VERSION ""

NS_ :

BS_:

BU_: WPC2 PSB SHVU_RR vHS_B2 FCS EMCU SLB GW_APSU GW_DLBCU RCM ARS CGW_CCU vDummy_HS_B GW_RLPSU ATS RLHV SGU PFSU GW_RRPSU ALBCU DSAU SWRC SHVU_FR RCS GW_DPSU BLTN_CAM SCM OHCL RWPC RRHV WPC HOD ASAU

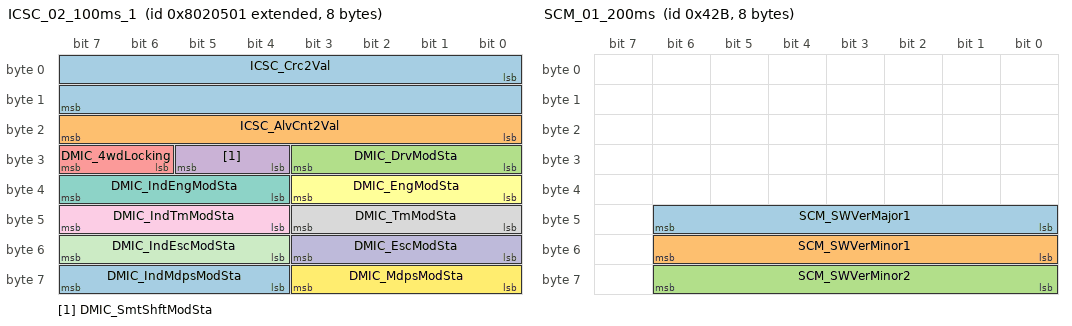
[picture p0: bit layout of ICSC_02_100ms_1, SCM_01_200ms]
BO_ 2281833729 ICSC_02_100ms_1: 8 CGW_CCU
 SG_ ICSC_Crc2Val : 0|16@1+ (1,0) [0|0] ""  Vector__XXX
 SG_ ICSC_AlvCnt2Val : 16|8@1+ (1,0) [0|0] ""  Vector__XXX
 SG_ DMIC_DrvModSta : 24|4@1+ (1,0) [0|0] ""  ALBCU,ASAU,DSAU,GW_APSU,GW_DLBCU
 SG_ DMIC_SmtShftModSta : 28|2@1+ (1,0) [0|0] ""  Vector__XXX
 SG_ DMIC_4wdLocking : 30|2@1+ (1,0) [0|0] ""  Vector__XXX
 SG_ DMIC_EngModSta : 32|4@1+ (1,0) [0|0] ""  Vector__XXX
 SG_ DMIC_IndEngModSta : 36|4@1+ (1,0) [0|0] ""  Vector__XXX
 SG_ DMIC_TmModSta : 40|4@1+ (1,0) [0|0] ""  Vector__XXX
 SG_ DMIC_IndTmModSta : 44|4@1+ (1,0) [0|0] ""  Vector__XXX
 SG_ DMIC_EscModSta : 48|4@1+ (1,0) [0|0] ""  Vector__XXX
 SG_ DMIC_IndEscModSta : 52|4@1+ (1,0) [0|0] ""  Vector__XXX
 SG_ DMIC_MdpsModSta : 56|4@1+ (1,0) [0|0] ""  Vector__XXX
 SG_ DMIC_IndMdpsModSta : 60|4@1+ (1,0) [0|0] ""  Vector__XXX

BO_ 1067 SCM_01_200ms: 8 SCM
 SG_ SCM_SWVerMajor1 : 40|7@1+ (1,0) [0|0] ""  CGW_CCU
 SG_ SCM_SWVerMinor1 : 48|7@1+ (1,0) [0|0] ""  CGW_CCU
 SG_ SCM_SWVerMinor2 : 56|7@1+ (1,0) [0|0] ""  CGW_CCU

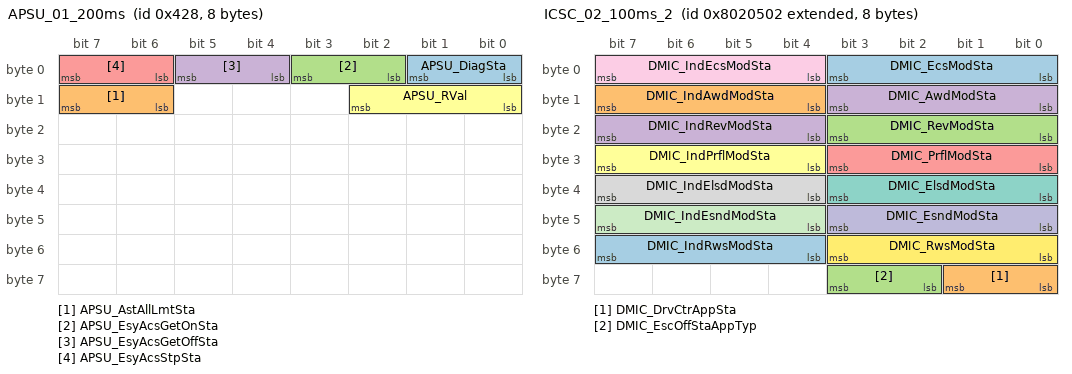
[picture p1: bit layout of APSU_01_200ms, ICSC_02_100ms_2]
BO_ 1064 APSU_01_200ms: 8 GW_APSU
 SG_ APSU_DiagSta : 0|2@1+ (1,0) [0|0] ""  Vector__XXX
 SG_ APSU_AstAllLmtSta : 14|2@1+ (1,0) [0|0] ""  Vector__XXX
 SG_ APSU_EsyAcsGetOnSta : 2|2@1+ (1,0) [0|0] ""  ALBCU,GW_RLPSU,GW_RRPSU
 SG_ APSU_EsyAcsGetOffSta : 4|2@1+ (1,0) [0|0] ""  ALBCU,GW_RLPSU,GW_RRPSU
 SG_ APSU_EsyAcsStpSta : 6|2@1+ (1,0) [0|0] ""  ALBCU,GW_RLPSU,GW_RRPSU
 SG_ APSU_RVal : 8|3@1+ (1,0) [0|0] ""  Vector__XXX

BO_ 2281833731 ICSC_02_100ms_3: 8 CGW_CCU
 SG_ DMIC_VcuModSta : 0|4@1+ (1,0) [0|0] ""  Vector__XXX
 SG_ DMIC_DrvModTyp : 12|4@1+ (1,0) [0|0] ""  Vector__XXX
 SG_ DMIC_EngFltSta : 16|2@1+ (1,0) [0|0] ""  Vector__XXX
 SG_ DMIC_TmFltSta : 18|2@1+ (1,0) [0|0] ""  Vector__XXX
 SG_ DMIC_EscFltSta : 20|2@1+ (1,0) [0|0] ""  Vector__XXX
 SG_ DMIC_MdpsFltSta : 22|2@1+ (1,0) [0|0] ""  Vector__XXX
 SG_ DMIC_EcsFltSta : 24|2@1+ (1,0) [0|0] ""  Vector__XXX
 SG_ DMIC_AwdFltSta : 26|2@1+ (1,0) [0|0] ""  Vector__XXX
 SG_ DMIC_RevFltSta : 28|2@1+ (1,0) [0|0] ""  Vector__XXX
 SG_ DMIC_PrflFltSta : 30|2@1+ (1,0) [0|0] ""  Vector__XXX
 SG_ DMIC_ElsdFltSta : 32|2@1+ (1,0) [0|0] ""  Vector__XXX
 SG_ DMIC_EsndFltSta : 34|2@1+ (1,0) [0|0] ""  Vector__XXX
 SG_ DMIC_RwsFltSta : 36|2@1+ (1,0) [0|0] ""  Vector__XXX
 SG_ DMIC_IndWhlDrvSta : 38|2@1+ (1,0) [0|0] ""  Vector__XXX
 SG_ DMIC_IndVcuModSta : 4|4@1+ (1,0) [0|0] ""  Vector__XXX
 SG_ DMIC_VcuFltSta : 40|2@1+ (1,0) [0|0] ""  Vector__XXX
 SG_ DMIC_IndMtrPwrSta : 42|3@1+ (1,0) [0|0] ""  Vector__XXX
 SG_ DMIC_IndAccSenSta : 45|3@1+ (1,0) [0|0] ""  Vector__XXX
 SG_ DMIC_TerrainModSwSta : 48|3@1+ (1,0) [0|0] ""  Vector__XXX
 SG_ DMIC_TerrainMainSwSta : 52|2@1+ (1,0) [0|0] ""  Vector__XXX
 SG_ DMIC_DrvModTypSta : 54|2@1+ (1,0) [0|0] ""  Vector__XXX
 SG_ DMIC_DrvngModSwSta : 56|4@1+ (1,0) [0|0] ""  Vector__XXX
 SG_ DMIC_DrvMod2Typ : 60|4@1+ (1,0) [0|0] ""  Vector__XXX
 SG_ DMIC_DrvModFltSta : 8|4@1+ (1,0) [0|0] ""  Vector__XXX

BO_ 2281833730 ICSC_02_100ms_2: 8 CGW_CCU
 SG_ DMIC_EcsModSta : 0|4@1+ (1,0) [0|0] ""  Vector__XXX
 SG_ DMIC_IndAwdModSta : 12|4@1+ (1,0) [0|0] ""  Vector__XXX
 SG_ DMIC_RevModSta : 16|4@1+ (1,0) [0|0] ""  Vector__XXX
 SG_ DMIC_IndRevModSta : 20|4@1+ (1,0) [0|0] ""  Vector__XXX
 SG_ DMIC_PrflModSta : 24|4@1+ (1,0) [0|0] ""  Vector__XXX
 SG_ DMIC_IndPrflModSta : 28|4@1+ (1,0) [0|0] ""  Vector__XXX
 SG_ DMIC_ElsdModSta : 32|4@1+ (1,0) [0|0] ""  Vector__XXX
 SG_ DMIC_IndElsdModSta : 36|4@1+ (1,0) [0|0] ""  Vector__XXX
 SG_ DMIC_IndEcsModSta : 4|4@1+ (1,0) [0|0] ""  Vector__XXX
 SG_ DMIC_EsndModSta : 40|4@1+ (1,0) [0|0] ""  Vector__XXX
 SG_ DMIC_IndEsndModSta : 44|4@1+ (1,0) [0|0] ""  Vector__XXX
 SG_ DMIC_RwsModSta : 48|4@1+ (1,0) [0|0] ""  Vector__XXX
 SG_ DMIC_IndRwsModSta : 52|4@1+ (1,0) [0|0] ""  Vector__XXX
 SG_ DMIC_DrvCtrAppSta : 56|2@1+ (1,0) [0|0] ""  Vector__XXX
 SG_ DMIC_EscOffStaAppTyp : 58|2@1+ (1,0) [0|0] ""  Vector__XXX
 SG_ DMIC_AwdModSta : 8|4@1+ (1,0) [0|0] ""  Vector__XXX

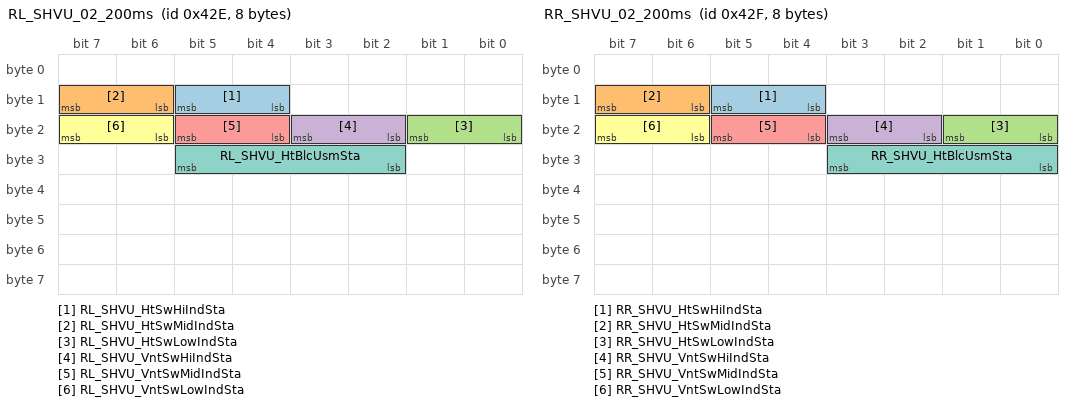
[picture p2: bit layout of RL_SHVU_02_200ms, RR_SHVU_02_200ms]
BO_ 1070 RL_SHVU_02_200ms: 8 GW_RLPSU
 SG_ RL_SHVU_HtSwHiIndSta : 12|2@1+ (1,0) [0|0] ""  ARS,ATS,CGW_CCU
 SG_ RL_SHVU_HtSwMidIndSta : 14|2@1+ (1,0) [0|0] ""  ARS,ATS,CGW_CCU
 SG_ RL_SHVU_HtSwLowIndSta : 16|2@1+ (1,0) [0|0] ""  ARS,ATS,CGW_CCU
 SG_ RL_SHVU_VntSwHiIndSta : 18|2@1+ (1,0) [0|0] ""  ARS,ATS,CGW_CCU
 SG_ RL_SHVU_VntSwMidIndSta : 20|2@1+ (1,0) [0|0] ""  ARS,ATS,CGW_CCU
 SG_ RL_SHVU_VntSwLowIndSta : 22|2@1+ (1,0) [0|0] ""  ARS,ATS,CGW_CCU
 SG_ RL_SHVU_HtBlcUsmSta : 26|4@1+ (1,0) [0|0] ""  ATS,CGW_CCU

BO_ 1071 RR_SHVU_02_200ms: 8 GW_RRPSU
 SG_ RR_SHVU_HtSwHiIndSta : 12|2@1+ (1,0) [0|0] ""  ARS,ATS,CGW_CCU
 SG_ RR_SHVU_HtSwMidIndSta : 14|2@1+ (1,0) [0|0] ""  ARS,ATS,CGW_CCU
 SG_ RR_SHVU_HtSwLowIndSta : 16|2@1+ (1,0) [0|0] ""  ARS,ATS,CGW_CCU
 SG_ RR_SHVU_VntSwHiIndSta : 18|2@1+ (1,0) [0|0] ""  ARS,ATS,CGW_CCU
 SG_ RR_SHVU_VntSwMidIndSta : 20|2@1+ (1,0) [0|0] ""  ARS,ATS,CGW_CCU
 SG_ RR_SHVU_VntSwLowIndSta : 22|2@1+ (1,0) [0|0] ""  ARS,ATS,CGW_CCU
 SG_ RR_SHVU_HtBlcUsmSta : 24|4@1+ (1,0) [0|0] ""  ATS,CGW_CCU

BO_ 1068 RLPSU_04_200ms: 8 RLHV
 SG_ RLPSU_ReclMtrPos : 0|3@1+ (1,0) [0|0] ""  PFSU
 SG_ RLPSU_RLSlidPos : 11|3@1+ (1,0) [0|0] ""  CGW_CCU
 SG_ RLPSU_RLRclPos : 14|3@1+ (1,0) [0|0] ""  CGW_CCU
 SG_ RLPSU_RLTiltPos : 17|3@1+ (1,0) [0|0] ""  CGW_CCU
 SG_ RLPSU_RLLegExtPos : 20|3@1+ (1,0) [0|0] ""  CGW_CCU
 SG_ RLPSU_RLLegSupPos : 23|3@1+ (1,0) [0|0] ""  CGW_CCU
 SG_ RLPSU_RLHrestSlidPos : 26|3@1+ (1,0) [0|0] ""  CGW_CCU
 SG_ RLPSU_RLHrestHeightPos : 29|3@1+ (1,0) [0|0] ""  CGW_CCU
 SG_ RLPSU_Opt : 3|2@1+ (1,0) [0|0] ""  CGW_CCU
 SG_ RLPSU_Opt_Captain : 32|2@1+ (1,0) [0|0] ""  CGW_CCU
 SG_ RL_AutoRlxSta : 34|2@1+ (1,0) [0|0] ""  GW_APSU,GW_DPSU,PFSU
 SG_ RL_FLStAutoRlxEnable : 36|2@1+ (1,0) [0|0] ""  GW_APSU,GW_DPSU
 SG_ RLHVU_Opt_Captain : 38|3@1+ (1,0) [0|0] ""  CGW_CCU
 SG_ RL_TLAutoFldEnable : 45|2@1+ (1,0) [0|0] ""  PFSU
 SG_ RL_AutoFoldSta : 47|2@1+ (1,0) [0|0] ""  GW_APSU,GW_DPSU
 SG_ RL_AutoWalkInSta : 49|2@1+ (1,0) [0|0] ""  GW_APSU,GW_DPSU
 SG_ RLPSU_PwrSeatOpt : 5|3@1+ (1,0) [0|0] ""  CGW_CCU
 SG_ RLPSU_PwrSeatPos : 8|3@1+ (1,0) [0|0] ""  CGW_CCU

BO_ 1069 RRPSU_04_200ms: 8 GW_RRPSU
 SG_ RRPSU_ReclMtrPos : 0|3@1+ (1,0) [0|0] ""  PFSU
 SG_ RRPSU_PwrSeatOpt : 11|3@1+ (1,0) [0|0] ""  CGW_CCU
 SG_ RRPSU_PwrSeatPos : 14|3@1+ (1,0) [0|0] ""  CGW_CCU
 SG_ RRPSU_RRSlidPos : 17|3@1+ (1,0) [0|0] ""  CGW_CCU
 SG_ RRPSU_RRRclPos : 20|3@1+ (1,0) [0|0] ""  CGW_CCU
 SG_ RRPSU_RRTiltPos : 23|3@1+ (1,0) [0|0] ""  CGW_CCU
 SG_ RRPSU_RRLegExtPos : 26|3@1+ (1,0) [0|0] ""  CGW_CCU
 SG_ RRPSU_RRLegSupPos : 29|3@1+ (1,0) [0|0] ""  CGW_CCU
 SG_ RRPSU_RRStEsyAcsUSMSta : 3|3@1+ (1,0) [0|0] ""  CGW_CCU
 SG_ RRPSU_RRHrestSlidPos : 32|3@1+ (1,0) [0|0] ""  CGW_CCU
 SG_ RRPSU_RRHrestHeightPos : 35|3@1+ (1,0) [0|0] ""  CGW_CCU
 SG_ RRPSU_Opt_Captain : 38|2@1+ (1,0) [0|0] ""  CGW_CCU
 SG_ RR_AutoRlxSta : 40|2@1+ (1,0) [0|0] ""  GW_APSU,GW_DPSU,PFSU
 SG_ RR_FRStAutoRlxEnable : 42|2@1+ (1,0) [0|0] ""  GW_APSU,GW_DPSU
 SG_ RRHVU_Opt_Captain : 44|3@1+ (1,0) [0|0] ""  CGW_CCU
 SG_ RR_AutoFoldSta : 51|2@1+ (1,0) [0|0] ""  GW_APSU,GW_DPSU
 SG_ RR_AutoWalkInSta : 53|2@1+ (1,0) [0|0] ""  GW_APSU,GW_DPSU
 SG_ RR_TRAutoFldEnable : 55|2@1+ (1,0) [0|0] ""  PFSU
 SG_ RRPSU_RLStEsyAcsUSMSta : 6|3@1+ (1,0) [0|0] ""  CGW_CCU
 SG_ RRPSU_Opt : 9|2@1+ (1,0) [0|0] ""  CGW_CCU

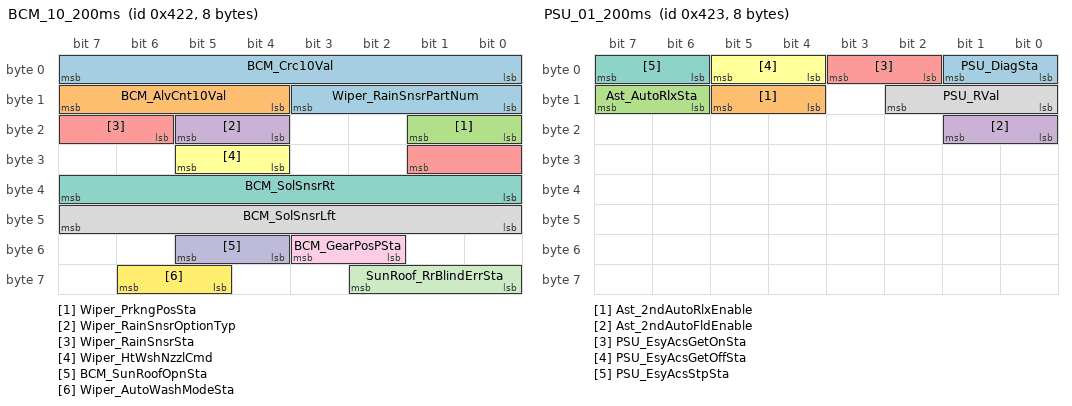
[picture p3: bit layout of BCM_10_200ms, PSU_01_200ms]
BO_ 1058 BCM_10_200ms: 8 CGW_CCU
 SG_ BCM_Crc10Val : 0|8@1+ (1,0) [0|0] ""  Vector__XXX
 SG_ BCM_AlvCnt10Val : 12|4@1+ (1,0) [0|0] ""  Vector__XXX
 SG_ Wiper_PrkngPosSta : 16|2@1+ (1,0) [0|0] ""  BLTN_CAM
 SG_ Wiper_RainSnsrOptionTyp : 20|2@1+ (1,0) [0|0] ""  Vector__XXX
 SG_ Wiper_RainSnsrSta : 22|4@1+ (1,0) [0|0] ""  BLTN_CAM
 SG_ Wiper_HtWshNzzlCmd : 28|2@1+ (1,0) [0|0] ""  Vector__XXX
 SG_ BCM_SolSnsrRt : 32|8@1+ (4.72441,0) [0|0] "W/m2"  Vector__XXX
 SG_ BCM_SolSnsrLft : 40|8@1+ (4.72441,0) [0|0] "W/m2"  Vector__XXX
 SG_ BCM_GearPosPSta : 50|2@1+ (1,0) [0|0] ""  ATS,GW_APSU,GW_DPSU,GW_RLPSU,GW_RRPSU,PFSU,RLHV,RRHV,SCM
 SG_ BCM_SunRoofOpnSta : 52|2@1+ (1,0) [0|0] ""  Vector__XXX
 SG_ SunRoof_RrBlindErrSta : 56|3@1+ (1,0) [0|0] ""  Vector__XXX
 SG_ Wiper_AutoWashModeSta : 61|2@1+ (1,0) [0|0] ""  Vector__XXX
 SG_ Wiper_RainSnsrPartNum : 8|4@1+ (1,0) [0|0] ""  Vector__XXX

BO_ 1059 PSU_01_200ms: 8 GW_APSU
 SG_ PSU_DiagSta : 0|2@1+ (1,0) [0|0] ""  Vector__XXX
 SG_ Ast_2ndAutoRlxEnable : 12|2@1+ (1,0) [0|0] ""  GW_RLPSU,GW_RRPSU
 SG_ Ast_AutoRlxSta : 14|2@1+ (1,0) [0|0] ""  GW_RLPSU,GW_RRPSU
 SG_ Ast_2ndAutoFldEnable : 16|2@1+ (1,0) [0|0] ""  GW_RLPSU,GW_RRPSU
 SG_ PSU_EsyAcsGetOnSta : 2|2@1+ (1,0) [0|0] ""  SLB
 SG_ PSU_EsyAcsGetOffSta : 4|2@1+ (1,0) [0|0] ""  SLB
 SG_ PSU_EsyAcsStpSta : 6|2@1+ (1,0) [0|0] ""  SLB
 SG_ PSU_RVal : 8|3@1+ (1,0) [0|0] ""  Vector__XXX

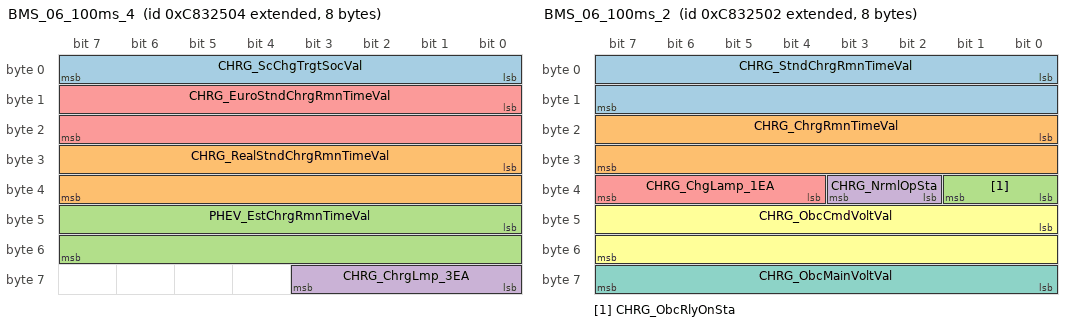
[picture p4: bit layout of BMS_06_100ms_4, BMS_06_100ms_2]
BO_ 2357404932 BMS_06_100ms_4: 8 CGW_CCU
 SG_ CHRG_ScChgTrgtSocVal : 0|8@1+ (0.5,0) [0|0] "%"  Vector__XXX
 SG_ CHRG_RealStndChrgRmnTimeVal : 24|16@1+ (1,0) [0|0] "minute"  Vector__XXX
 SG_ PHEV_EstChrgRmnTimeVal : 40|16@1+ (1,0) [0|0] "min"  Vector__XXX
 SG_ CHRG_ChrgLmp_3EA : 56|4@1+ (1,0) [0|0] "minute"  Vector__XXX
 SG_ CHRG_EuroStndChrgRmnTimeVal : 8|16@1+ (1,0) [0|0] "minute"  Vector__XXX

BO_ 2357404930 BMS_06_100ms_2: 8 CGW_CCU
 SG_ CHRG_StndChrgRmnTimeVal : 0|16@1+ (1,0) [0|0] "minute"  Vector__XXX
 SG_ CHRG_ChrgRmnTimeVal : 16|16@1+ (1,0) [0|0] "min"  Vector__XXX
 SG_ CHRG_ObcRlyOnSta : 32|2@1+ (1,0) [0|0] ""  Vector__XXX
 SG_ CHRG_NrmlOpSta : 34|2@1+ (1,0) [0|0] ""  Vector__XXX
 SG_ CHRG_ChgLamp_1EA : 36|4@1+ (1,0) [0|0] ""  Vector__XXX
 SG_ CHRG_ObcCmdVoltVal : 40|16@1+ (0.1,0) [0|0] "V"  Vector__XXX
 SG_ CHRG_ObcMainVoltVal : 56|8@1+ (2,0) [0|0] "V"  Vector__XXX

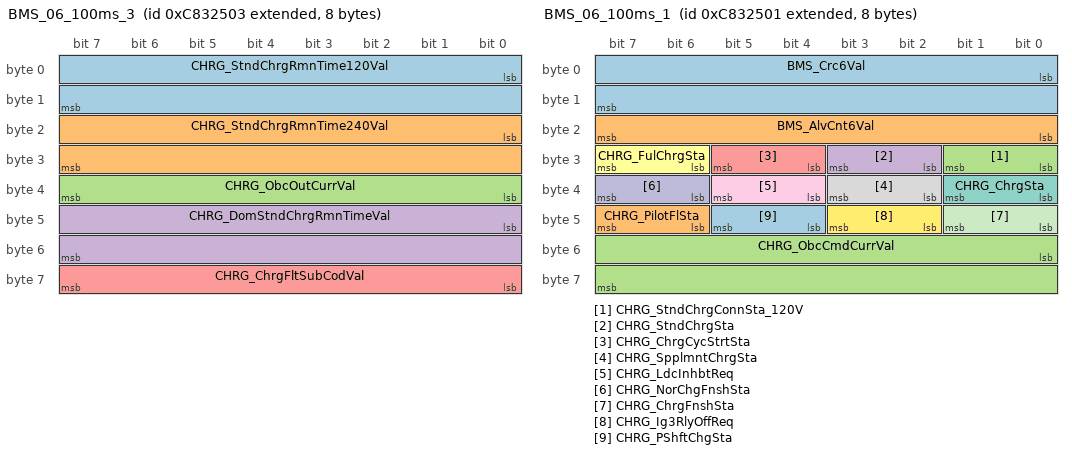
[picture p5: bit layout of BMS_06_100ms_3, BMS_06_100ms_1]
BO_ 2357404931 BMS_06_100ms_3: 8 CGW_CCU
 SG_ CHRG_StndChrgRmnTime120Val : 0|16@1+ (1,0) [0|0] "minute"  Vector__XXX
 SG_ CHRG_StndChrgRmnTime240Val : 16|16@1+ (1,0) [0|0] "minute"  Vector__XXX
 SG_ CHRG_ObcOutCurrVal : 32|8@1+ (0.1,0) [0|0] "A"  Vector__XXX
 SG_ CHRG_DomStndChrgRmnTimeVal : 40|16@1+ (1,0) [0|0] "minute"  Vector__XXX
 SG_ CHRG_ChrgFltSubCodVal : 56|8@1+ (1,0) [0|0] ""  Vector__XXX

BO_ 2357404929 BMS_06_100ms_1: 8 CGW_CCU
 SG_ BMS_Crc6Val : 0|16@1+ (1,0) [0|0] ""  Vector__XXX
 SG_ BMS_AlvCnt6Val : 16|8@1+ (1,0) [0|0] ""  Vector__XXX
 SG_ CHRG_StndChrgConnSta_120V : 24|2@1+ (1,0) [0|0] "flag"  Vector__XXX
 SG_ CHRG_StndChrgSta : 26|2@1+ (1,0) [0|0] ""  Vector__XXX
 SG_ CHRG_ChrgCycStrtSta : 28|2@1+ (1,0) [0|0] ""  Vector__XXX
 SG_ CHRG_FulChrgSta : 30|2@1+ (1,0) [0|0] ""  Vector__XXX
 SG_ CHRG_ChrgSta : 32|2@1+ (1,0) [0|0] ""  SWRC
 SG_ CHRG_SpplmntChrgSta : 34|2@1+ (1,0) [0|0] ""  Vector__XXX
 SG_ CHRG_LdcInhbtReq : 36|2@1+ (1,0) [0|0] ""  Vector__XXX
 SG_ CHRG_NorChgFnshSta : 38|2@1+ (1,0) [0|0] ""  Vector__XXX
 SG_ CHRG_ChrgFnshSta : 40|2@1+ (1,0) [0|0] ""  Vector__XXX
 SG_ CHRG_Ig3RlyOffReq : 42|2@1+ (1,0) [0|0] ""  Vector__XXX
 SG_ CHRG_PShftChgSta : 44|2@1+ (1,0) [0|0] "flag"  Vector__XXX
 SG_ CHRG_PilotFlSta : 46|2@1+ (1,0) [0|0] "flag"  Vector__XXX
 SG_ CHRG_ObcCmdCurrVal : 48|16@1+ (0.1,0) [0|0] "A"  Vector__XXX

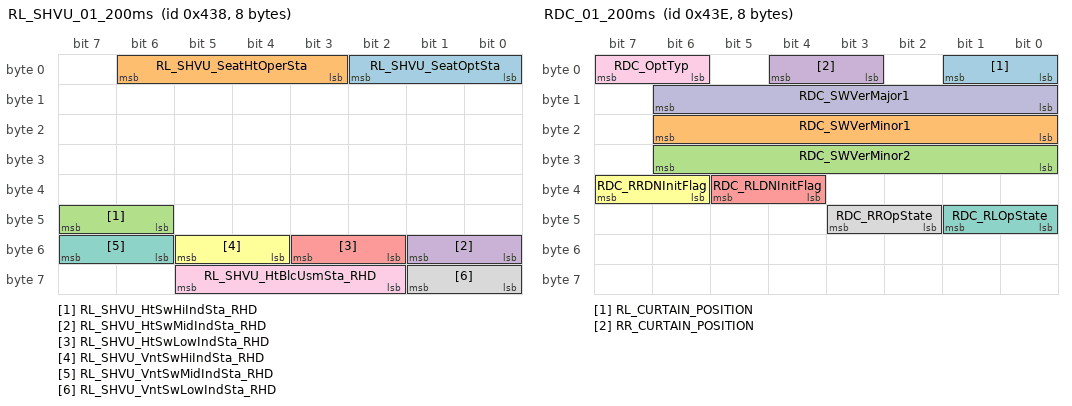
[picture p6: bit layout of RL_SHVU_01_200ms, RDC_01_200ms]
BO_ 1080 RL_SHVU_01_200ms: 8 SHVU_RR
 SG_ RL_SHVU_SeatOptSta : 0|3@1+ (1,0) [0|0] ""  ATS,CGW_CCU
 SG_ RL_SHVU_SeatHtOperSta : 3|4@1+ (1,0) [0|0] ""  ATS,CGW_CCU,FCS
 SG_ RL_SHVU_HtSwHiIndSta_RHD : 46|2@1+ (1,0) [0|0] ""  ATS,CGW_CCU
 SG_ RL_SHVU_HtSwMidIndSta_RHD : 48|2@1+ (1,0) [0|0] ""  ATS,CGW_CCU
 SG_ RL_SHVU_HtSwLowIndSta_RHD : 50|2@1+ (1,0) [0|0] ""  ATS,CGW_CCU
 SG_ RL_SHVU_VntSwHiIndSta_RHD : 52|2@1+ (1,0) [0|0] ""  ATS,CGW_CCU
 SG_ RL_SHVU_VntSwMidIndSta_RHD : 54|2@1+ (1,0) [0|0] ""  ATS,CGW_CCU
 SG_ RL_SHVU_VntSwLowIndSta_RHD : 56|2@1+ (1,0) [0|0] ""  ATS,CGW_CCU
 SG_ RL_SHVU_HtBlcUsmSta_RHD : 58|4@1+ (1,0) [0|0] ""  ATS,CGW_CCU

BO_ 1086 RDC_01_200ms: 8 CGW_CCU
 SG_ RL_CURTAIN_POSITION : 0|2@1+ (1,0) [0|0] ""  ATS
 SG_ RDC_SWVerMinor1 : 16|7@1+ (1,0) [0|0] ""  Vector__XXX
 SG_ RDC_SWVerMinor2 : 24|7@1+ (1,0) [0|0] ""  Vector__XXX
 SG_ RR_CURTAIN_POSITION : 3|2@1+ (1,0) [0|0] ""  ATS
 SG_ RDC_RLDNInitFlag : 36|2@1+ (1,0) [0|0] ""  Vector__XXX
 SG_ RDC_RRDNInitFlag : 38|2@1+ (1,0) [0|0] ""  Vector__XXX
 SG_ RDC_RLOpState : 40|2@1+ (1,0) [0|0] ""  Vector__XXX
 SG_ RDC_RROpState : 42|2@1+ (1,0) [0|0] ""  Vector__XXX
 SG_ RDC_OptTyp : 6|2@1+ (1,0) [0|0] ""  ATS
 SG_ RDC_SWVerMajor1 : 8|7@1+ (1,0) [0|0] ""  Vector__XXX

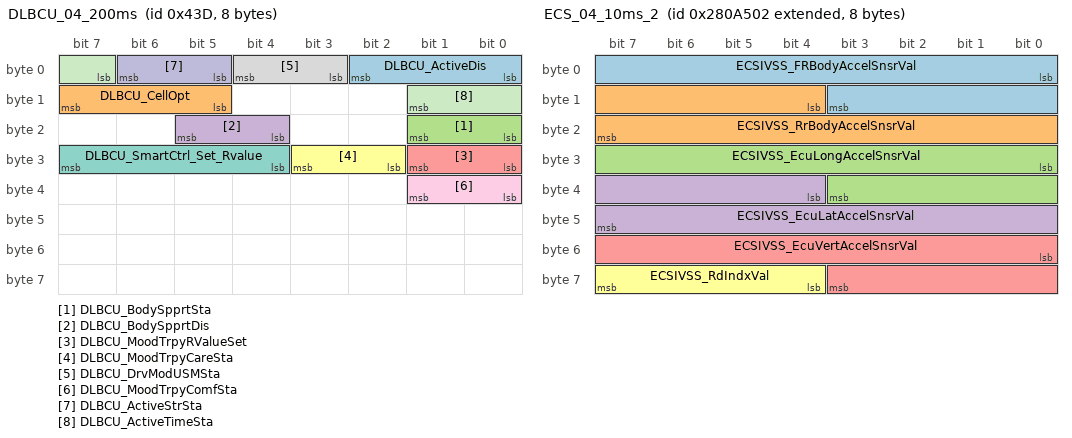
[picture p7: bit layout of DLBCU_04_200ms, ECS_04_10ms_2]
BO_ 1085 DLBCU_04_200ms: 8 GW_DLBCU
 SG_ DLBCU_ActiveDis : 0|3@1+ (1,0) [0|0] ""  CGW_CCU,GW_DPSU
 SG_ DLBCU_CellOpt : 13|3@1+ (1,0) [0|0] ""  Vector__XXX
 SG_ DLBCU_BodySpprtSta : 16|2@1+ (1,0) [0|0] ""  CGW_CCU
 SG_ DLBCU_BodySpprtDis : 20|2@1+ (1,0) [0|0] ""  CGW_CCU
 SG_ DLBCU_MoodTrpyRValueSet : 24|2@1+ (1,0) [0|0] ""  CGW_CCU
 SG_ DLBCU_MoodTrpyCareSta : 26|2@1+ (1,0) [0|0] ""  CGW_CCU
 SG_ DLBCU_SmartCtrl_Set_Rvalue : 28|4@1+ (1,0) [0|0] ""  CGW_CCU
 SG_ DLBCU_DrvModUSMSta : 3|2@1+ (1,0) [0|0] ""  CGW_CCU
 SG_ DLBCU_MoodTrpyComfSta : 32|2@1+ (1,0) [0|0] ""  CGW_CCU
 SG_ DLBCU_ActiveStrSta : 5|2@1+ (1,0) [0|0] ""  CGW_CCU
 SG_ DLBCU_ActiveTimeSta : 7|3@1+ (1,0) [0|0] ""  CGW_CCU

BO_ 2189468930 ECS_04_10ms_2: 8 CGW_CCU
 SG_ ECSIVSS_FRBodyAccelSnsrVal : 0|12@1+ (0.002442,-1.250304) [0|0] "g"  Vector__XXX
 SG_ ECSIVSS_RrBodyAccelSnsrVal : 12|12@1+ (0.002442,-1.250304) [0|0] "g"  Vector__XXX
 SG_ ECSIVSS_EcuLongAccelSnsrVal : 24|12@1+ (0.01,-20.48) [0|0] "m/s^2"  Vector__XXX
 SG_ ECSIVSS_EcuLatAccelSnsrVal : 36|12@1+ (0.01,-20.48) [0|0] "m/s^2"  Vector__XXX
 SG_ ECSIVSS_EcuVertAccelSnsrVal : 48|12@1+ (0.01,-20.48) [0|0] "m/s^2"  Vector__XXX
 SG_ ECSIVSS_RdIndxVal : 60|4@1+ (1,0) [0|0] ""  Vector__XXX

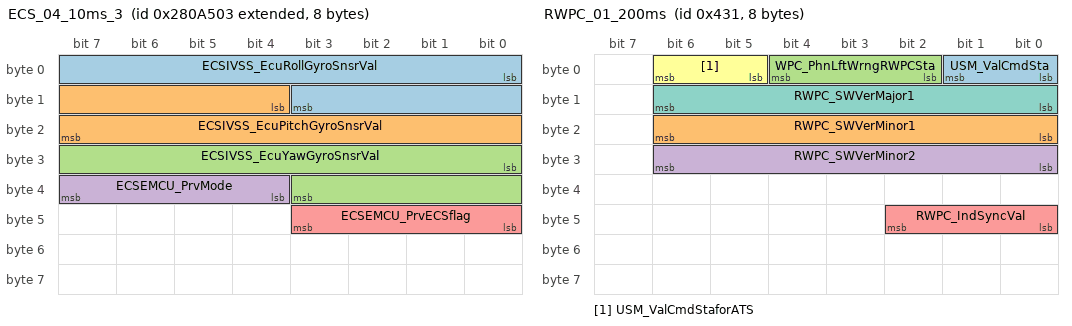
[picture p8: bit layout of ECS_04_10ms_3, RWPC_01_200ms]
BO_ 2189468931 ECS_04_10ms_3: 8 CGW_CCU
 SG_ ECSIVSS_EcuRollGyroSnsrVal : 0|12@1+ (0.1,-204.8) [0|0] "deg/s"  Vector__XXX
 SG_ ECSIVSS_EcuPitchGyroSnsrVal : 12|12@1+ (0.1,-204.8) [0|0] "deg/s"  Vector__XXX
 SG_ ECSIVSS_EcuYawGyroSnsrVal : 24|12@1+ (0.1,-204.8) [0|0] "deg/s"  Vector__XXX
 SG_ ECSEMCU_PrvMode : 36|4@1+ (1,0) [0|0] ""  EMCU
 SG_ ECSEMCU_PrvECSflag : 40|4@1+ (1,0) [0|0] ""  EMCU

BO_ 1073 RWPC_01_200ms: 8 RWPC
 SG_ USM_ValCmdSta : 0|2@1+ (1,0) [0|0] ""  ATS,CGW_CCU
 SG_ RWPC_SWVerMinor1 : 16|7@1+ (1,0) [0|0] ""  CGW_CCU
 SG_ WPC_PhnLftWrngRWPCSta : 2|3@1+ (1,0) [0|0] ""  ATS,CGW_CCU
 SG_ RWPC_SWVerMinor2 : 24|7@1+ (1,0) [0|0] ""  CGW_CCU
 SG_ RWPC_IndSyncVal : 40|3@1+ (1,0) [0|0] ""  WPC,WPC2
 SG_ USM_ValCmdStaforATS : 5|2@1+ (1,0) [0|0] ""  ATS
 SG_ RWPC_SWVerMajor1 : 8|7@1+ (1,0) [0|0] ""  CGW_CCU

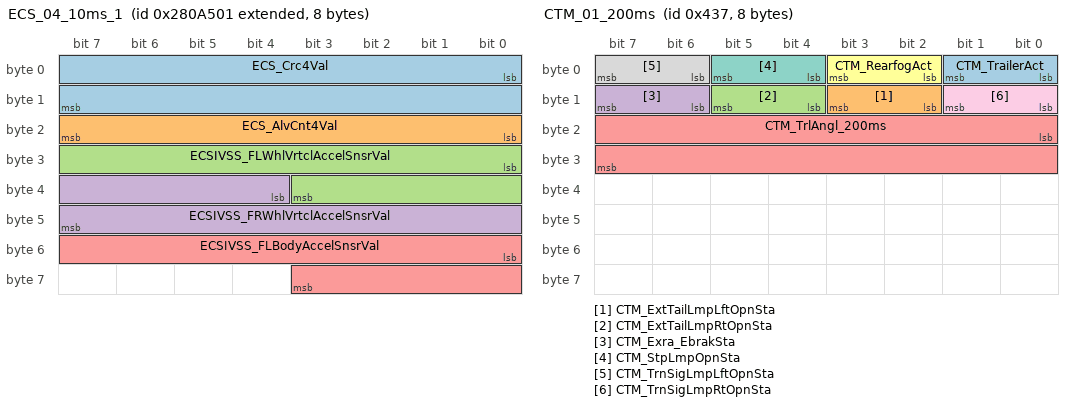
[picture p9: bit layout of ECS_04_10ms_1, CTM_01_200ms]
BO_ 2189468929 ECS_04_10ms_1: 8 CGW_CCU
 SG_ ECS_Crc4Val : 0|16@1+ (1,0) [0|0] ""  Vector__XXX
 SG_ ECS_AlvCnt4Val : 16|8@1+ (1,0) [0|0] ""  Vector__XXX
 SG_ ECSIVSS_FLWhlVrtclAccelSnsrVal : 24|12@1+ (0.03247863,-16.62905856) [0|0] "g"  EMCU
 SG_ ECSIVSS_FRWhlVrtclAccelSnsrVal : 36|12@1+ (0.03247863,-16.62905856) [0|0] "g"  EMCU
 SG_ ECSIVSS_FLBodyAccelSnsrVal : 48|12@1+ (0.002442,-1.250304) [0|0] "g"  Vector__XXX

BO_ 1079 CTM_01_200ms: 8 CGW_CCU
 SG_ CTM_TrailerAct : 0|2@1+ (1,0) [0|0] ""  BLTN_CAM
 SG_ CTM_ExtTailLmpLftOpnSta : 10|2@1+ (1,0) [0|0] ""  Vector__XXX
 SG_ CTM_ExtTailLmpRtOpnSta : 12|2@1+ (1,0) [0|0] ""  Vector__XXX
 SG_ CTM_Exra_EbrakSta : 14|2@1+ (1,0) [0|0] ""  Vector__XXX
 SG_ CTM_TrlAngl_200ms : 16|16@1+ (0.0055,-180) [0|0] ""  Vector__XXX
 SG_ CTM_RearfogAct : 2|2@1+ (1,0) [0|0] ""  Vector__XXX
 SG_ CTM_StpLmpOpnSta : 4|2@1+ (1,0) [0|0] ""  Vector__XXX
 SG_ CTM_TrnSigLmpLftOpnSta : 6|2@1+ (1,0) [0|0] ""  Vector__XXX
 SG_ CTM_TrnSigLmpRtOpnSta : 8|2@1+ (1,0) [0|0] ""  Vector__XXX

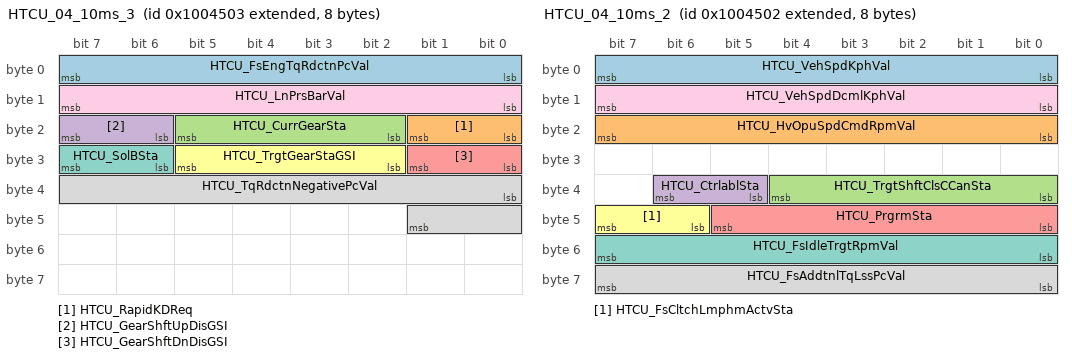
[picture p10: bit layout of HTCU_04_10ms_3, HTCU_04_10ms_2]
BO_ 2164278531 HTCU_04_10ms_3: 8 CGW_CCU
 SG_ HTCU_FsEngTqRdctnPcVal : 0|8@1+ (0.390625,0) [0|0] "%"  Vector__XXX
 SG_ HTCU_RapidKDReq : 16|2@1+ (1,0) [0|0] ""  Vector__XXX
 SG_ HTCU_CurrGearSta : 18|4@1+ (1,0) [0|0] ""  Vector__XXX
 SG_ HTCU_GearShftUpDisGSI : 22|2@1+ (1,0) [0|0] ""  Vector__XXX
 SG_ HTCU_GearShftDnDisGSI : 24|2@1+ (1,0) [0|0] ""  Vector__XXX
 SG_ HTCU_TrgtGearStaGSI : 26|4@1+ (1,0) [0|0] ""  Vector__XXX
 SG_ HTCU_SolBSta : 30|2@1+ (1,0) [0|0] ""  Vector__XXX
 SG_ HTCU_TqRdctnNegativePcVal : 32|10@1- (0.390625,0) [0|0] "rpm"  Vector__XXX
 SG_ HTCU_LnPrsBarVal : 8|8@1+ (0.1,0) [0|0] "Bar"  Vector__XXX

BO_ 2164278530 HTCU_04_10ms_2: 8 CGW_CCU
 SG_ HTCU_VehSpdKphVal : 0|8@1+ (1,0) [0|0] "kph"  Vector__XXX
 SG_ HTCU_HvOpuSpdCmdRpmVal : 16|8@1+ (20,0) [0|0] "rpm"  Vector__XXX
 SG_ HTCU_TrgtShftClsCCanSta : 32|5@1+ (1,0) [0|0] ""  Vector__XXX
 SG_ HTCU_CtrlablSta : 37|2@1+ (1,0) [0|0] ""  Vector__XXX
 SG_ HTCU_PrgrmSta : 40|6@1+ (1,0) [0|0] ""  Vector__XXX
 SG_ HTCU_FsCltchLmphmActvSta : 46|2@1+ (1,0) [0|0] ""  Vector__XXX
 SG_ HTCU_FsIdleTrgtRpmVal : 48|8@1+ (10,0) [0|0] "rpm"  Vector__XXX
 SG_ HTCU_FsAddtnlTqLssPcVal : 56|8@1+ (0.390625,0) [0|0] "%"  Vector__XXX
 SG_ HTCU_VehSpdDcmlKphVal : 8|8@1+ (0.0078125,0) [0|0] "kph"  Vector__XXX

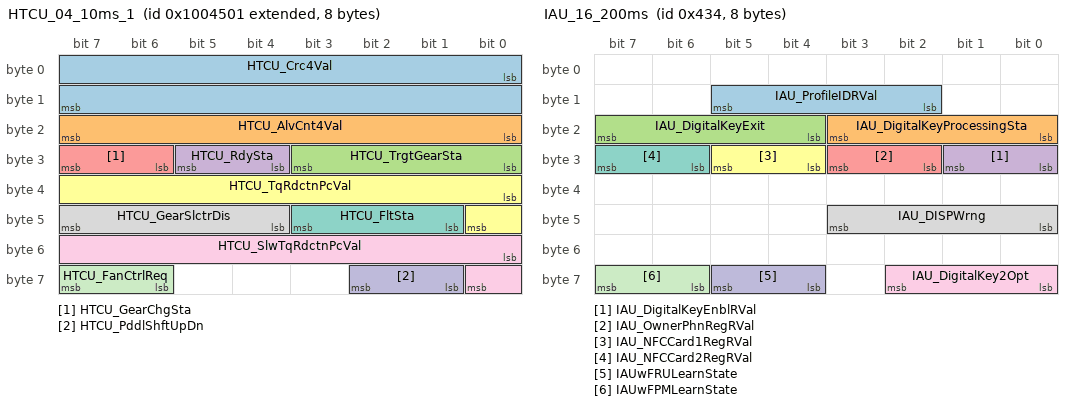
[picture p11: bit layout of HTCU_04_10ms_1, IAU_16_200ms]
BO_ 2164278529 HTCU_04_10ms_1: 8 CGW_CCU
 SG_ HTCU_Crc4Val : 0|16@1+ (1,0) [0|0] ""  Vector__XXX
 SG_ HTCU_AlvCnt4Val : 16|8@1+ (1,0) [0|0] ""  Vector__XXX
 SG_ HTCU_TrgtGearSta : 24|4@1+ (1,0) [0|0] ""  Vector__XXX
 SG_ HTCU_RdySta : 28|2@1+ (1,0) [0|0] ""  Vector__XXX
 SG_ HTCU_GearChgSta : 30|2@1+ (1,0) [0|0] ""  Vector__XXX
 SG_ HTCU_TqRdctnPcVal : 32|9@1+ (0.390625,0) [0|0] "%"  Vector__XXX
 SG_ HTCU_FltSta : 41|3@1+ (1,0) [0|0] ""  Vector__XXX
 SG_ HTCU_GearSlctrDis : 44|4@1+ (1,0) [0|0] ""  BLTN_CAM,GW_APSU,GW_DPSU,GW_RLPSU,GW_RRPSU,PFSU,SWRC
 SG_ HTCU_SlwTqRdctnPcVal : 48|9@1+ (0.390625,0) [0|0] "%"  Vector__XXX
 SG_ HTCU_PddlShftUpDn : 57|2@1+ (1,0) [0|0] ""  Vector__XXX
 SG_ HTCU_FanCtrlReq : 62|2@1+ (1,0) [0|0] ""  Vector__XXX

BO_ 1076 IAU_16_200ms: 8 CGW_CCU
 SG_ IAU_ProfileIDRVal : 10|4@1+ (1,0) [0|0] ""  BLTN_CAM,GW_DLBCU,GW_DPSU,RCM,RWPC,SGU,WPC,WPC2
 SG_ IAU_DigitalKeyProcessingSta : 16|4@1+ (1,0) [0|0] ""  Vector__XXX
 SG_ IAU_DigitalKeyExit : 20|4@1+ (1,0) [0|0] ""  Vector__XXX
 SG_ IAU_DigitalKeyEnblRVal : 24|2@1+ (1,0) [0|0] ""  Vector__XXX
 SG_ IAU_OwnerPhnRegRVal : 26|2@1+ (1,0) [0|0] ""  Vector__XXX
 SG_ IAU_NFCCard1RegRVal : 28|2@1+ (1,0) [0|0] ""  Vector__XXX
 SG_ IAU_NFCCard2RegRVal : 30|2@1+ (1,0) [0|0] ""  Vector__XXX
 SG_ IAU_DISPWrng : 40|4@1+ (1,0) [0|0] ""  Vector__XXX
 SG_ IAU_DigitalKey2Opt : 56|3@1+ (1,0) [0|0] ""  WPC,WPC2
 SG_ IAUwFRULearnState : 60|2@1+ (1,0) [0|0] ""  Vector__XXX
 SG_ IAUwFPMLearnState : 62|2@1+ (1,0) [0|0] ""  Vector__XXX

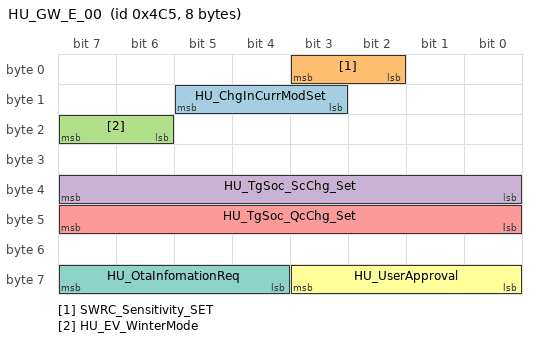
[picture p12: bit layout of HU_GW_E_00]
BO_ 1221 HU_GW_E_00: 8 CGW_CCU
 SG_ HU_ChgInCurrModSet : 11|3@1+ (1,0) [0|0] ""  Vector__XXX
 SG_ SWRC_Sensitivity_SET : 2|2@1+ (1,0) [0|0] ""  SWRC
 SG_ HU_EV_WinterMode : 22|2@1+ (1,0) [0|0] ""  Vector__XXX
 SG_ HU_TgSoc_ScChg_Set : 32|8@1+ (0.5,0) [0|100] "%"  Vector__XXX
 SG_ HU_TgSoc_QcChg_Set : 40|8@1+ (0.5,0) [0|100] "%"  Vector__XXX
 SG_ HU_UserApproval : 56|4@1+ (1,0) [0|0] ""  Vector__XXX
 SG_ HU_OtaInfomationReq : 60|4@1+ (1,0) [0|0] ""  Vector__XXX

BO_TX_BU_ 1070 : GW_RLPSU,SHVU_RR,RLHV,SHVU_FR;
BO_TX_BU_ 1071 : GW_RRPSU,RRHV,SHVU_FR,SHVU_RR;
BO_TX_BU_ 1068 : RLHV,GW_RLPSU,GW_RRPSU;
BO_TX_BU_ 1069 : GW_RRPSU,RRHV;
BO_TX_BU_ 1080 : SHVU_RR,SHVU_FR,GW_RLPSU,RLHV;
CM_ BO_ 1064 "[PE] Periodic and On Event";
CM_ SG_ 1064 APSU_DiagSta "APSU_DiagnosticStatus";
CM_ SG_ 1064 APSU_EsyAcsGetOnSta "APSU_EasyAccessGetOnStatus";
CM_ SG_ 1064 APSU_EsyAcsGetOffSta "APSU_EasyAccessGetOffStatus";
CM_ SG_ 1064 APSU_EsyAcsStpSta "APSU_EasyAccessStopStatus";
CM_ SG_ 1064 APSU_RVal "APSU_RValue";
CM_ BO_ 1058 "[PE] Periodic and On Event";
CM_ SG_ 1058 BCM_Crc10Val "BCM_CyclicRedundancyCheck10Value";
CM_ SG_ 1058 BCM_AlvCnt10Val "BCM_AliveCounter10Value";
CM_ SG_ 1058 Wiper_PrkngPosSta "Wiper_ParkingPositionStatus ##2G##BCM - BCMmsg22 - C_WiperParkPosition";
CM_ SG_ 1058 Wiper_RainSnsrOptionTyp "Wiper_RainSensorOptionType ##2G##BCM - BCMmsg24 - C_RainSnsOption";
CM_ SG_ 1058 Wiper_RainSnsrSta "Wiper_RainSensorStatus ##2G##BCM - BCMmsg24 - C_RainSnsState";
CM_ SG_ 1058 BCM_SolSnsrRt "BCM_SolarSensorRightOutputVoltageValue ##2G##BCM - BCMmsg24 - C_PhotosensorRH";
CM_ SG_ 1058 BCM_SolSnsrLft "BCM_SolarSensorLeftOutputVoltageValue ##2G##BCM - BCMmsg24 - C_PhotosensorLH";
CM_ SG_ 1058 BCM_GearPosPSta "BCM_GearPositionPStatus ##2G##BCM - BCMmsg17 - C_PpositiOn";
CM_ SG_ 1058 BCM_SunRoofOpnSta "BCM_SunRoofOpenStatus ##2G##BCM - BCMmsg20 - C_SunRoofOpenState";
CM_ SG_ 1058 Wiper_AutoWashModeSta "Auto Wash Mode Wiper State";
CM_ BO_ 2357404929 "[P] Periodic";
CM_ SG_ 2357404929 BMS_Crc6Val "BMS_CyclicRedundancyCheck6Value";
CM_ SG_ 2357404929 BMS_AlvCnt6Val "BMS_AliveCounter6Value";
CM_ SG_ 2357404929 CHRG_StndChrgConnSta_120V "CHRG_StandardChargeConnectStatus";
CM_ SG_ 2357404929 CHRG_StndChrgSta "CHRG_StandardChargeStatus";
CM_ SG_ 2357404929 CHRG_ChrgCycStrtSta "CHRG_ChargingCycleStartStatus";
CM_ SG_ 2357404929 CHRG_FulChrgSta "CHRG_FullyChargeStatus";
CM_ SG_ 2357404929 CHRG_ChrgSta "CHRG_ChargeStatus";
CM_ SG_ 2357404929 CHRG_SpplmntChrgSta "CHRG_SupplementaryChargeStatus";
CM_ SG_ 2357404929 CHRG_LdcInhbtReq "CHRG_LdcInhibitRequest";
CM_ SG_ 2357404929 CHRG_NorChgFnshSta "CHRG_ChargeNormalFinishConditionStatus";
CM_ SG_ 2357404929 CHRG_ChrgFnshSta "CHRG_ChargeFinishStatus";
CM_ SG_ 2357404929 CHRG_Ig3RlyOffReq "CHRG_Ig3RelayOffRequest";
CM_ SG_ 2357404929 CHRG_PShftChgSta "CHRG_PShiftChangeStatus";
CM_ SG_ 2357404929 CHRG_PilotFlSta "CHRG_PilotlineFailStatus";
CM_ SG_ 2357404929 CHRG_ObcCmdCurrVal "CHRG_ObcCommandCurrentValue";
CM_ BO_ 2357404930 "[P] Periodic";
CM_ SG_ 2357404930 CHRG_StndChrgRmnTimeVal "CHRG_StandardChargeRemainedTimeValue";
CM_ SG_ 2357404930 CHRG_ChrgRmnTimeVal "CHRG_ChargeRemainedTimeValue";
CM_ SG_ 2357404930 CHRG_ObcRlyOnSta "CHRG_ObcRelayOnStatus";
CM_ SG_ 2357404930 CHRG_NrmlOpSta "CHRG_NormalOperationStatus";
CM_ SG_ 2357404930 CHRG_ChgLamp_1EA "CHRG_ChargeLampRequest (1EA Lamp)";
CM_ SG_ 2357404930 CHRG_ObcCmdVoltVal "CHRG_ObcCommandVoltageValue";
CM_ SG_ 2357404930 CHRG_ObcMainVoltVal "CHRG_ObcMainVoltageValue";
CM_ BO_ 2357404931 "[P] Periodic";
CM_ SG_ 2357404931 CHRG_StndChrgRmnTime120Val "CHRG_StandardChargeRemainedTime120Value";
CM_ SG_ 2357404931 CHRG_StndChrgRmnTime240Val "CHRG_StandardChargeRemainedTime240Value";
CM_ SG_ 2357404931 CHRG_ObcOutCurrVal "CHRG_ObcOutputCurrentValue";
CM_ SG_ 2357404931 CHRG_DomStndChrgRmnTimeVal "CHRG_DomesticStandardChargeRemainedTime";
CM_ SG_ 2357404931 CHRG_ChrgFltSubCodVal "CHRG_ChargeFaultSubCodeValue";
CM_ BO_ 2357404932 "[P] Periodic";
CM_ SG_ 2357404932 CHRG_ScChgTrgtSocVal "CHRG_TargetStateOfScChargeValue";
CM_ SG_ 2357404932 CHRG_RealStndChrgRmnTimeVal "CHRG_RealStandardChargeRemainedTime";
CM_ SG_ 2357404932 PHEV_EstChrgRmnTimeVal "PHEV_EstimatedChargeRemainedTimeValue";
CM_ SG_ 2357404932 CHRG_ChrgLmp_3EA "CHRG_Charge Lamp(3EA Lamp)";
CM_ SG_ 2357404932 CHRG_EuroStndChrgRmnTimeVal "CHRG_EuroStandardChargeRemainedTime";
CM_ BO_ 1079 "[PE] Periodic and On Event";
CM_ SG_ 1079 CTM_TrailerAct "This signal is used for control the Trailer Act function.";
CM_ SG_ 1079 CTM_ExtTailLmpLftOpnSta "Trailer Exterior Tail Lamp Left OpenStatus";
CM_ SG_ 1079 CTM_ExtTailLmpRtOpnSta "Trailer Exterior Tail Lamp Right OpenStatus";
CM_ SG_ 1079 CTM_Exra_EbrakSta "Trailer Exterior Ebrake Out OnOffStatus";
CM_ SG_ 1079 CTM_TrlAngl_200ms "CTM_TrailerAngle_200ms";
CM_ SG_ 1079 CTM_RearfogAct "This signal is used for display the rear fog lamp mounted on the trailer.";
CM_ SG_ 1079 CTM_StpLmpOpnSta "Trailer Stop Lamp OpenStatus";
CM_ SG_ 1079 CTM_TrnSigLmpLftOpnSta "Trailer T/SIG Lamp Left OpenStatus";
CM_ SG_ 1079 CTM_TrnSigLmpRtOpnSta "Trailer T/SIG Lamp Right OpenStatus";
CM_ BO_ 1085 "[PE] Periodic and On Event";
CM_ SG_ 1085 DLBCU_ActiveDis "DLBCU_ActiveModeDisplay";
CM_ SG_ 1085 DLBCU_CellOpt "DLBCU_CellOption Status";
CM_ SG_ 1085 DLBCU_BodySpprtSta "Seat Body Support Function USM R Value";
CM_ SG_ 1085 DLBCU_BodySpprtDis "Seat body Support Function Display Request";
CM_ SG_ 1085 DLBCU_MoodTrpyRValueSet "Drive Seat Mood Therapy R Value";
CM_ SG_ 1085 DLBCU_MoodTrpyCareSta "Drive Seat Mood Therapy Care Mode R Value";
CM_ SG_ 1085 DLBCU_SmartCtrl_Set_Rvalue "ÁÖÇà Áß Çã¸® º¸È£ ±â´É USM µ¿ÀÛ ¼³Á¤ °ª (R Value)";
CM_ SG_ 1085 DLBCU_DrvModUSMSta "DLBCU_DriveModeStatus";
CM_ SG_ 1085 DLBCU_MoodTrpyComfSta "Drive Seat Mood Therapy Comfort Mode R Value";
CM_ SG_ 1085 DLBCU_ActiveStrSta "DLBCU_ActiveStrengthStatus";
CM_ SG_ 1085 DLBCU_ActiveTimeSta "DLBCU_ActiveTimeStatus";
CM_ BO_ 2189468929 "[P] Periodic";
CM_ SG_ 2189468929 ECS_Crc4Val "ECS_CyclicRedundancyCheck4Value";
CM_ SG_ 2189468929 ECS_AlvCnt4Val "ECS_AliveCounter4Value";
CM_ SG_ 2189468929 ECSIVSS_FLWhlVrtclAccelSnsrVal "ECSIVSS_FrontLeftWheelVerticalAccelerationSensorValue";
CM_ SG_ 2189468929 ECSIVSS_FRWhlVrtclAccelSnsrVal "ECSIVSS_FrontRightWheelVerticalAccelerationSensorValue";
CM_ SG_ 2189468929 ECSIVSS_FLBodyAccelSnsrVal "ECSIVSS_FrontLeftBodyAccelerationSensorValue";
CM_ BO_ 2189468930 "[P] Periodic";
CM_ SG_ 2189468930 ECSIVSS_FRBodyAccelSnsrVal "ECSIVSS_FrontRightBodyAccelerationSensorValue";
CM_ SG_ 2189468930 ECSIVSS_RrBodyAccelSnsrVal "ECSIVSS_RearBodyAccelerationSensorValue";
CM_ SG_ 2189468930 ECSIVSS_EcuLongAccelSnsrVal "ECSIVSS_ECULongitudinalAccelerationSensorValue";
CM_ SG_ 2189468930 ECSIVSS_EcuLatAccelSnsrVal "ECSIVSS_ECULateralAccelerationSensorValue";
CM_ SG_ 2189468930 ECSIVSS_EcuVertAccelSnsrVal "ECSIVSS_ECUVerticalAccelerationSensorValue";
CM_ SG_ 2189468930 ECSIVSS_RdIndxVal "ECSIVSS_RoadIndexValue";
CM_ BO_ 2189468931 "[P] Periodic";
CM_ SG_ 2189468931 ECSIVSS_EcuRollGyroSnsrVal "ECSIVSS_EcuRollGyroSensorValue";
CM_ SG_ 2189468931 ECSIVSS_EcuPitchGyroSnsrVal "ECSIVSS_EcuPitchGyroSensorValue";
CM_ SG_ 2189468931 ECSIVSS_EcuYawGyroSnsrVal "ECSIVSS_EcuYawGyroSensorValue";
CM_ SG_ 2189468931 ECSEMCU_PrvMode "Mode of Preview ECS";
CM_ SG_ 2189468931 ECSEMCU_PrvECSflag "Flag of Preview ECS to control EMCU";
CM_ BO_ 2164278529 "[P] Periodic";
CM_ SG_ 2164278529 HTCU_Crc4Val "HTCU_CyclicRedundancyCheck4Value";
CM_ SG_ 2164278529 HTCU_AlvCnt4Val "HTCU_AliveCounter4Value";
CM_ SG_ 2164278529 HTCU_TrgtGearSta "HTCU_TargetGearStatus";
CM_ SG_ 2164278529 HTCU_RdySta "HTCU_ReadyStatus";
CM_ SG_ 2164278529 HTCU_GearChgSta "HTCU_GearChangeStatus";
CM_ SG_ 2164278529 HTCU_TqRdctnPcVal "HTCU_TorqueReductionPcValue";
CM_ SG_ 2164278529 HTCU_FltSta "HTCU_FaultStatus";
CM_ SG_ 2164278529 HTCU_GearSlctrDis "HTCU_GearSelectDisplay";
CM_ SG_ 2164278529 HTCU_SlwTqRdctnPcVal "HTCU_SlowTorqueReductionPcValue";
CM_ SG_ 2164278529 HTCU_PddlShftUpDn "Paddle Shift Up(Plus)/Dn(Minus)";
CM_ SG_ 2164278529 HTCU_FanCtrlReq "Fan control request by OPU";
CM_ BO_ 2164278530 "[P] Periodic";
CM_ SG_ 2164278530 HTCU_VehSpdKphVal "HTCU_VehicleSpeedKphValue";
CM_ SG_ 2164278530 HTCU_HvOpuSpdCmdRpmVal "HTCU_HvOpuSpeedCommandRpmValue";
CM_ SG_ 2164278530 HTCU_TrgtShftClsCCanSta "HTCU_TargetShiftClassCCanStatus";
CM_ SG_ 2164278530 HTCU_PrgrmSta "HTCU_ProgramStatus";
CM_ SG_ 2164278530 HTCU_FsCltchLmphmActvSta "HTCU_FsClutchLimphomeActivationStatus";
CM_ SG_ 2164278530 HTCU_FsIdleTrgtRpmVal "HTCU_FsIdleTargetRpmValue";
CM_ SG_ 2164278530 HTCU_FsAddtnlTqLssPcVal "HTCU_FsAdditionalTorqueLossPcValue";
CM_ SG_ 2164278530 HTCU_VehSpdDcmlKphVal "HTCU_VehicleSpeedDecimalKphValue";
CM_ BO_ 2164278531 "[P] Periodic";
CM_ SG_ 2164278531 HTCU_FsEngTqRdctnPcVal "HTCU_FsEngineTorqueReductionPcValue";
CM_ SG_ 2164278531 HTCU_RapidKDReq "HTCU_RapidKDRequest";
CM_ SG_ 2164278531 HTCU_CurrGearSta "HTCU_CurrentGearStatus";
CM_ SG_ 2164278531 HTCU_GearShftUpDisGSI "HTCU_GearShiftUpDisplayGSI";
CM_ SG_ 2164278531 HTCU_GearShftDnDisGSI "HTCU_GearShiftDownDisplayGSI";
CM_ SG_ 2164278531 HTCU_TrgtGearStaGSI "HTCU_TargetGearStatusGSI";
CM_ SG_ 2164278531 HTCU_SolBSta "HTCU_SolenoidBStatus";
CM_ SG_ 2164278531 HTCU_TqRdctnNegativePcVal "HTCU_TorqueReductionNegativePcValue";
CM_ SG_ 2164278531 HTCU_LnPrsBarVal "HTCU_LinePressureBarValue";
CM_ BO_ 1221 "[EC] On Event and On Change";
CM_ SG_ 1221 HU_ChgInCurrModSet "Charge current set signal";
CM_ SG_ 1221 SWRC_Sensitivity_SET "SWRC_OpticalSwtich_Sensitivity_Setting";
CM_ SG_ 1221 HU_EV_WinterMode "<For after OS/DE/SK3 EV/AE PE EV>

EV Battery temp. up setting on/off 
- setting signal : CR_Bms_WinterMode";
CM_ SG_ 1221 HU_TgSoc_ScChg_Set "<For after OS/DE/SK3 EV>
Target SOC user setting value for slow charger(SC/AC).
- For EV only";
CM_ SG_ 1221 HU_TgSoc_QcChg_Set "<For after OS/DE/SK3 EV>
Target SOC user setting value for fast charger(QC/DC).
- For EV only";
CM_ BO_ 1076 "[PE] Periodic and On Event";
CM_ SG_ 1076 IAU_ProfileIDRVal "This signal Indicate the Current detected Profile ID by IAU.";
CM_ SG_ 1076 IAU_DigitalKeyProcessingSta "Digital Key USM settitng Process State";
CM_ SG_ 1076 IAU_DigitalKeyExit "Digital Key USM setting Exit Condition";
CM_ SG_ 1076 IAU_DigitalKeyEnblRVal "Digital Key Function Enable / Disable flag (Fob is required for changing flag)";
CM_ SG_ 1076 IAU_OwnerPhnRegRVal "Vehicle Owner's Phone is Registered for Digital Key function";
CM_ SG_ 1076 IAU_NFCCard1RegRVal "NFC Card 1 is Registered for Digital Key function";
CM_ SG_ 1076 IAU_NFCCard2RegRVal "NFC Card 2 is Registered for Digital Key function";
CM_ SG_ 1076 IAU_DigitalKey2Opt "Digital Key2 Option Signal";
CM_ BO_ 2281833729 "[P] Periodic";
CM_ SG_ 2281833729 ICSC_Crc2Val "ICSC_CyclicRedundancyCheck2Value";
CM_ SG_ 2281833729 ICSC_AlvCnt2Val "ICSC_AliveCounter2Value";
CM_ SG_ 2281833729 DMIC_DrvModSta "DMIC_DriveModeStatus ##2G##ICSC - IVSS11 - DrivingModeState";
CM_ SG_ 2281833729 DMIC_SmtShftModSta "DMIC_SmartShiftModeStatus ##2G##ICSC - IVSS11 - SMART_SHIFT_MODE";
CM_ SG_ 2281833729 DMIC_4wdLocking "4wd Locking on/off signal. Bypass SWRC to VCU.";
CM_ SG_ 2281833729 DMIC_EngModSta "DMIC_EngineModeStatus ##2G##ICSC - IVSS11 - MODE_ENG";
CM_ SG_ 2281833729 DMIC_IndEngModSta "DMIC_IndividualEngineModeStatus ##2G##ICSC - IVSS11 - MODE_PT_IND";
CM_ SG_ 2281833729 DMIC_TmModSta "DMIC_TmModeStatus ##2G##ICSC - IVSS11 - MODE_TM";
CM_ SG_ 2281833729 DMIC_IndTmModSta "DMIC_IndividualTmModeStatus";
CM_ SG_ 2281833729 DMIC_EscModSta "DMIC_EscModeStatus ##2G##ICSC - IVSS11 - MODE_ESC";
CM_ SG_ 2281833729 DMIC_IndEscModSta "DMIC_IndividualEscModeStatus ##2G##ICSC - IVSS11 - MODE_ESC_IND";
CM_ SG_ 2281833729 DMIC_MdpsModSta "DMIC_MdpsModeStatus ##2G##ICSC - IVSS11 - MODE_MDPS";
CM_ SG_ 2281833729 DMIC_IndMdpsModSta "DMIC_IndividualMdpsModeStatus ##2G##ICSC - IVSS11 - MODE_MDPS_IND";
CM_ BO_ 2281833730 "[P] Periodic";
CM_ SG_ 2281833730 DMIC_EcsModSta "DMIC_EcsModeStatus ##2G##ICSC - IVSS11 - MODE_ECS";
CM_ SG_ 2281833730 DMIC_IndAwdModSta "DMIC_IndividualAwdModeStatus ##2G##ICSC - IVSS11 - MODE_4WD_IND";
CM_ SG_ 2281833730 DMIC_RevModSta "DMIC_RevModeStatus ##2G##ICSC - IVSS11 - MODE_REV";
CM_ SG_ 2281833730 DMIC_IndRevModSta "DMIC_IndividualRevModeStatus ##2G##ICSC - IVSS11 - MODE_REV_IND";
CM_ SG_ 2281833730 DMIC_PrflModSta "DMIC_PrflModeStatus ##2G##ICSC - IVSS11 - MODE_PRFL";
CM_ SG_ 2281833730 DMIC_IndPrflModSta "DMIC_IndividualPrflModeStatus ##2G##ICSC - IVSS11 - MODE_PRFL_IND";
CM_ SG_ 2281833730 DMIC_ElsdModSta "DMIC_ElsdModeStatus ##2G##ICSC - IVSS11 - MODE_ELSD";
CM_ SG_ 2281833730 DMIC_IndElsdModSta "DMIC_IndividualElsdModeStatus ##2G##ICSC - IVSS11 - MODE_ELSD_IND";
CM_ SG_ 2281833730 DMIC_IndEcsModSta "DMIC_IndividualEcsModeStatus ##2G##ICSC - IVSS11 - MODE_ECS_IND";
CM_ SG_ 2281833730 DMIC_EsndModSta "DMIC_EsndModeStatus ##2G##ICSC - IVSS11 - MODE_ESND";
CM_ SG_ 2281833730 DMIC_IndEsndModSta "DMIC_IndividualEsndModeStatus ##2G##ICSC - IVSS11 - MODE_ESND_IND";
CM_ SG_ 2281833730 DMIC_RwsModSta "DMIC_RwsModeStatus";
CM_ SG_ 2281833730 DMIC_IndRwsModSta "DMIC_IndividualRwsModeStatus";
CM_ SG_ 2281833730 DMIC_DrvCtrAppSta "VPC control status of Drive/terrain mode";
CM_ SG_ 2281833730 DMIC_EscOffStaAppTyp "DMIC_EscOffStatusAppliedType";
CM_ SG_ 2281833730 DMIC_AwdModSta "DMIC_AwdModeStatus ##2G##ICSC - IVSS11 - MODE_4WD";
CM_ BO_ 2281833731 "[P] Periodic";
CM_ SG_ 2281833731 DMIC_VcuModSta "VCU: DMIC_VcuModeStatus like a #2G# IVSS11-MODE_ENG";
CM_ SG_ 2281833731 DMIC_DrvModTyp "DMIC_DriveModeType ##2G##ICSC - IVSS11 - DRIVE_MODE_TYPE";
CM_ SG_ 2281833731 DMIC_EngFltSta "DMIC_EngineFaultStatus ##2G##ICSC - IVSS11 - MODE_ENG_FltStat";
CM_ SG_ 2281833731 DMIC_TmFltSta "DMIC_TransmissionFaultStatus ##2G##ICSC - IVSS11 - MODE_TM_FltStat";
CM_ SG_ 2281833731 DMIC_EscFltSta "DMIC_EscFaultStatus ##2G##ICSC - IVSS11 - MODE_ESC_FltStat";
CM_ SG_ 2281833731 DMIC_MdpsFltSta "DMIC_MdpsFaultStatus ##2G##ICSC - IVSS11 - MODE_MDPS_FltStat";
CM_ SG_ 2281833731 DMIC_EcsFltSta "DMIC_EcsFltSta ##2G##ICSC - IVSS11 - MODE_ECS_FltStat";
CM_ SG_ 2281833731 DMIC_AwdFltSta "DMIC_AwdFaultStatus ##2G##ICSC - IVSS11 - MODE_4WD_FltStat";
CM_ SG_ 2281833731 DMIC_RevFltSta "DMIC_RevFaultStatus ##2G##ICSC - IVSS11 - MODE_REV_FltStat";
CM_ SG_ 2281833731 DMIC_PrflFltSta "DMIC_PrefillFaultStatus ##2G##ICSC - IVSS11 - MODE_PRFL_FltStat";
CM_ SG_ 2281833731 DMIC_ElsdFltSta "DMIC_ElsdFaultStatus ##2G##ICSC - IVSS11 - MODE_ELSD_FltStat";
CM_ SG_ 2281833731 DMIC_EsndFltSta "DMIC_EsndFaultStatus ##2G##ICSC - IVSS11 - MODE_ENSD_FltStat";
CM_ SG_ 2281833731 DMIC_RwsFltSta "DMIC_RwsFaultStatus";
CM_ SG_ 2281833731 DMIC_IndVcuModSta "VCU: DMIC_IndividualVcuModeStatus like a #2G# IVSS11-MODE_ENG_IND";
CM_ SG_ 2281833731 DMIC_VcuFltSta "VCU: DMIC_VcuFaultStatus like a ##2G##ICSC - IVSS11 - MODE_ENG_FltStat";
CM_ SG_ 2281833731 DMIC_TerrainModSwSta "DMIC_TerrainModeSwitchStatus";
CM_ SG_ 2281833731 DMIC_TerrainMainSwSta "DMIC_TerrainMainSwitchStatus";
CM_ SG_ 2281833731 DMIC_DrvngModSwSta "DMIC_DrivingModeSwitchStatus";
CM_ SG_ 2281833731 DMIC_DrvMod2Typ "DMIC_DriveModeType2 ##2G##ICSC - IVSS11 - DRIVE_MODE_TYPE";
CM_ SG_ 2281833731 DMIC_DrvModFltSta "DMIC_DriveModeFaultStatus ##2G##ICSC - IVSS11 - MODE_DRIVING_FltStat";
CM_ BO_ 1059 "[PE] Periodic and On Event";
CM_ SG_ 1059 PSU_DiagSta "PSU_DiagnosticStatus";
CM_ SG_ 1059 PSU_EsyAcsGetOnSta "PSU_EasyAccessGetOnStatus";
CM_ SG_ 1059 PSU_EsyAcsGetOffSta "PSU_EasyAccessGetOffStatus";
CM_ SG_ 1059 PSU_EsyAcsStpSta "PSU_EasyAccessStopStatus";
CM_ SG_ 1059 PSU_RVal "PSU_RValue";
CM_ BO_ 1086 "[PE] Periodic and On Event";
CM_ SG_ 1086 RL_CURTAIN_POSITION "Rear Left Curtain Status Position Output";
CM_ SG_ 1086 RDC_SWVerMinor1 "Second Word(ASCII) in RDC S/W Ver";
CM_ SG_ 1086 RDC_SWVerMinor2 "Third Word(ASCII) in RDC S/W Ver";
CM_ SG_ 1086 RR_CURTAIN_POSITION "Rear Right Curtain Status Position Output";
CM_ SG_ 1086 RDC_RLDNInitFlag "Rear Left Door Curtain Down Initialized Finish Flag";
CM_ SG_ 1086 RDC_RRDNInitFlag "Rear Right Door Curtain Down Initialized Finish Flag";
CM_ SG_ 1086 RDC_RLOpState "Rear Left Door Curtain Operating State Feedback";
CM_ SG_ 1086 RDC_RROpState "Rear Right Door Curtain Operating State Feedback";
CM_ SG_ 1086 RDC_OptTyp "OPTION FLAG for RDC";
CM_ SG_ 1086 RDC_SWVerMajor1 "First Word(ASCII) in RDC S/W Ver";
CM_ BO_ 1068 "[PE] Periodic and On Event";
CM_ SG_ 1068 RLPSU_ReclMtrPos "RLPSU Recline Motor Position";
CM_ SG_ 1068 RLPSU_RLSlidPos "2nd Left Seat Slide Position Information for button activatation / unactivation";
CM_ SG_ 1068 RLPSU_RLRclPos "2nd Left Seat Back Reclining Position Information for button activatation / unactivation";
CM_ SG_ 1068 RLPSU_RLTiltPos "2nd Left Seat Cushion Tilt Position Information for button activatation / unactivation";
CM_ SG_ 1068 RLPSU_RLLegExtPos "2nd Left Seat Legsupport Extension Position Information for button activatation / unactivation";
CM_ SG_ 1068 RLPSU_RLLegSupPos "2nd Left Seat Legrest Support Position Information for button activatation / unactivation";
CM_ SG_ 1068 RLPSU_RLHrestSlidPos "2nd Left Seat Head Rest Slide Position Information for button activatation / unactivation";
CM_ SG_ 1068 RLPSU_RLHrestHeightPos "2nd Left Seat HeadRest Height Position Information for button activatation / unactivation";
CM_ SG_ 1068 RLPSU_Opt "PWR_HVU Option";
CM_ SG_ 1068 RLPSU_Opt_Captain "PWR_HVU Option_Captain";
CM_ SG_ 1068 RLHVU_Opt_Captain "MNL_HVU Option_Captain";
CM_ SG_ 1068 RLPSU_PwrSeatOpt "Option Info for 2nd Left Recline Seat";
CM_ SG_ 1068 RLPSU_PwrSeatPos "2nd Left Seat Back Position for button activatation / unactivation";
CM_ BO_ 1080 "[PE] Periodic and On Event";
CM_ SG_ 1080 RL_SHVU_SeatOptSta "Rear LH Seat Heater/Vent option info";
CM_ SG_ 1080 RL_SHVU_SeatHtOperSta "Rear LH Seat Heater/Vent current operation state";
CM_ SG_ 1080 RL_SHVU_HtSwHiIndSta_RHD "Rear Left_Seat Heater Switch High Indicator Status";
CM_ SG_ 1080 RL_SHVU_HtSwMidIndSta_RHD "Rear Left_Seat Heater Switch Mid Indicator Status";
CM_ SG_ 1080 RL_SHVU_HtSwLowIndSta_RHD "Rear Left_Seat Heater Switch Low Indicator Status";
CM_ SG_ 1080 RL_SHVU_VntSwHiIndSta_RHD "Rear Left Seat Vent Switch High Indicator Status";
CM_ SG_ 1080 RL_SHVU_VntSwMidIndSta_RHD "Rear Left Seat Vent Switch Mid Indicator Status";
CM_ SG_ 1080 RL_SHVU_VntSwLowIndSta_RHD "Rear Left Seat Vent Switch Low Indicator Status";
CM_ SG_ 1080 RL_SHVU_HtBlcUsmSta_RHD "RL Seat Heater Balance Status(RHD)";
CM_ BO_ 1070 "[PE] Periodic and On Event";
CM_ SG_ 1070 RL_SHVU_HtSwHiIndSta "Rear Left_Seat Heater Switch High Indicator Status";
CM_ SG_ 1070 RL_SHVU_HtSwMidIndSta "Rear Left_Seat Heater Switch Mid Indicator Status";
CM_ SG_ 1070 RL_SHVU_HtSwLowIndSta "Rear Left_Seat Heater Switch Low Indicator Status";
CM_ SG_ 1070 RL_SHVU_VntSwHiIndSta "Rear Left Seat Vent Switch High Indicator Status";
CM_ SG_ 1070 RL_SHVU_VntSwMidIndSta "Rear Left Seat Vent Switch Mid Indicator Status";
CM_ SG_ 1070 RL_SHVU_VntSwLowIndSta "Rear Left Seat Vent Switch Low Indicator Status";
CM_ SG_ 1070 RL_SHVU_HtBlcUsmSta "RL Seat Heater Balance Status";
CM_ BO_ 1069 "[PE] Periodic and On Event";
CM_ SG_ 1069 RRPSU_ReclMtrPos "RRPSU Recline Motor Position";
CM_ SG_ 1069 RRPSU_PwrSeatOpt "Option Info for 2nd Right Recline Seat";
CM_ SG_ 1069 RRPSU_PwrSeatPos "2nd Right Seat Back Position for button activatation / unactivation";
CM_ SG_ 1069 RRPSU_RRSlidPos "2nd Right Seat Slide Position Information For Button Activation / Deactivation";
CM_ SG_ 1069 RRPSU_RRRclPos "2nd Right Seat Recline Position Information For Button Activation / Deactivation";
CM_ SG_ 1069 RRPSU_RRTiltPos "2nd Right Seat Cushion Tilt Position Information For Button Activation / Deactivation";
CM_ SG_ 1069 RRPSU_RRLegExtPos "2nd Right Seat Legextension (Front / Rear) Position Information For Button Activation / Deactivation";
CM_ SG_ 1069 RRPSU_RRLegSupPos "2nd Right Seat Leg Extension (Upper/Lower) Position Information For Button Activation / Deactivation";
CM_ SG_ 1069 RRPSU_RRStEsyAcsUSMSta "Rear RH Seat EasyAccess USM";
CM_ SG_ 1069 RRPSU_RRHrestSlidPos "2nd Right Seat HeadRest Slide Position Information For Button Activation / Deactivation";
CM_ SG_ 1069 RRPSU_RRHrestHeightPos "2nd Right Seat Headrest Height Position Information For Button Activation / Deactivation";
CM_ SG_ 1069 RRPSU_Opt_Captain "PWR_HVU Option_Captain";
CM_ SG_ 1069 RRHVU_Opt_Captain "MNL_HVU Option_Captain";
CM_ SG_ 1069 RRPSU_RLStEsyAcsUSMSta "Rear LH Seat EasyAccess USM Setting";
CM_ SG_ 1069 RRPSU_Opt "PWR_HVU Option";
CM_ BO_ 1071 "[PE] Periodic and On Event";
CM_ SG_ 1071 RR_SHVU_HtSwHiIndSta "Rear Right_Seat Heater Switch High Indicator Status";
CM_ SG_ 1071 RR_SHVU_HtSwMidIndSta "Rear Left_Seat Heater Switch Mid Indicator Status";
CM_ SG_ 1071 RR_SHVU_HtSwLowIndSta "Rear Right_Seat Heater Switch Low Indicator Status";
CM_ SG_ 1071 RR_SHVU_VntSwHiIndSta "Rear Right Seat Vent Switch High Indicator Status";
CM_ SG_ 1071 RR_SHVU_VntSwMidIndSta "Rear Right Seat Vent Switch Mid Indicator Status";
CM_ SG_ 1071 RR_SHVU_VntSwLowIndSta "Rear Right Seat Vent Switch Low Indicator Status";
CM_ SG_ 1071 RR_SHVU_HtBlcUsmSta "RR Seat Heater Balance Status";
CM_ BO_ 1073 "[PE] Periodic and On Event";
CM_ SG_ 1073 USM_ValCmdSta "USM_ValueCommandStatus";
CM_ SG_ 1073 RWPC_SWVerMinor1 "Second Word(ASCII) in RWPC S/W Ver";
CM_ SG_ 1073 WPC_PhnLftWrngRWPCSta "WPC_PhoneLeftWaringRWPCStatus";
CM_ SG_ 1073 RWPC_SWVerMinor2 "Third Word(ASCII) in RWPC S/W Ver";
CM_ SG_ 1073 USM_ValCmdStaforATS "USM_ValueCommandStatus";
CM_ SG_ 1073 RWPC_SWVerMajor1 "First Word(ASCII) in RWPC S/W Ver";
CM_ BO_ 1067 "[PE] Periodic and On Event";
CM_ SG_ 1067 SCM_SWVerMajor1 "First Word(ASCII) in SCM S/W Ver";
CM_ SG_ 1067 SCM_SWVerMinor1 "Second Word(ASCII) in SCM S/W Ver";
CM_ SG_ 1067 SCM_SWVerMinor2 "Third Word(ASCII) in SCM S/W Ver";
BA_DEF_ BO_ "DiagState" ENUM "No","Yes" ;
BA_DEF_ BO_ "DiagResponse" ENUM "No","Yes" ;
BA_DEF_ BO_ "DiagRequest" ENUM "No","Yes" ;
BA_DEF_ BO_ "TpMessage" ENUM "No","Yes" ;
BA_DEF_ BO_ "UsrMsgIDSforwardDeviation" INT 0 100 ;
BA_DEF_ BO_ "UsrMsgIDSbackwardDeviation" INT 50 1000 ;
BA_DEF_ BO_ "GenMsgCycleTime" INT 0 2000 ;
BA_DEF_ BO_ "GenMsgStartDelayTime" INT 0 2000 ;
BA_DEF_ BO_ "GenMsgSendType" ENUM "Cyclic","NoMsgSendType" ;
BA_DEF_ BO_ "GenMsgCycleTimeFast" INT 0 500 ;
BA_DEF_ BO_ "GenMsgDelayTime" INT 0 20 ;
BA_DEF_ BO_ "GenMsgILSupport" ENUM "No","Yes" ;
BA_DEF_ BO_ "GenMsgNrOfRepetition" INT 0 3 ;
BA_DEF_ BO_ "NmMessage" ENUM "No","Yes" ;
BA_DEF_ BO_ "NWM-Botschaft" ENUM "No","Yes" ;
BA_DEF_ BO_ "TpTxIndex" INT 0 65535 ;
BA_DEF_ BO_ "VFrameFormat" ENUM "StandardCAN","ExtendedCAN","reserved","reserved","reserved","reserved","reserved","reserved","reserved","reserved","reserved","reserved","reserved","reserved","StandardCAN_FD","ExtendedCAN_FD" ;
BA_DEF_ SG_ "UserSigValidity" ENUM "B+","ACC","IG","IG1","IG2","IG3","IG1 or IG2","IG1 or IG3","Undef" ;
BA_DEF_ SG_ "TimeoutValue" STRING ;
BA_DEF_ SG_ "UsrSigPurpose" ENUM "Undef","FN","DIAG","DIAG(Req)","DIAG(Res)","DIAG(Phy)","DEV","CCP(Req)","CCP(Res)","NM","TP" ;
BA_DEF_ SG_ "GenSigStartValue" INT 0 1215752192 ;
BA_DEF_ SG_ "NetworkRequest" ENUM "Yes","No" ;
BA_DEF_ SG_ "NetworkRequestHoldingTime" INT 0 65535 ;
BA_DEF_ SG_ "Description" STRING ;
BA_DEF_ SG_ "Version" STRING ;
BA_DEF_ SG_ "GenSigEnvVarType" ENUM "Int","Float","Undef" ;
BA_DEF_ SG_ "GenSigSendType" ENUM "Cyclic","OnWrite","OnWriteWithRepetition","OnChange","OnChangeWithRepetition","IfActive","IfActiveWithRepetition","NoSigSendType","OnChangeAndIfActive","OnChangeAndIfActiveWithRepetition" ;
BA_DEF_ SG_ "GwSigLatencyTime" INT 0 65536 ;
BA_DEF_ SG_ "GwSigMissingSourceType" ENUM "Undef","OldValue","DefaultValue","InitialValue" ;
BA_DEF_ SG_ "NWM-WakeupAllowed" ENUM "<n.a.>" ;
BA_DEF_ SG_ "RoutingFactor" INT 1 1215752192 ;
BA_DEF_REL_ BU_SG_REL_ "GenSigTimeoutTime" INT 0 7000 ;
BA_DEF_DEF_ "DiagState" "No" ;
BA_DEF_DEF_ "DiagResponse" "No" ;
BA_DEF_DEF_ "DiagRequest" "No" ;
BA_DEF_DEF_ "TpMessage" "No" ;
BA_DEF_DEF_ "UsrMsgIDSforwardDeviation" 10 ;
BA_DEF_DEF_ "UsrMsgIDSbackwardDeviation" 100 ;
BA_DEF_DEF_ "GenMsgCycleTime" 200 ;
BA_DEF_DEF_ "GenMsgStartDelayTime" 0 ;
BA_DEF_DEF_ "GenMsgSendType" "NoMsgSendType" ;
BA_DEF_DEF_ "GenMsgCycleTimeFast" 40 ;
BA_DEF_DEF_ "GenMsgDelayTime" 20 ;
BA_DEF_DEF_ "GenMsgILSupport" "Yes" ;
BA_DEF_DEF_ "GenMsgNrOfRepetition" 3 ;
BA_DEF_DEF_ "NmMessage" "No" ;
BA_DEF_DEF_ "NWM-Botschaft" "No" ;
BA_DEF_DEF_ "TpTxIndex" 0 ;
BA_DEF_DEF_ "VFrameFormat" "StandardCAN" ;
BA_DEF_DEF_ "UserSigValidity" "IG" ;
BA_DEF_DEF_ "TimeoutValue" "" ;
BA_DEF_DEF_ "UsrSigPurpose" "FN" ;
BA_DEF_DEF_ "GenSigStartValue" 0 ;
BA_DEF_DEF_ "NetworkRequest" "No" ;
BA_DEF_DEF_ "NetworkRequestHoldingTime" 0 ;
BA_DEF_DEF_ "Description" "" ;
BA_DEF_DEF_ "Version" "" ;
BA_DEF_DEF_ "GenSigEnvVarType" "Undef" ;
BA_DEF_DEF_ "GenSigSendType" "NoSigSendType" ;
BA_DEF_DEF_ "GwSigLatencyTime" 40 ;
BA_DEF_DEF_ "GwSigMissingSourceType" "Undef" ;
BA_DEF_DEF_ "NWM-WakeupAllowed" "<n.a.>" ;
BA_DEF_DEF_ "RoutingFactor" 1 ;
BA_DEF_DEF_REL_ "GenSigTimeoutTime" 500 ;
BA_ "GenMsgSendType" BO_ 1064 0;
BA_ "Description" SG_ 1064 APSU_DiagSta "(Old)C_APSU_DiagState";
BA_ "GenSigSendType" SG_ 1064 APSU_DiagSta 4;
BA_ "UserSigValidity" SG_ 1064 APSU_DiagSta 0;
BA_ "NetworkRequest" SG_ 1064 APSU_DiagSta 0;
BA_ "NetworkRequestHoldingTime" SG_ 1064 APSU_DiagSta 5000;
BA_ "Version" SG_ 1064 APSU_DiagSta "21.07.06";
BA_ "Description" SG_ 1064 APSU_AstAllLmtSta "°¡»ó ¸®¹ÌÆ® ¼³Á¤ »óÅÂ Á¤º¸

Virtual Limit Set State (Not Set / All Set)";
BA_ "GenSigSendType" SG_ 1064 APSU_AstAllLmtSta 4;
BA_ "UserSigValidity" SG_ 1064 APSU_AstAllLmtSta 0;
BA_ "Version" SG_ 1064 APSU_AstAllLmtSta "20.12.04";
BA_ "Description" SG_ 1064 APSU_EsyAcsGetOnSta "Easy Access Get On Information";
BA_ "GenSigSendType" SG_ 1064 APSU_EsyAcsGetOnSta 4;
BA_ "UserSigValidity" SG_ 1064 APSU_EsyAcsGetOnSta 0;
BA_REL_ "GenSigTimeoutTime" BU_SG_REL_ ALBCU SG_ 1064 APSU_EsyAcsGetOnSta 1500;
BA_REL_ "GenSigTimeoutTime" BU_SG_REL_ GW_RLPSU SG_ 1064 APSU_EsyAcsGetOnSta 1500;
BA_REL_ "GenSigTimeoutTime" BU_SG_REL_ GW_RRPSU SG_ 1064 APSU_EsyAcsGetOnSta 1500;
BA_ "NetworkRequest" SG_ 1064 APSU_EsyAcsGetOnSta 0;
BA_ "NetworkRequestHoldingTime" SG_ 1064 APSU_EsyAcsGetOnSta 5000;
BA_ "Version" SG_ 1064 APSU_EsyAcsGetOnSta "21.07.06";
BA_ "Description" SG_ 1064 APSU_EsyAcsGetOffSta "Easy Access Get Off Information";
BA_ "GenSigSendType" SG_ 1064 APSU_EsyAcsGetOffSta 4;
BA_ "UserSigValidity" SG_ 1064 APSU_EsyAcsGetOffSta 0;
BA_REL_ "GenSigTimeoutTime" BU_SG_REL_ ALBCU SG_ 1064 APSU_EsyAcsGetOffSta 1500;
BA_REL_ "GenSigTimeoutTime" BU_SG_REL_ GW_RLPSU SG_ 1064 APSU_EsyAcsGetOffSta 1500;
BA_REL_ "GenSigTimeoutTime" BU_SG_REL_ GW_RRPSU SG_ 1064 APSU_EsyAcsGetOffSta 1500;
BA_ "NetworkRequest" SG_ 1064 APSU_EsyAcsGetOffSta 0;
BA_ "NetworkRequestHoldingTime" SG_ 1064 APSU_EsyAcsGetOffSta 5000;
BA_ "Version" SG_ 1064 APSU_EsyAcsGetOffSta "21.07.06";
BA_ "Description" SG_ 1064 APSU_EsyAcsStpSta "Easy Access Stop Information";
BA_ "GenSigSendType" SG_ 1064 APSU_EsyAcsStpSta 4;
BA_ "UserSigValidity" SG_ 1064 APSU_EsyAcsStpSta 0;
BA_REL_ "GenSigTimeoutTime" BU_SG_REL_ ALBCU SG_ 1064 APSU_EsyAcsStpSta 1500;
BA_REL_ "GenSigTimeoutTime" BU_SG_REL_ GW_RLPSU SG_ 1064 APSU_EsyAcsStpSta 1500;
BA_REL_ "GenSigTimeoutTime" BU_SG_REL_ GW_RRPSU SG_ 1064 APSU_EsyAcsStpSta 1500;
BA_ "NetworkRequest" SG_ 1064 APSU_EsyAcsStpSta 0;
BA_ "NetworkRequestHoldingTime" SG_ 1064 APSU_EsyAcsStpSta 5000;
BA_ "Version" SG_ 1064 APSU_EsyAcsStpSta "21.07.06";
BA_ "GenSigSendType" SG_ 1064 APSU_RVal 4;
BA_ "UserSigValidity" SG_ 1064 APSU_RVal 0;
BA_ "NetworkRequest" SG_ 1064 APSU_RVal 0;
BA_ "NetworkRequestHoldingTime" SG_ 1064 APSU_RVal 5000;
BA_ "Version" SG_ 1064 APSU_RVal "21.07.06";
BA_ "GenMsgSendType" BO_ 1058 0;
BA_ "Description" SG_ 1058 BCM_Crc10Val "The data area for CRC calculation is based on the data length (DLC) of the message DB.

The CRC shall be calculated over the entire data block (excluding the CRC bytes) including the user data, alive counter and Data ID 

 

- CRC Polynomial (0x1D) , Initial Value : 0x00, XOR value : 0xFF, Data ID Mode : Both, Data ID : Message ID + 0xF800 

- The initial value is for CRC calculation and the message should be sent with the calculated result value. 

The mathematical expression to 8 bit CRC polynomial is given here. G(x) = x8 + x4 + x3 + x2 + 1";
BA_ "GenSigSendType" SG_ 1058 BCM_Crc10Val 4;
BA_ "UserSigValidity" SG_ 1058 BCM_Crc10Val 0;
BA_ "Version" SG_ 1058 BCM_Crc10Val "21.09.03";
BA_ "Description" SG_ 1058 BCM_AlvCnt10Val "For the first transmission request for a data element the counter shall be initialized with 0 and shall be incremented by 1

for every subsequent send request. When the counter reaches the maximum value(0xE), then it shall restart with 0 for the next send request";
BA_ "GenSigSendType" SG_ 1058 BCM_AlvCnt10Val 4;
BA_ "UserSigValidity" SG_ 1058 BCM_AlvCnt10Val 0;
BA_ "Version" SG_ 1058 BCM_AlvCnt10Val "21.09.03";
BA_ "GenSigSendType" SG_ 1058 Wiper_PrkngPosSta 4;
BA_ "UserSigValidity" SG_ 1058 Wiper_PrkngPosSta 0;
BA_REL_ "GenSigTimeoutTime" BU_SG_REL_ BLTN_CAM SG_ 1058 Wiper_PrkngPosSta 1500;
BA_ "NetworkRequest" SG_ 1058 Wiper_PrkngPosSta 0;
BA_ "NetworkRequestHoldingTime" SG_ 1058 Wiper_PrkngPosSta 5000;
BA_ "Version" SG_ 1058 Wiper_PrkngPosSta "17.12.00";
BA_ "Description" SG_ 1058 Wiper_RainSnsrOptionTyp "Rain Sensor Option Information";
BA_ "GenSigSendType" SG_ 1058 Wiper_RainSnsrOptionTyp 4;
BA_ "UserSigValidity" SG_ 1058 Wiper_RainSnsrOptionTyp 0;
BA_ "NetworkRequest" SG_ 1058 Wiper_RainSnsrOptionTyp 0;
BA_ "NetworkRequestHoldingTime" SG_ 1058 Wiper_RainSnsrOptionTyp 5000;
BA_ "Version" SG_ 1058 Wiper_RainSnsrOptionTyp "17.12.00";
BA_ "Description" SG_ 1058 Wiper_RainSnsrSta "This signal represents the status of Rain Sensor signal state. 

- '20. 8/3 : Changed value table (0x5, 0x6 : Fault2/3 ¡æ Reserved)";
BA_ "GenSigSendType" SG_ 1058 Wiper_RainSnsrSta 4;
BA_ "UserSigValidity" SG_ 1058 Wiper_RainSnsrSta 0;
BA_REL_ "GenSigTimeoutTime" BU_SG_REL_ BLTN_CAM SG_ 1058 Wiper_RainSnsrSta 1500;
BA_ "NetworkRequest" SG_ 1058 Wiper_RainSnsrSta 0;
BA_ "NetworkRequestHoldingTime" SG_ 1058 Wiper_RainSnsrSta 5000;
BA_ "Version" SG_ 1058 Wiper_RainSnsrSta "20.08.00";
BA_ "Description" SG_ 1058 Wiper_HtWshNzzlCmd "Heated Washer Nozzle Command";
BA_ "GenSigSendType" SG_ 1058 Wiper_HtWshNzzlCmd 4;
BA_ "UserSigValidity" SG_ 1058 Wiper_HtWshNzzlCmd 0;
BA_ "NetworkRequest" SG_ 1058 Wiper_HtWshNzzlCmd 0;
BA_ "NetworkRequestHoldingTime" SG_ 1058 Wiper_HtWshNzzlCmd 5000;
BA_ "Version" SG_ 1058 Wiper_HtWshNzzlCmd "20.08.07";
BA_ "Description" SG_ 1058 BCM_SolSnsrRt "This signal indicates solar sensor output W/m^2 - RH";
BA_ "GenSigSendType" SG_ 1058 BCM_SolSnsrRt 4;
BA_ "UserSigValidity" SG_ 1058 BCM_SolSnsrRt 0;
BA_ "NetworkRequest" SG_ 1058 BCM_SolSnsrRt 0;
BA_ "NetworkRequestHoldingTime" SG_ 1058 BCM_SolSnsrRt 5000;
BA_ "Version" SG_ 1058 BCM_SolSnsrRt "21.11.04";
BA_ "Description" SG_ 1058 BCM_SolSnsrLft "This signal indicates solar sensor output W/m^2 - LH";
BA_ "GenSigSendType" SG_ 1058 BCM_SolSnsrLft 4;
BA_ "UserSigValidity" SG_ 1058 BCM_SolSnsrLft 0;
BA_ "NetworkRequest" SG_ 1058 BCM_SolSnsrLft 0;
BA_ "NetworkRequestHoldingTime" SG_ 1058 BCM_SolSnsrLft 5000;
BA_ "Version" SG_ 1058 BCM_SolSnsrLft "21.11.04";
BA_ "Description" SG_ 1058 BCM_GearPosPSta "This signal is valid only when connected to Key Interlock SW or P Position SW as a circuit";
BA_ "GenSigSendType" SG_ 1058 BCM_GearPosPSta 4;
BA_ "UserSigValidity" SG_ 1058 BCM_GearPosPSta 0;
BA_REL_ "GenSigTimeoutTime" BU_SG_REL_ ATS SG_ 1058 BCM_GearPosPSta 1500;
BA_REL_ "GenSigTimeoutTime" BU_SG_REL_ GW_APSU SG_ 1058 BCM_GearPosPSta 1500;
BA_REL_ "GenSigTimeoutTime" BU_SG_REL_ GW_DPSU SG_ 1058 BCM_GearPosPSta 1500;
BA_REL_ "GenSigTimeoutTime" BU_SG_REL_ GW_RLPSU SG_ 1058 BCM_GearPosPSta 1500;
BA_REL_ "GenSigTimeoutTime" BU_SG_REL_ GW_RRPSU SG_ 1058 BCM_GearPosPSta 1500;
BA_REL_ "GenSigTimeoutTime" BU_SG_REL_ PFSU SG_ 1058 BCM_GearPosPSta 1500;
BA_REL_ "GenSigTimeoutTime" BU_SG_REL_ RLHV SG_ 1058 BCM_GearPosPSta 1500;
BA_REL_ "GenSigTimeoutTime" BU_SG_REL_ RRHV SG_ 1058 BCM_GearPosPSta 1500;
BA_REL_ "GenSigTimeoutTime" BU_SG_REL_ SCM SG_ 1058 BCM_GearPosPSta 1500;
BA_ "NetworkRequest" SG_ 1058 BCM_GearPosPSta 0;
BA_ "NetworkRequestHoldingTime" SG_ 1058 BCM_GearPosPSta 5000;
BA_ "Version" SG_ 1058 BCM_GearPosPSta "21.09.05";
BA_ "Description" SG_ 1058 BCM_SunRoofOpnSta "-Sunroof open/close state";
BA_ "GenSigSendType" SG_ 1058 BCM_SunRoofOpnSta 4;
BA_ "UserSigValidity" SG_ 1058 BCM_SunRoofOpnSta 0;
BA_ "NetworkRequest" SG_ 1058 BCM_SunRoofOpnSta 0;
BA_ "NetworkRequestHoldingTime" SG_ 1058 BCM_SunRoofOpnSta 5000;
BA_ "Version" SG_ 1058 BCM_SunRoofOpnSta "17.12.00";
BA_ "Description" SG_ 1058 SunRoof_RrBlindErrSta "Rear Sunroof Blind error Status (LIN to CAN signal)

-LIN Signal Name : SunBlind_Rear_Error";
BA_ "GenSigSendType" SG_ 1058 SunRoof_RrBlindErrSta 4;
BA_ "UserSigValidity" SG_ 1058 SunRoof_RrBlindErrSta 0;
BA_ "Version" SG_ 1058 SunRoof_RrBlindErrSta "20.07.00";
BA_ "Description" SG_ 1058 Wiper_AutoWashModeSta "Auto Wash Mode Wiper State";
BA_ "GenSigSendType" SG_ 1058 Wiper_AutoWashModeSta 4;
BA_ "UserSigValidity" SG_ 1058 Wiper_AutoWashModeSta 0;
BA_ "NetworkRequest" SG_ 1058 Wiper_AutoWashModeSta 0;
BA_ "NetworkRequestHoldingTime" SG_ 1058 Wiper_AutoWashModeSta 5000;
BA_ "Version" SG_ 1058 Wiper_AutoWashModeSta "21.12.00";
BA_ "Description" SG_ 1058 Wiper_RainSnsrPartNum "Rain Sensor PartNumber (LIN to CAN Signal)

- LIN Signal Name : INFO_PARTNUMBER

¢ºHELLA

 0x00(0000):NI000 / 0x01(0001):EV000 / 0x02(0010):XA000 / 0x03(0011)~0x0E(1110):Reserved / 0x0F(1111):N9000

¢ºBCS(ÏÁ TRW)

 0x00(0000):T6000 / 0x01(0001):DV000 / 0x02(0010):CU000 / 0x03(0011):CV000 / 0x04(0100):KL000 / 0x05(0101):DO000 / 0x06(0110):CU500 / 0x07(0111)~0x0E(1110):Reserved / 0x0F(1111):L1000";
BA_ "GenSigSendType" SG_ 1058 Wiper_RainSnsrPartNum 4;
BA_ "UserSigValidity" SG_ 1058 Wiper_RainSnsrPartNum 0;
BA_ "NetworkRequest" SG_ 1058 Wiper_RainSnsrPartNum 0;
BA_ "NetworkRequestHoldingTime" SG_ 1058 Wiper_RainSnsrPartNum 5000;
BA_ "Version" SG_ 1058 Wiper_RainSnsrPartNum "24.01.00";
BA_ "GenMsgSendType" BO_ 2357404929 0;
BA_ "GenMsgCycleTimeFast" BO_ 2357404929 0;
BA_ "GenMsgNrOfRepetition" BO_ 2357404929 0;
BA_ "VFrameFormat" BO_ 2357404929 1;
BA_ "Description" SG_ 2357404929 BMS_Crc6Val "The data area for CRC calculation is based on the data length (DLC) of the message DB.

The CRC shall be calculated over the entire data block (excluding the CRC bytes) including the user data, alive counter and Data ID



- CRC Polynomial (0x1021) , Initial Value : 0xFFFF, XOR value : 0x0000, Data ID : Message ID + 0xF800 

- The initial value is for CRC calculation and the message should be sent with the calculated result value. 

- The mathematical expression to 16 bit CRC polynomial is given here. G(x) = x16 + x12 + x5 + 1



<For CRC calculation of CAN-FD Msg for HS CAN domain ECUs>



- HS-CAN Messages that routed from CAN-FD domain are using 29 bit Extended CAN ID and splitted into 8 Byte Messages.

(from 1 to 4 Msgs, depending on source CAN-FD Msg¡¯s DLC)

- For splitted CAN-FD Msgs¡¯ CRC calculation, HS CAN ECUs should use source CAN-FD Msg¡¯s original STD ID. 

- The original STD ID can be read from Ext ID¡¯s 4~6th Byte.

Eg. STD 0x6AA : EXT SPLT 0x1A8[6AA]01 / 0x1A8[6AA]02 / 0x1A8[6AA]03 / 0x1A8[6AA]04 

(2~4th splitited Msgs can be omitted depending on source CAN-FD Msg¡¯s DLC)

- Aslo, HS-CAN ECUs should use merged data block (from whole splitted Msg) for CRC calculation.";
BA_ "GenSigStartValue" SG_ 2357404929 BMS_Crc6Val 65535;
BA_ "UserSigValidity" SG_ 2357404929 BMS_Crc6Val 3;
BA_ "RoutingFactor" SG_ 2357404929 BMS_Crc6Val 2;
BA_ "Version" SG_ 2357404929 BMS_Crc6Val "21.09.03";
BA_ "Description" SG_ 2357404929 BMS_AlvCnt6Val "For the first transmission request for a data element the counter shall be initialized with 0 and shall be incremented by 1 for every subsequent send request. 

When the counter reaches the maximum value(0xFF), then it shall restart with 0 for the next send request";
BA_ "UserSigValidity" SG_ 2357404929 BMS_AlvCnt6Val 5;
BA_ "RoutingFactor" SG_ 2357404929 BMS_AlvCnt6Val 2;
BA_ "Version" SG_ 2357404929 BMS_AlvCnt6Val "21.09.03";
BA_ "Description" SG_ 2357404929 CHRG_StndChrgConnSta_120V "Standard Charging(120V) Connector Status  (CF_Bms_StdCha_120V)";
BA_ "UserSigValidity" SG_ 2357404929 CHRG_StndChrgConnSta_120V 7;
BA_ "RoutingFactor" SG_ 2357404929 CHRG_StndChrgConnSta_120V 2;
BA_ "Version" SG_ 2357404929 CHRG_StndChrgConnSta_120V "18.08.07";
BA_ "Description" SG_ 2357404929 CHRG_StndChrgSta "BMS sets this Flag when Battery is standard mode charging (CF_Bms_StdCha)";
BA_ "UserSigValidity" SG_ 2357404929 CHRG_StndChrgSta 7;
BA_ "RoutingFactor" SG_ 2357404929 CHRG_StndChrgSta 2;
BA_ "Version" SG_ 2357404929 CHRG_StndChrgSta "18.08.07";
BA_ "Description" SG_ 2357404929 CHRG_ChrgCycStrtSta "Charging Cycle Start (CF_Bms_Charging_ST)";
BA_ "UserSigValidity" SG_ 2357404929 CHRG_ChrgCycStrtSta 7;
BA_ "RoutingFactor" SG_ 2357404929 CHRG_ChrgCycStrtSta 2;
BA_ "Version" SG_ 2357404929 CHRG_ChrgCycStrtSta "18.08.07";
BA_ "Description" SG_ 2357404929 CHRG_FulChrgSta "0:None, 1:Fully Charged";
BA_ "UserSigValidity" SG_ 2357404929 CHRG_FulChrgSta 7;
BA_ "RoutingFactor" SG_ 2357404929 CHRG_FulChrgSta 2;
BA_ "Version" SG_ 2357404929 CHRG_FulChrgSta "18.08.07";
BA_ "Description" SG_ 2357404929 CHRG_ChrgSta "0:None, 1:Charging";
BA_ "UserSigValidity" SG_ 2357404929 CHRG_ChrgSta 7;
BA_REL_ "GenSigTimeoutTime" BU_SG_REL_ SWRC SG_ 2357404929 CHRG_ChrgSta 1500;
BA_ "RoutingFactor" SG_ 2357404929 CHRG_ChrgSta 2;
BA_ "Version" SG_ 2357404929 CHRG_ChrgSta "18.08.07";
BA_ "Description" SG_ 2357404929 CHRG_SpplmntChrgSta "Supplementary Charge Status (CF_Bms_SupplyChgStat)";
BA_ "UserSigValidity" SG_ 2357404929 CHRG_SpplmntChrgSta 7;
BA_ "RoutingFactor" SG_ 2357404929 CHRG_SpplmntChrgSta 2;
BA_ "Version" SG_ 2357404929 CHRG_SpplmntChrgSta "18.08.07";
BA_ "Description" SG_ 2357404929 CHRG_LdcInhbtReq "LDC Output Inhibit request";
BA_ "UserSigValidity" SG_ 2357404929 CHRG_LdcInhbtReq 7;
BA_ "RoutingFactor" SG_ 2357404929 CHRG_LdcInhbtReq 2;
BA_ "Version" SG_ 2357404929 CHRG_LdcInhbtReq "18.08.07";
BA_ "Description" SG_ 2357404929 CHRG_NorChgFnshSta "CHRG_ChargeNormalFinishConditionStatus (CF_BMS_ChgFinished)";
BA_ "UserSigValidity" SG_ 2357404929 CHRG_NorChgFnshSta 7;
BA_ "RoutingFactor" SG_ 2357404929 CHRG_NorChgFnshSta 2;
BA_ "Version" SG_ 2357404929 CHRG_NorChgFnshSta "18.08.07";
BA_ "Description" SG_ 2357404929 CHRG_ChrgFnshSta "Standard Charge finish flag (CF_BMS_ChgFinished)";
BA_ "UserSigValidity" SG_ 2357404929 CHRG_ChrgFnshSta 7;
BA_ "RoutingFactor" SG_ 2357404929 CHRG_ChrgFnshSta 2;
BA_ "Version" SG_ 2357404929 CHRG_ChrgFnshSta "18.08.07";
BA_ "Description" SG_ 2357404929 CHRG_Ig3RlyOffReq "IG3 Rly Off Requset";
BA_ "UserSigValidity" SG_ 2357404929 CHRG_Ig3RlyOffReq 7;
BA_ "RoutingFactor" SG_ 2357404929 CHRG_Ig3RlyOffReq 2;
BA_ "Version" SG_ 2357404929 CHRG_Ig3RlyOffReq "17.11.00";
BA_ "Description" SG_ 2357404929 CHRG_PShftChgSta "The Flag To Change P Shift";
BA_ "UserSigValidity" SG_ 2357404929 CHRG_PShftChgSta 7;
BA_ "RoutingFactor" SG_ 2357404929 CHRG_PShftChgSta 2;
BA_ "Version" SG_ 2357404929 CHRG_PShftChgSta "17.11.00";
BA_ "Description" SG_ 2357404929 CHRG_PilotFlSta "Notify Pilotline Fail To Cluster (CF_Bms_Notify_Pilotfail)";
BA_ "UserSigValidity" SG_ 2357404929 CHRG_PilotFlSta 7;
BA_ "RoutingFactor" SG_ 2357404929 CHRG_PilotFlSta 2;
BA_ "Version" SG_ 2357404929 CHRG_PilotFlSta "18.08.07";
BA_ "Description" SG_ 2357404929 CHRG_ObcCmdCurrVal "CC target current command (CR_Bms_ObcCmdCurrt_A)";
BA_ "UserSigValidity" SG_ 2357404929 CHRG_ObcCmdCurrVal 7;
BA_ "RoutingFactor" SG_ 2357404929 CHRG_ObcCmdCurrVal 2;
BA_ "Version" SG_ 2357404929 CHRG_ObcCmdCurrVal "18.08.07";
BA_ "GenMsgSendType" BO_ 2357404930 0;
BA_ "GenMsgCycleTimeFast" BO_ 2357404930 0;
BA_ "GenMsgNrOfRepetition" BO_ 2357404930 0;
BA_ "VFrameFormat" BO_ 2357404930 1;
BA_ "Description" SG_ 2357404930 CHRG_StndChrgRmnTimeVal "Standard Charging remained time (CR_Bms_ScChgRemainedTime_min)";
BA_ "UserSigValidity" SG_ 2357404930 CHRG_StndChrgRmnTimeVal 7;
BA_ "RoutingFactor" SG_ 2357404930 CHRG_StndChrgRmnTimeVal 2;
BA_ "Version" SG_ 2357404930 CHRG_StndChrgRmnTimeVal "18.08.07";
BA_ "Description" SG_ 2357404930 CHRG_ChrgRmnTimeVal "Charging remained time (CR_Bms_ChgRemainedTime_min)";
BA_ "UserSigValidity" SG_ 2357404930 CHRG_ChrgRmnTimeVal 7;
BA_ "RoutingFactor" SG_ 2357404930 CHRG_ChrgRmnTimeVal 2;
BA_ "Version" SG_ 2357404930 CHRG_ChrgRmnTimeVal "18.08.07";
BA_ "Description" SG_ 2357404930 CHRG_ObcRlyOnSta "OBC Relay ON status :0x0:Off, 0x1:On";
BA_ "UserSigValidity" SG_ 2357404930 CHRG_ObcRlyOnSta 7;
BA_ "RoutingFactor" SG_ 2357404930 CHRG_ObcRlyOnSta 2;
BA_ "Version" SG_ 2357404930 CHRG_ObcRlyOnSta "18.08.07";
BA_ "Description" SG_ 2357404930 CHRG_NrmlOpSta "BMS Normal Operation Flag

 <Signal Value Table>

 * Normal operation: 0¡æ1¡æ0¡æ1¡æ... (repetitive change 0¡ê1)

 * Abnormal operation: 0 or 1 fixed";
BA_ "UserSigValidity" SG_ 2357404930 CHRG_NrmlOpSta 7;
BA_ "RoutingFactor" SG_ 2357404930 CHRG_NrmlOpSta 2;
BA_ "Version" SG_ 2357404930 CHRG_NrmlOpSta "17.11.00";
BA_ "Description" SG_ 2357404930 CHRG_ChgLamp_1EA "Charging Lamp Request (1EA Lamp)";
BA_ "UserSigValidity" SG_ 2357404930 CHRG_ChgLamp_1EA 7;
BA_ "RoutingFactor" SG_ 2357404930 CHRG_ChgLamp_1EA 2;
BA_ "Version" SG_ 2357404930 CHRG_ChgLamp_1EA "18.08.07";
BA_ "Description" SG_ 2357404930 CHRG_ObcCmdVoltVal "CV target voltage command (CR_Bms_ObcCmdVolt_V)";
BA_ "UserSigValidity" SG_ 2357404930 CHRG_ObcCmdVoltVal 7;
BA_ "RoutingFactor" SG_ 2357404930 CHRG_ObcCmdVoltVal 2;
BA_ "Version" SG_ 2357404930 CHRG_ObcCmdVoltVal "18.08.07";
BA_ "Description" SG_ 2357404930 CHRG_ObcMainVoltVal "The Mains Voltage of OBC



¡Ø Start Value : Physical value";
BA_ "UserSigValidity" SG_ 2357404930 CHRG_ObcMainVoltVal 7;
BA_ "RoutingFactor" SG_ 2357404930 CHRG_ObcMainVoltVal 2;
BA_ "Version" SG_ 2357404930 CHRG_ObcMainVoltVal "17.11.00";
BA_ "GenMsgSendType" BO_ 2357404931 0;
BA_ "GenMsgCycleTimeFast" BO_ 2357404931 0;
BA_ "GenMsgNrOfRepetition" BO_ 2357404931 0;
BA_ "VFrameFormat" BO_ 2357404931 1;
BA_ "Description" SG_ 2357404931 CHRG_StndChrgRmnTime120Val "Standard Charging(120V) Remained Time (CR_Bms_ScChgRemainedTime_120V)";
BA_ "UserSigValidity" SG_ 2357404931 CHRG_StndChrgRmnTime120Val 7;
BA_ "RoutingFactor" SG_ 2357404931 CHRG_StndChrgRmnTime120Val 2;
BA_ "Version" SG_ 2357404931 CHRG_StndChrgRmnTime120Val "18.08.07";
BA_ "Description" SG_ 2357404931 CHRG_StndChrgRmnTime240Val "Standard Charging(240V) Remained Time";
BA_ "UserSigValidity" SG_ 2357404931 CHRG_StndChrgRmnTime240Val 7;
BA_ "RoutingFactor" SG_ 2357404931 CHRG_StndChrgRmnTime240Val 2;
BA_ "Version" SG_ 2357404931 CHRG_StndChrgRmnTime240Val "17.11.00";
BA_ "Description" SG_ 2357404931 CHRG_ObcOutCurrVal "The OutCurrent Of Obc 



¡Ø Start Value : Physical value";
BA_ "UserSigValidity" SG_ 2357404931 CHRG_ObcOutCurrVal 7;
BA_ "RoutingFactor" SG_ 2357404931 CHRG_ObcOutCurrVal 2;
BA_ "Version" SG_ 2357404931 CHRG_ObcOutCurrVal "17.11.00";
BA_ "Description" SG_ 2357404931 CHRG_DomStndChrgRmnTimeVal "Standard Charging Remained Time-ICCB Domestic";
BA_ "UserSigValidity" SG_ 2357404931 CHRG_DomStndChrgRmnTimeVal 7;
BA_ "RoutingFactor" SG_ 2357404931 CHRG_DomStndChrgRmnTimeVal 2;
BA_ "Version" SG_ 2357404931 CHRG_DomStndChrgRmnTimeVal "17.11.00";
BA_ "Description" SG_ 2357404931 CHRG_ChrgFltSubCodVal "Charging Diagnosis Sub Code";
BA_ "UserSigValidity" SG_ 2357404931 CHRG_ChrgFltSubCodVal 7;
BA_ "RoutingFactor" SG_ 2357404931 CHRG_ChrgFltSubCodVal 2;
BA_ "Version" SG_ 2357404931 CHRG_ChrgFltSubCodVal "17.11.00";
BA_ "GenMsgSendType" BO_ 2357404932 0;
BA_ "GenMsgCycleTimeFast" BO_ 2357404932 0;
BA_ "GenMsgNrOfRepetition" BO_ 2357404932 0;
BA_ "VFrameFormat" BO_ 2357404932 1;
BA_ "Description" SG_ 2357404932 CHRG_ScChgTrgtSocVal "CHRG_Target State Of ScChargeValue (CR_Bms_ScChgTagetSoc)";
BA_ "UserSigValidity" SG_ 2357404932 CHRG_ScChgTrgtSocVal 7;
BA_ "RoutingFactor" SG_ 2357404932 CHRG_ScChgTrgtSocVal 2;
BA_ "Version" SG_ 2357404932 CHRG_ScChgTrgtSocVal "19.01.00";
BA_ "Description" SG_ 2357404932 CHRG_RealStndChrgRmnTimeVal "Standard Charging Remained Time - Real Calculation Time";
BA_ "UserSigValidity" SG_ 2357404932 CHRG_RealStndChrgRmnTimeVal 7;
BA_ "RoutingFactor" SG_ 2357404932 CHRG_RealStndChrgRmnTimeVal 2;
BA_ "Version" SG_ 2357404932 CHRG_RealStndChrgRmnTimeVal "17.11.00";
BA_ "Description" SG_ 2357404932 PHEV_EstChrgRmnTimeVal "Remained Charging Estmate Time for Low Cost Charging";
BA_ "UserSigValidity" SG_ 2357404932 PHEV_EstChrgRmnTimeVal 7;
BA_ "RoutingFactor" SG_ 2357404932 PHEV_EstChrgRmnTimeVal 2;
BA_ "Version" SG_ 2357404932 PHEV_EstChrgRmnTimeVal "17.11.00";
BA_ "Description" SG_ 2357404932 CHRG_ChrgLmp_3EA "CHRG_Charge Lamp(3EA Lamp)";
BA_ "UserSigValidity" SG_ 2357404932 CHRG_ChrgLmp_3EA 7;
BA_ "RoutingFactor" SG_ 2357404932 CHRG_ChrgLmp_3EA 2;
BA_ "Version" SG_ 2357404932 CHRG_ChrgLmp_3EA "18.08.07";
BA_ "Description" SG_ 2357404932 CHRG_EuroStndChrgRmnTimeVal "Standard Charging Remained Time-ICCB Europe";
BA_ "UserSigValidity" SG_ 2357404932 CHRG_EuroStndChrgRmnTimeVal 7;
BA_ "RoutingFactor" SG_ 2357404932 CHRG_EuroStndChrgRmnTimeVal 2;
BA_ "Version" SG_ 2357404932 CHRG_EuroStndChrgRmnTimeVal "17.11.00";
BA_ "GenMsgSendType" BO_ 1079 0;
BA_ "Description" SG_ 1079 CTM_TrailerAct "This signal is used for control the Trailer Act function.";
BA_ "GenSigSendType" SG_ 1079 CTM_TrailerAct 4;
BA_ "UserSigValidity" SG_ 1079 CTM_TrailerAct 3;
BA_REL_ "GenSigTimeoutTime" BU_SG_REL_ BLTN_CAM SG_ 1079 CTM_TrailerAct 1500;
BA_ "NetworkRequest" SG_ 1079 CTM_TrailerAct 0;
BA_ "Version" SG_ 1079 CTM_TrailerAct "18.04.01";
BA_ "Description" SG_ 1079 CTM_ExtTailLmpLftOpnSta "Trailer Exterior Tail Lamp Left OpenStatus";
BA_ "GenSigSendType" SG_ 1079 CTM_ExtTailLmpLftOpnSta 4;
BA_ "UserSigValidity" SG_ 1079 CTM_ExtTailLmpLftOpnSta 3;
BA_ "NetworkRequest" SG_ 1079 CTM_ExtTailLmpLftOpnSta 0;
BA_ "Version" SG_ 1079 CTM_ExtTailLmpLftOpnSta "18.10.07";
BA_ "Description" SG_ 1079 CTM_ExtTailLmpRtOpnSta "Trailer Exterior Tail Lamp Right OpenStatus";
BA_ "GenSigSendType" SG_ 1079 CTM_ExtTailLmpRtOpnSta 4;
BA_ "UserSigValidity" SG_ 1079 CTM_ExtTailLmpRtOpnSta 3;
BA_ "NetworkRequest" SG_ 1079 CTM_ExtTailLmpRtOpnSta 0;
BA_ "Version" SG_ 1079 CTM_ExtTailLmpRtOpnSta "18.10.07";
BA_ "Description" SG_ 1079 CTM_Exra_EbrakSta "Trailer Ebrake Controller ActiveStatus";
BA_ "GenSigSendType" SG_ 1079 CTM_Exra_EbrakSta 4;
BA_ "UserSigValidity" SG_ 1079 CTM_Exra_EbrakSta 0;
BA_ "Version" SG_ 1079 CTM_Exra_EbrakSta "21.06.10";
BA_ "Description" SG_ 1079 CTM_TrlAngl_200ms "This signal is used to provide the Trailer Angle(Kink Angle) between vehicle and trailer(200ms).";
BA_ "GenSigSendType" SG_ 1079 CTM_TrlAngl_200ms 4;
BA_ "UserSigValidity" SG_ 1079 CTM_TrlAngl_200ms 3;
BA_ "Version" SG_ 1079 CTM_TrlAngl_200ms "22.07.06";
BA_ "Description" SG_ 1079 CTM_RearfogAct "This signal is used for display the rear fog lamp mounted on the trailer.";
BA_ "GenSigSendType" SG_ 1079 CTM_RearfogAct 4;
BA_ "UserSigValidity" SG_ 1079 CTM_RearfogAct 3;
BA_ "NetworkRequest" SG_ 1079 CTM_RearfogAct 0;
BA_ "Version" SG_ 1079 CTM_RearfogAct "18.10.07";
BA_ "Description" SG_ 1079 CTM_StpLmpOpnSta "Trailer Stop Lamp OpenStatus";
BA_ "GenSigSendType" SG_ 1079 CTM_StpLmpOpnSta 4;
BA_ "UserSigValidity" SG_ 1079 CTM_StpLmpOpnSta 3;
BA_ "NetworkRequest" SG_ 1079 CTM_StpLmpOpnSta 0;
BA_ "Version" SG_ 1079 CTM_StpLmpOpnSta "18.10.07";
BA_ "Description" SG_ 1079 CTM_TrnSigLmpLftOpnSta "Trailer T/SIG Lamp Left OpenStatus";
BA_ "GenSigSendType" SG_ 1079 CTM_TrnSigLmpLftOpnSta 4;
BA_ "UserSigValidity" SG_ 1079 CTM_TrnSigLmpLftOpnSta 3;
BA_ "NetworkRequest" SG_ 1079 CTM_TrnSigLmpLftOpnSta 0;
BA_ "Version" SG_ 1079 CTM_TrnSigLmpLftOpnSta "18.10.07";
BA_ "Description" SG_ 1079 CTM_TrnSigLmpRtOpnSta "Trailer T/SIG Lamp Right OpenStatus";
BA_ "GenSigSendType" SG_ 1079 CTM_TrnSigLmpRtOpnSta 4;
BA_ "UserSigValidity" SG_ 1079 CTM_TrnSigLmpRtOpnSta 3;
BA_ "NetworkRequest" SG_ 1079 CTM_TrnSigLmpRtOpnSta 0;
BA_ "Version" SG_ 1079 CTM_TrnSigLmpRtOpnSta "18.10.07";
BA_ "GenMsgSendType" BO_ 1085 0;
BA_ "Description" SG_ 1085 DLBCU_ActiveDis "¿¡¾î¼­Æ÷Æ®¸ðµå AVN Ç¥½Ã";
BA_ "GenSigSendType" SG_ 1085 DLBCU_ActiveDis 4;
BA_ "UserSigValidity" SG_ 1085 DLBCU_ActiveDis 1;
BA_REL_ "GenSigTimeoutTime" BU_SG_REL_ CGW_CCU SG_ 1085 DLBCU_ActiveDis 1500;
BA_REL_ "GenSigTimeoutTime" BU_SG_REL_ GW_DPSU SG_ 1085 DLBCU_ActiveDis 1500;
BA_ "NetworkRequest" SG_ 1085 DLBCU_ActiveDis 0;
BA_ "NetworkRequestHoldingTime" SG_ 1085 DLBCU_ActiveDis 5000;
BA_ "Version" SG_ 1085 DLBCU_ActiveDis "21.07.06";
BA_ "Description" SG_ 1085 DLBCU_CellOpt "½ÃÆ® °ø¾Ð ½Ã½ºÅÛ »ç¾ç Á¤º¸ ½ÅÈ£(3Cell:·´¸Ó¼­Æ÷Æ®/5Cell:·³¹öº¼½ºÅÍ/7Cell:·³¹öº¼½ºÅÍÄí¼Ç)";
BA_ "GenSigSendType" SG_ 1085 DLBCU_CellOpt 4;
BA_ "UserSigValidity" SG_ 1085 DLBCU_CellOpt 0;
BA_ "NetworkRequest" SG_ 1085 DLBCU_CellOpt 0;
BA_ "NetworkRequestHoldingTime" SG_ 1085 DLBCU_CellOpt 5000;
BA_ "Version" SG_ 1085 DLBCU_CellOpt "21.07.06";
BA_ "Description" SG_ 1085 DLBCU_BodySpprtSta "Seat Body Support Function USM R Value";
BA_ "GenSigSendType" SG_ 1085 DLBCU_BodySpprtSta 4;
BA_ "UserSigValidity" SG_ 1085 DLBCU_BodySpprtSta 1;
BA_REL_ "GenSigTimeoutTime" BU_SG_REL_ CGW_CCU SG_ 1085 DLBCU_BodySpprtSta 1500;
BA_ "Version" SG_ 1085 DLBCU_BodySpprtSta "18.10.09";
BA_ "Description" SG_ 1085 DLBCU_BodySpprtDis "Seat Body Support Function Display Request";
BA_ "GenSigSendType" SG_ 1085 DLBCU_BodySpprtDis 4;
BA_ "UserSigValidity" SG_ 1085 DLBCU_BodySpprtDis 1;
BA_REL_ "GenSigTimeoutTime" BU_SG_REL_ CGW_CCU SG_ 1085 DLBCU_BodySpprtDis 1500;
BA_ "Version" SG_ 1085 DLBCU_BodySpprtDis "18.10.09";
BA_ "Description" SG_ 1085 DLBCU_MoodTrpyRValueSet "Drive Seat Mood Therapy R Value";
BA_ "GenSigSendType" SG_ 1085 DLBCU_MoodTrpyRValueSet 4;
BA_ "UserSigValidity" SG_ 1085 DLBCU_MoodTrpyRValueSet 3;
BA_REL_ "GenSigTimeoutTime" BU_SG_REL_ CGW_CCU SG_ 1085 DLBCU_MoodTrpyRValueSet 1500;
BA_ "NetworkRequest" SG_ 1085 DLBCU_MoodTrpyRValueSet 0;
BA_ "NetworkRequestHoldingTime" SG_ 1085 DLBCU_MoodTrpyRValueSet 5000;
BA_ "Version" SG_ 1085 DLBCU_MoodTrpyRValueSet "23.02.11";
BA_ "Description" SG_ 1085 DLBCU_MoodTrpyCareSta "Drive Seat Mood Therapy Care Mode R Value";
BA_ "GenSigSendType" SG_ 1085 DLBCU_MoodTrpyCareSta 4;
BA_ "UserSigValidity" SG_ 1085 DLBCU_MoodTrpyCareSta 3;
BA_REL_ "GenSigTimeoutTime" BU_SG_REL_ CGW_CCU SG_ 1085 DLBCU_MoodTrpyCareSta 1500;
BA_ "NetworkRequest" SG_ 1085 DLBCU_MoodTrpyCareSta 0;
BA_ "NetworkRequestHoldingTime" SG_ 1085 DLBCU_MoodTrpyCareSta 5000;
BA_ "Version" SG_ 1085 DLBCU_MoodTrpyCareSta "23.02.11";
BA_ "Description" SG_ 1085 DLBCU_SmartCtrl_Set_Rvalue "ÁÖÇà Áß Çã¸® º¸È£ ±â´É USM µ¿ÀÛ ¼³Á¤ °ª (R Value)";
BA_ "GenSigSendType" SG_ 1085 DLBCU_SmartCtrl_Set_Rvalue 4;
BA_ "UserSigValidity" SG_ 1085 DLBCU_SmartCtrl_Set_Rvalue 0;
BA_REL_ "GenSigTimeoutTime" BU_SG_REL_ CGW_CCU SG_ 1085 DLBCU_SmartCtrl_Set_Rvalue 1500;
BA_ "Version" SG_ 1085 DLBCU_SmartCtrl_Set_Rvalue "21.07.06";
BA_ "Description" SG_ 1085 DLBCU_DrvModUSMSta "µå¶óÀÌºê ¸ðµå ¿¬µ¿ Signal ÇÇµå¹é to AVN";
BA_ "GenSigSendType" SG_ 1085 DLBCU_DrvModUSMSta 4;
BA_ "UserSigValidity" SG_ 1085 DLBCU_DrvModUSMSta 1;
BA_REL_ "GenSigTimeoutTime" BU_SG_REL_ CGW_CCU SG_ 1085 DLBCU_DrvModUSMSta 1500;
BA_ "NetworkRequest" SG_ 1085 DLBCU_DrvModUSMSta 0;
BA_ "NetworkRequestHoldingTime" SG_ 1085 DLBCU_DrvModUSMSta 5000;
BA_ "Version" SG_ 1085 DLBCU_DrvModUSMSta "18.03.07";
BA_ "Description" SG_ 1085 DLBCU_MoodTrpyComfSta "Drive Seat Mood Therapy Comfort Mode R Value";
BA_ "GenSigSendType" SG_ 1085 DLBCU_MoodTrpyComfSta 4;
BA_ "UserSigValidity" SG_ 1085 DLBCU_MoodTrpyComfSta 3;
BA_REL_ "GenSigTimeoutTime" BU_SG_REL_ CGW_CCU SG_ 1085 DLBCU_MoodTrpyComfSta 1500;
BA_ "NetworkRequest" SG_ 1085 DLBCU_MoodTrpyComfSta 0;
BA_ "NetworkRequestHoldingTime" SG_ 1085 DLBCU_MoodTrpyComfSta 5000;
BA_ "Version" SG_ 1085 DLBCU_MoodTrpyComfSta "23.02.11";
BA_ "Description" SG_ 1085 DLBCU_ActiveStrSta "¿¡¾î¼­Æ÷Æ® ¸ðµå °­µµ Signal ÇÇµå¹é to AVN";
BA_ "GenSigSendType" SG_ 1085 DLBCU_ActiveStrSta 4;
BA_ "UserSigValidity" SG_ 1085 DLBCU_ActiveStrSta 1;
BA_REL_ "GenSigTimeoutTime" BU_SG_REL_ CGW_CCU SG_ 1085 DLBCU_ActiveStrSta 1500;
BA_ "NetworkRequest" SG_ 1085 DLBCU_ActiveStrSta 0;
BA_ "NetworkRequestHoldingTime" SG_ 1085 DLBCU_ActiveStrSta 5000;
BA_ "Version" SG_ 1085 DLBCU_ActiveStrSta "18.03.07";
BA_ "Description" SG_ 1085 DLBCU_ActiveTimeSta "¿¡¾î¼­Æ÷Æ® Àç»ý½Ã°£ Signal ÇÇµå¹é to AVN";
BA_ "GenSigSendType" SG_ 1085 DLBCU_ActiveTimeSta 4;
BA_ "UserSigValidity" SG_ 1085 DLBCU_ActiveTimeSta 1;
BA_REL_ "GenSigTimeoutTime" BU_SG_REL_ CGW_CCU SG_ 1085 DLBCU_ActiveTimeSta 1500;
BA_ "NetworkRequest" SG_ 1085 DLBCU_ActiveTimeSta 0;
BA_ "NetworkRequestHoldingTime" SG_ 1085 DLBCU_ActiveTimeSta 5000;
BA_ "Version" SG_ 1085 DLBCU_ActiveTimeSta "21.07.06";
BA_ "GenMsgSendType" BO_ 2189468929 0;
BA_ "GenMsgCycleTime" BO_ 2189468929 10;
BA_ "GenMsgCycleTimeFast" BO_ 2189468929 0;
BA_ "GenMsgNrOfRepetition" BO_ 2189468929 0;
BA_ "GenMsgDelayTime" BO_ 2189468929 0;
BA_ "VFrameFormat" BO_ 2189468929 1;
BA_ "Description" SG_ 2189468929 ECS_Crc4Val "The data area for CRC calculation is based on the data length (DLC) of the message DB.

The CRC shall be calculated over the entire data block (excluding the CRC bytes) including the user data, alive counter and Data ID



- CRC Polynomial (0x1021) , Initial Value : 0xFFFF, XOR value : 0x0000, Data ID : Message ID + 0xF800 

- The initial value is for CRC calculation and the message should be sent with the calculated result value. 

- The mathematical expression to 16 bit CRC polynomial is given here. G(x) = x16 + x12 + x5 + 1



<For CRC calculation of CAN-FD Msg for HS CAN domain ECUs>



- HS-CAN Messages that routed from CAN-FD domain are using 29 bit Extended CAN ID and splitted into 8 Byte Messages.

(from 1 to 4 Msgs, depending on source CAN-FD Msg¡¯s DLC)

- For splitted CAN-FD Msgs¡¯ CRC calculation, HS CAN ECUs should use source CAN-FD Msg¡¯s original STD ID. 

- The original STD ID can be read from Ext ID¡¯s 4~6th Byte.

Eg. STD 0x6AA : EXT SPLT 0x1A8[6AA]01 / 0x1A8[6AA]02 / 0x1A8[6AA]03 / 0x1A8[6AA]04 

(2~4th splitited Msgs can be omitted depending on source CAN-FD Msg¡¯s DLC)

- Aslo, HS-CAN ECUs should use merged data block (from whole splitted Msg) for CRC calculation.";
BA_ "GenSigStartValue" SG_ 2189468929 ECS_Crc4Val 65535;
BA_ "UserSigValidity" SG_ 2189468929 ECS_Crc4Val 3;
BA_ "Version" SG_ 2189468929 ECS_Crc4Val "21.09.03";
BA_ "Description" SG_ 2189468929 ECS_AlvCnt4Val "For the first transmission request for a data element the counter shall be initialized with 0 and shall be incremented by 1 for every subsequent send request. 

When the counter reaches the maximum value(0xFF), then it shall restart with 0 for the next send request";
BA_ "UserSigValidity" SG_ 2189468929 ECS_AlvCnt4Val 3;
BA_ "Version" SG_ 2189468929 ECS_AlvCnt4Val "21.09.03";
BA_ "Description" SG_ 2189468929 ECSIVSS_FLWhlVrtclAccelSnsrVal "Wheel Vertical Acceleration Sensor - FL

0x0000~0x03FF:-13.3g(102)~13.3g(921)/0x0400~0x0FFE:Not used/0x0FFF:Invalid



 /* Wheel G value, 102:-13.3g, 921 : +13.3g */

Value : 102(-13.3G) ~ 921(+13.3G)

If Value <= 102, Then Value = -13.3g

If Value >= 921 Then  Value = 13.3g";
BA_ "GenSigStartValue" SG_ 2189468929 ECSIVSS_FLWhlVrtclAccelSnsrVal 512;
BA_ "UserSigValidity" SG_ 2189468929 ECSIVSS_FLWhlVrtclAccelSnsrVal 3;
BA_ "Version" SG_ 2189468929 ECSIVSS_FLWhlVrtclAccelSnsrVal "18.07.04";
BA_ "Description" SG_ 2189468929 ECSIVSS_FRWhlVrtclAccelSnsrVal "Wheel Vertical Acceleration Sensor - FR

0x0000~0x03FF:-13.3g(102)~13.3g(921)/0x0400~0x0FFE:Not used/0x0FFF:Invalid



 /* Wheel G value, 102:-13.3g, 921 : +13.3g */

Value : 102(-13.3G) ~ 921(+13.3G)

If Value <= 102, Then Value = -13.3g

If Value >= 921 Then  Value = 13.3g";
BA_ "GenSigStartValue" SG_ 2189468929 ECSIVSS_FRWhlVrtclAccelSnsrVal 512;
BA_ "UserSigValidity" SG_ 2189468929 ECSIVSS_FRWhlVrtclAccelSnsrVal 3;
BA_ "Version" SG_ 2189468929 ECSIVSS_FRWhlVrtclAccelSnsrVal "18.07.04";
BA_ "Description" SG_ 2189468929 ECSIVSS_FLBodyAccelSnsrVal "Body Vertical Acceleration Sensor - FL

0x0000~0x03FF:-1g(102)~1g(921)/0x0400~0x0FFE:Not used/0x0FFF:Invalid



 /* Body G value, 102:-1g, 921 : +1g */

Value : 102(-1g) ~ 921(+1g)

If Value <= 102, Then Value = -1g

If Value >= 921 Then  Value = 1g";
BA_ "GenSigStartValue" SG_ 2189468929 ECSIVSS_FLBodyAccelSnsrVal 512;
BA_ "UserSigValidity" SG_ 2189468929 ECSIVSS_FLBodyAccelSnsrVal 3;
BA_ "Version" SG_ 2189468929 ECSIVSS_FLBodyAccelSnsrVal "18.07.04";
BA_ "GenMsgSendType" BO_ 2189468930 0;
BA_ "GenMsgCycleTime" BO_ 2189468930 10;
BA_ "GenMsgCycleTimeFast" BO_ 2189468930 0;
BA_ "GenMsgNrOfRepetition" BO_ 2189468930 0;
BA_ "GenMsgDelayTime" BO_ 2189468930 0;
BA_ "VFrameFormat" BO_ 2189468930 1;
BA_ "Description" SG_ 2189468930 ECSIVSS_FRBodyAccelSnsrVal "Body Vertical Acceleration Sensor - FR

0x0000~0x03FF:-1g(102)~1g(921)/0x0400~0x0FFE:Not used/0x0FFF:Invalid



 /* Body G value, 102:-1g, 921 : +1g */

Value : 102(-1g) ~ 921(+1g)

If Value <= 102, Then Value = -1g

If Value >= 921 Then  Value = 1g";
BA_ "GenSigStartValue" SG_ 2189468930 ECSIVSS_FRBodyAccelSnsrVal 512;
BA_ "UserSigValidity" SG_ 2189468930 ECSIVSS_FRBodyAccelSnsrVal 3;
BA_ "Version" SG_ 2189468930 ECSIVSS_FRBodyAccelSnsrVal "18.07.04";
BA_ "Description" SG_ 2189468930 ECSIVSS_RrBodyAccelSnsrVal "Body Vertical Acceleration Sensor - Rear

0x0000~0x03FF:-1g(102)~1g(921)/0x0400~0x0FFE:Not used/0x0FFF:Invalid



 /* Body G value, 102:-1g, 921 : +1g */

Value : 102(-1g) ~ 921(+1g)

If Value <= 102, Then Value = -1g

If Value >= 921 Then  Value = 1g";
BA_ "GenSigStartValue" SG_ 2189468930 ECSIVSS_RrBodyAccelSnsrVal 512;
BA_ "UserSigValidity" SG_ 2189468930 ECSIVSS_RrBodyAccelSnsrVal 3;
BA_ "Version" SG_ 2189468930 ECSIVSS_RrBodyAccelSnsrVal "18.07.04";
BA_ "Description" SG_ 2189468930 ECSIVSS_EcuLongAccelSnsrVal "ECU Inertial Sensor - Acceleration (Longitudinal)";
BA_ "UserSigValidity" SG_ 2189468930 ECSIVSS_EcuLongAccelSnsrVal 3;
BA_ "Version" SG_ 2189468930 ECSIVSS_EcuLongAccelSnsrVal "18.11.06";
BA_ "Description" SG_ 2189468930 ECSIVSS_EcuLatAccelSnsrVal "ECU Inertial Sensor - Acceleration (Lateral)";
BA_ "UserSigValidity" SG_ 2189468930 ECSIVSS_EcuLatAccelSnsrVal 3;
BA_ "Version" SG_ 2189468930 ECSIVSS_EcuLatAccelSnsrVal "18.11.06";
BA_ "Description" SG_ 2189468930 ECSIVSS_EcuVertAccelSnsrVal "ECU Inertial Sensor - Acceleration (Vertical)";
BA_ "UserSigValidity" SG_ 2189468930 ECSIVSS_EcuVertAccelSnsrVal 3;
BA_ "Version" SG_ 2189468930 ECSIVSS_EcuVertAccelSnsrVal "18.11.06";
BA_ "Description" SG_ 2189468930 ECSIVSS_RdIndxVal "Road Index";
BA_ "UserSigValidity" SG_ 2189468930 ECSIVSS_RdIndxVal 3;
BA_ "Version" SG_ 2189468930 ECSIVSS_RdIndxVal "17.11.00";
BA_ "GenMsgSendType" BO_ 2189468931 0;
BA_ "GenMsgCycleTime" BO_ 2189468931 10;
BA_ "GenMsgCycleTimeFast" BO_ 2189468931 0;
BA_ "GenMsgNrOfRepetition" BO_ 2189468931 0;
BA_ "GenMsgDelayTime" BO_ 2189468931 0;
BA_ "VFrameFormat" BO_ 2189468931 1;
BA_ "Description" SG_ 2189468931 ECSIVSS_EcuRollGyroSnsrVal "ECU Inertial Sensor - Gyro (Roll)";
BA_ "UserSigValidity" SG_ 2189468931 ECSIVSS_EcuRollGyroSnsrVal 3;
BA_ "Version" SG_ 2189468931 ECSIVSS_EcuRollGyroSnsrVal "18.11.06";
BA_ "Description" SG_ 2189468931 ECSIVSS_EcuPitchGyroSnsrVal "ECU Inertial Sensor - Gyro (Pitch)";
BA_ "UserSigValidity" SG_ 2189468931 ECSIVSS_EcuPitchGyroSnsrVal 3;
BA_ "Version" SG_ 2189468931 ECSIVSS_EcuPitchGyroSnsrVal "18.11.06";
BA_ "Description" SG_ 2189468931 ECSIVSS_EcuYawGyroSnsrVal "ECU Inertial Sensor - Gyro (Yaw)";
BA_ "UserSigValidity" SG_ 2189468931 ECSIVSS_EcuYawGyroSnsrVal 3;
BA_ "Version" SG_ 2189468931 ECSIVSS_EcuYawGyroSnsrVal "18.11.06";
BA_ "Description" SG_ 2189468931 ECSEMCU_PrvMode "Mode of Preview ECS (0x0~0xF)

It represents the mode defined in Preview ECS according to the distance from the bump.";
BA_ "UserSigValidity" SG_ 2189468931 ECSEMCU_PrvMode 3;
BA_ "Version" SG_ 2189468931 ECSEMCU_PrvMode "22.10.05";
BA_ "Description" SG_ 2189468931 ECSEMCU_PrvECSflag "Flag of Preview ECS to control EMCU (0x0~0xF)

If necessary, ECS determines and transmits the operating conditions of the EMCU.";
BA_ "UserSigValidity" SG_ 2189468931 ECSEMCU_PrvECSflag 3;
BA_ "Version" SG_ 2189468931 ECSEMCU_PrvECSflag "22.10.05";
BA_ "GenMsgSendType" BO_ 2164278529 0;
BA_ "GenMsgCycleTime" BO_ 2164278529 50;
BA_ "GenMsgCycleTimeFast" BO_ 2164278529 0;
BA_ "GenMsgNrOfRepetition" BO_ 2164278529 0;
BA_ "VFrameFormat" BO_ 2164278529 1;
BA_ "Description" SG_ 2164278529 HTCU_Crc4Val "The data area for CRC calculation is based on the data length (DLC) of the message DB.

The CRC shall be calculated over the entire data block (excluding the CRC bytes) including the user data, alive counter and Data ID

 

- CRC Polynomial (0x1021) , Initial Value : 0xFFFF, XOR value : 0x0000, Data ID : Message ID + 0xF800 

- The initial value is for CRC calculation and the message should be sent with the calculated result value. 

- The mathematical expression to 16 bit CRC polynomial is given here. G(x) = x16 + x12 + x5 + 1";
BA_ "GenSigStartValue" SG_ 2164278529 HTCU_Crc4Val 65535;
BA_ "UserSigValidity" SG_ 2164278529 HTCU_Crc4Val 3;
BA_ "RoutingFactor" SG_ 2164278529 HTCU_Crc4Val 5;
BA_ "Version" SG_ 2164278529 HTCU_Crc4Val "18.11.08";
BA_ "Description" SG_ 2164278529 HTCU_AlvCnt4Val "For the first transmission request for a data element the counter shall be initialized with 0 and shall be incremented by 1 for every subsequent send request. 

When the counter reaches the maximum value(0xFF), then it shall restart with 0 for the next send request";
BA_ "UserSigValidity" SG_ 2164278529 HTCU_AlvCnt4Val 3;
BA_ "RoutingFactor" SG_ 2164278529 HTCU_AlvCnt4Val 5;
BA_ "Version" SG_ 2164278529 HTCU_AlvCnt4Val "18.11.08";
BA_ "Description" SG_ 2164278529 HTCU_TrgtGearSta "HTCU_TrgtGearSta informs about the speed, which is currently engaged in the gearbox, or, in case of a gear change (HTCU_GearChgSta), which speed is reached.

Note: Gear changes covering more than one speed are also possible.

In the P and N positions, the frictional connection is interrupted hydraulically.

Depending on the type of error, the 3rd or 4th (forward) speed, and the R (reverse) speed are engaged in the limp home program.";
BA_ "UserSigValidity" SG_ 2164278529 HTCU_TrgtGearSta 3;
BA_ "RoutingFactor" SG_ 2164278529 HTCU_TrgtGearSta 5;
BA_ "Version" SG_ 2164278529 HTCU_TrgtGearSta "18.12.07";
BA_ "Description" SG_ 2164278529 HTCU_RdySta "Flag that the HTCU is ready to work. (In fact, this flag is true from the moment that CAN is working. So, normally no ¡°false¡± will be sent on CAN.) This flag does not show that everything is alright in the HTCU. This information is given in the warning and fault flags.";
BA_ "UserSigValidity" SG_ 2164278529 HTCU_RdySta 3;
BA_ "RoutingFactor" SG_ 2164278529 HTCU_RdySta 5;
BA_ "Version" SG_ 2164278529 HTCU_RdySta "18.08.02";
BA_ "Description" SG_ 2164278529 HTCU_GearChgSta "HTCU_GearChgSta indicates whether a gear change is being executed in the gearbox.

Note : Gear change means a gear shift at D-range and Garage shift(PRND).";
BA_ "UserSigValidity" SG_ 2164278529 HTCU_GearChgSta 3;
BA_ "RoutingFactor" SG_ 2164278529 HTCU_GearChgSta 5;
BA_ "Version" SG_ 2164278529 HTCU_GearChgSta "18.08.02";
BA_ "Description" SG_ 2164278529 HTCU_TqRdctnPcVal "The HTCU requests a torque reduction via the signal CR_Tcu_TqInt_Pc to the ECU and MCU.

The requested torque HTCU_TqRdctnPcVal refers to a maximum torque CR_Ems_TqStd_Nm. This conversion into a physical quantity provides a range of CR_Ems_TqStd_Nm of 0 ..199.61%.

There is no specific phase relationship between the output and any other signal.

Conversion : (PH) = 0.390625 * (HEX) [%]";
BA_ "GenSigStartValue" SG_ 2164278529 HTCU_TqRdctnPcVal 511;
BA_ "UserSigValidity" SG_ 2164278529 HTCU_TqRdctnPcVal 3;
BA_ "RoutingFactor" SG_ 2164278529 HTCU_TqRdctnPcVal 5;
BA_ "Version" SG_ 2164278529 HTCU_TqRdctnPcVal "18.08.02";
BA_ "Description" SG_ 2164278529 HTCU_FltSta "HTCU_FltSta informs about status of transmission control.



<Value Description>

Bit 0: HTCU Diagnostic failure

Bit 1: HTCU Diagnostic failure ? Limphome activated

Bit 2: OPU/EOP Diagnostic failure";
BA_ "UserSigValidity" SG_ 2164278529 HTCU_FltSta 3;
BA_ "RoutingFactor" SG_ 2164278529 HTCU_FltSta 5;
BA_ "Version" SG_ 2164278529 HTCU_FltSta "18.08.02";
BA_ "Description" SG_ 2164278529 HTCU_GearSlctrDis "Position (P, R, N..), which was identified by the gear selector.

In case the gear selector is in a intermediate position, the last clear recognized position is used.

There is no specific phase relationship between the output and any other signal.";
BA_ "GenSigStartValue" SG_ 2164278529 HTCU_GearSlctrDis 9;
BA_ "UserSigValidity" SG_ 2164278529 HTCU_GearSlctrDis 3;
BA_ "RoutingFactor" SG_ 2164278529 HTCU_GearSlctrDis 5;
BA_ "Version" SG_ 2164278529 HTCU_GearSlctrDis "18.08.02";
BA_ "Description" SG_ 2164278529 HTCU_SlwTqRdctnPcVal "The HTCU requests a slow torque reduction via the signal HTCU_TqRdctnPcVal to the ECU and MCU.";
BA_ "GenSigStartValue" SG_ 2164278529 HTCU_SlwTqRdctnPcVal 511;
BA_ "UserSigValidity" SG_ 2164278529 HTCU_SlwTqRdctnPcVal 3;
BA_ "RoutingFactor" SG_ 2164278529 HTCU_SlwTqRdctnPcVal 5;
BA_ "Version" SG_ 2164278529 HTCU_SlwTqRdctnPcVal "18.08.02";
BA_ "UserSigValidity" SG_ 2164278529 HTCU_PddlShftUpDn 3;
BA_ "RoutingFactor" SG_ 2164278529 HTCU_PddlShftUpDn 5;
BA_ "Version" SG_ 2164278529 HTCU_PddlShftUpDn "22.10.20";
BA_ "Description" SG_ 2164278529 HTCU_FanCtrlReq "Fan control request by OPU";
BA_ "TimeoutValue" SG_ 2164278529 HTCU_FanCtrlReq "0x0";
BA_ "UserSigValidity" SG_ 2164278529 HTCU_FanCtrlReq 3;
BA_ "RoutingFactor" SG_ 2164278529 HTCU_FanCtrlReq 5;
BA_ "Version" SG_ 2164278529 HTCU_FanCtrlReq "21.07.00";
BA_ "GenMsgSendType" BO_ 2164278530 0;
BA_ "GenMsgCycleTime" BO_ 2164278530 50;
BA_ "GenMsgCycleTimeFast" BO_ 2164278530 0;
BA_ "GenMsgNrOfRepetition" BO_ 2164278530 0;
BA_ "VFrameFormat" BO_ 2164278530 1;
BA_ "Description" SG_ 2164278530 HTCU_VehSpdKphVal "The vehicle speed calculated by HTCU is transferred.

If a vehicle has no vehicle speed sensor, no wheel speed sensor and no ABS(ESC) then it is impossible for an EMS to calculate veficle speed. In this case a HTCU should calculate vehicle speed and send to other ECUs.

The calculation can be done with output speed of gearbox, final gear ratio and fixed actual radius of a tire.";
BA_ "UserSigValidity" SG_ 2164278530 HTCU_VehSpdKphVal 3;
BA_ "RoutingFactor" SG_ 2164278530 HTCU_VehSpdKphVal 5;
BA_ "Version" SG_ 2164278530 HTCU_VehSpdKphVal "18.08.02";
BA_ "Description" SG_ 2164278530 HTCU_HvOpuSpdCmdRpmVal "CR_Tcu_OpuSpdCmd_Rpm informs about the external oil pump speed.";
BA_ "UserSigValidity" SG_ 2164278530 HTCU_HvOpuSpdCmdRpmVal 3;
BA_ "RoutingFactor" SG_ 2164278530 HTCU_HvOpuSpdCmdRpmVal 5;
BA_ "Version" SG_ 2164278530 HTCU_HvOpuSpdCmdRpmVal "17.11.00";
BA_ "UserSigValidity" SG_ 2164278530 HTCU_TrgtShftClsCCanSta 3;
BA_ "RoutingFactor" SG_ 2164278530 HTCU_TrgtShftClsCCanSta 5;
BA_ "Version" SG_ 2164278530 HTCU_TrgtShftClsCCanSta "17.11.00";
BA_ "Description" SG_ 2164278530 HTCU_CtrlablSta "This signal indicates the status of the TCU control which normally works by hydraulic pressure in the T/M";
BA_ "UserSigValidity" SG_ 2164278530 HTCU_CtrlablSta 3;
BA_ "RoutingFactor" SG_ 2164278530 HTCU_CtrlablSta 5;
BA_ "Version" SG_ 2164278530 HTCU_CtrlablSta "20.10.02";
BA_ "Description" SG_ 2164278530 HTCU_PrgrmSta "This signal informs about current program status in HTCU";
BA_ "UserSigValidity" SG_ 2164278530 HTCU_PrgrmSta 3;
BA_ "RoutingFactor" SG_ 2164278530 HTCU_PrgrmSta 5;
BA_ "Version" SG_ 2164278530 HTCU_PrgrmSta "17.11.00";
BA_ "Description" SG_ 2164278530 HTCU_FsCltchLmphmActvSta "This signal informs about engine clutch limp-home control activation";
BA_ "UserSigValidity" SG_ 2164278530 HTCU_FsCltchLmphmActvSta 3;
BA_ "RoutingFactor" SG_ 2164278530 HTCU_FsCltchLmphmActvSta 5;
BA_ "Version" SG_ 2164278530 HTCU_FsCltchLmphmActvSta "17.11.00";
BA_ "Description" SG_ 2164278530 HTCU_FsIdleTrgtRpmVal "Request idle target rpm for engine clutch limp-home control";
BA_ "UserSigValidity" SG_ 2164278530 HTCU_FsIdleTrgtRpmVal 3;
BA_ "RoutingFactor" SG_ 2164278530 HTCU_FsIdleTrgtRpmVal 5;
BA_ "Version" SG_ 2164278530 HTCU_FsIdleTrgtRpmVal "17.11.00";
BA_ "Description" SG_ 2164278530 HTCU_FsAddtnlTqLssPcVal "Additional torque loss for engine clutch limp-home control";
BA_ "UserSigValidity" SG_ 2164278530 HTCU_FsAddtnlTqLssPcVal 3;
BA_ "RoutingFactor" SG_ 2164278530 HTCU_FsAddtnlTqLssPcVal 5;
BA_ "Version" SG_ 2164278530 HTCU_FsAddtnlTqLssPcVal "17.11.00";
BA_ "Description" SG_ 2164278530 HTCU_VehSpdDcmlKphVal "The signal HTCU_VehSpdDcmlKphVal means the value which is below decimal point of the vehicle speed.

For instance, if a vehicle speed is 13.75Km/h, HTCU_VehSpdKphVal means 13Km/h and HTCU_VehSpdDcmlKphVal means 0.75Km/h.

(Min ~ Max: 0.00 ~ 0.99)";
BA_ "UserSigValidity" SG_ 2164278530 HTCU_VehSpdDcmlKphVal 3;
BA_ "RoutingFactor" SG_ 2164278530 HTCU_VehSpdDcmlKphVal 5;
BA_ "Version" SG_ 2164278530 HTCU_VehSpdDcmlKphVal "18.12.07";
BA_ "GenMsgSendType" BO_ 2164278531 0;
BA_ "GenMsgCycleTime" BO_ 2164278531 50;
BA_ "GenMsgCycleTimeFast" BO_ 2164278531 0;
BA_ "GenMsgNrOfRepetition" BO_ 2164278531 0;
BA_ "VFrameFormat" BO_ 2164278531 1;
BA_ "Description" SG_ 2164278531 HTCU_FsEngTqRdctnPcVal "This signal informs about engine torque reduction request for engine clutch limp-home control";
BA_ "GenSigStartValue" SG_ 2164278531 HTCU_FsEngTqRdctnPcVal 255;
BA_ "UserSigValidity" SG_ 2164278531 HTCU_FsEngTqRdctnPcVal 3;
BA_ "RoutingFactor" SG_ 2164278531 HTCU_FsEngTqRdctnPcVal 5;
BA_ "Version" SG_ 2164278531 HTCU_FsEngTqRdctnPcVal "19.02.06";
BA_ "Description" SG_ 2164278531 HTCU_RapidKDReq "Rapid K/D Shift Request";
BA_ "UserSigValidity" SG_ 2164278531 HTCU_RapidKDReq 3;
BA_ "RoutingFactor" SG_ 2164278531 HTCU_RapidKDReq 5;
BA_ "Version" SG_ 2164278531 HTCU_RapidKDReq "17.11.00";
BA_ "UserSigValidity" SG_ 2164278531 HTCU_CurrGearSta 3;
BA_ "RoutingFactor" SG_ 2164278531 HTCU_CurrGearSta 5;
BA_ "Version" SG_ 2164278531 HTCU_CurrGearSta "18.12.07";
BA_ "Description" SG_ 2164278531 HTCU_GearShftUpDisGSI "Gear Shift-up display status for Gear shift indicator (EU Regulations)";
BA_ "UserSigValidity" SG_ 2164278531 HTCU_GearShftUpDisGSI 3;
BA_ "RoutingFactor" SG_ 2164278531 HTCU_GearShftUpDisGSI 5;
BA_ "Version" SG_ 2164278531 HTCU_GearShftUpDisGSI "18.08.01";
BA_ "Description" SG_ 2164278531 HTCU_GearShftDnDisGSI "Gear Shift-down display status for Gear shift indicator (EU Regulations)";
BA_ "UserSigValidity" SG_ 2164278531 HTCU_GearShftDnDisGSI 3;
BA_ "RoutingFactor" SG_ 2164278531 HTCU_GearShftDnDisGSI 5;
BA_ "Version" SG_ 2164278531 HTCU_GearShftDnDisGSI "18.08.01";
BA_ "Description" SG_ 2164278531 HTCU_TrgtGearStaGSI "Target Gear for Gear shift indicator (EU Regulations)";
BA_ "UserSigValidity" SG_ 2164278531 HTCU_TrgtGearStaGSI 3;
BA_ "RoutingFactor" SG_ 2164278531 HTCU_TrgtGearStaGSI 5;
BA_ "Version" SG_ 2164278531 HTCU_TrgtGearStaGSI "19.02.06";
BA_ "Description" SG_ 2164278531 HTCU_SolBSta "Status of On/Off Solenoid B";
BA_ "UserSigValidity" SG_ 2164278531 HTCU_SolBSta 3;
BA_ "RoutingFactor" SG_ 2164278531 HTCU_SolBSta 5;
BA_ "Version" SG_ 2164278531 HTCU_SolBSta "18.08.01";
BA_ "Description" SG_ 2164278531 HTCU_TqRdctnNegativePcVal "Torque intervention for negative reduction,referred to the indicated torque.





<Range>

-200 ~ 199.61% = 0x200 ~ 0x1FF



<Conversion>

If MSB of high byte is 1,(PH) = 0.390625 x (HEX) - 400[%],

Else,(PH) = 0.390625 x (HEX) [%]";
BA_ "GenSigStartValue" SG_ 2164278531 HTCU_TqRdctnNegativePcVal 8191;
BA_ "UserSigValidity" SG_ 2164278531 HTCU_TqRdctnNegativePcVal 3;
BA_ "RoutingFactor" SG_ 2164278531 HTCU_TqRdctnNegativePcVal 5;
BA_ "Version" SG_ 2164278531 HTCU_TqRdctnNegativePcVal "23.03.00";
BA_ "Description" SG_ 2164278531 HTCU_LnPrsBarVal "This signal informs about the Transmission valve body line pressure command from HTCU";
BA_ "UserSigValidity" SG_ 2164278531 HTCU_LnPrsBarVal 3;
BA_ "RoutingFactor" SG_ 2164278531 HTCU_LnPrsBarVal 5;
BA_ "Version" SG_ 2164278531 HTCU_LnPrsBarVal "17.11.00";
BA_ "GenMsgCycleTime" BO_ 1221 0;
BA_ "Description" SG_ 1221 HU_ChgInCurrModSet "Charge current set signal";
BA_ "GenSigSendType" SG_ 1221 HU_ChgInCurrModSet 4;
BA_ "UserSigValidity" SG_ 1221 HU_ChgInCurrModSet 7;
BA_ "Version" SG_ 1221 HU_ChgInCurrModSet "19.08.06";
BA_ "Description" SG_ 1221 SWRC_Sensitivity_SET "This signal is for the SWRC Optical Switch Sensitivity Setting";
BA_ "GenSigSendType" SG_ 1221 SWRC_Sensitivity_SET 4;
BA_ "GenSigStartValue" SG_ 1221 SWRC_Sensitivity_SET 3;
BA_ "UserSigValidity" SG_ 1221 SWRC_Sensitivity_SET 3;
BA_REL_ "GenSigTimeoutTime" BU_SG_REL_ SWRC SG_ 1221 SWRC_Sensitivity_SET 0;
BA_ "Version" SG_ 1221 SWRC_Sensitivity_SET "19.12.00";
BA_ "Description" SG_ 1221 HU_EV_WinterMode "18.08.09_";
BA_ "GenSigSendType" SG_ 1221 HU_EV_WinterMode 4;
BA_ "GenSigStartValue" SG_ 1221 HU_EV_WinterMode 3;
BA_ "UserSigValidity" SG_ 1221 HU_EV_WinterMode 7;
BA_ "Version" SG_ 1221 HU_EV_WinterMode "18.09.04";
BA_ "Description" SG_ 1221 HU_TgSoc_ScChg_Set "18.08.09_";
BA_ "GenSigSendType" SG_ 1221 HU_TgSoc_ScChg_Set 4;
BA_ "GenSigStartValue" SG_ 1221 HU_TgSoc_ScChg_Set 255;
BA_ "UserSigValidity" SG_ 1221 HU_TgSoc_ScChg_Set 7;
BA_ "Version" SG_ 1221 HU_TgSoc_ScChg_Set "18.09.04";
BA_ "Description" SG_ 1221 HU_TgSoc_QcChg_Set "18.08.09_";
BA_ "GenSigSendType" SG_ 1221 HU_TgSoc_QcChg_Set 4;
BA_ "GenSigStartValue" SG_ 1221 HU_TgSoc_QcChg_Set 255;
BA_ "UserSigValidity" SG_ 1221 HU_TgSoc_QcChg_Set 7;
BA_ "Version" SG_ 1221 HU_TgSoc_QcChg_Set "18.09.04";
BA_ "Description" SG_ 1221 HU_UserApproval "Signal to send user decision on OTA approval.";
BA_ "GenSigSendType" SG_ 1221 HU_UserApproval 4;
BA_ "UserSigValidity" SG_ 1221 HU_UserApproval 0;
BA_ "Version" SG_ 1221 HU_UserApproval "23.02.02";
BA_ "Description" SG_ 1221 HU_OtaInfomationReq "Á¦¾î±â OTA °ü·Ã ÇÊ¿ä Á¤º¸¸¦ ¿äÃ»ÇÏ´Â ½ÅÈ£ (SW ¹öÀü, What's New, Download ÁøÇàÀ², Update ÁøÇàÀ²)";
BA_ "GenSigSendType" SG_ 1221 HU_OtaInfomationReq 4;
BA_ "UserSigValidity" SG_ 1221 HU_OtaInfomationReq 0;
BA_ "Version" SG_ 1221 HU_OtaInfomationReq "19.12.01";
BA_ "GenMsgSendType" BO_ 1076 0;
BA_ "GenSigSendType" SG_ 1076 IAU_ProfileIDRVal 4;
BA_ "UserSigValidity" SG_ 1076 IAU_ProfileIDRVal 0;
BA_REL_ "GenSigTimeoutTime" BU_SG_REL_ BLTN_CAM SG_ 1076 IAU_ProfileIDRVal 1500;
BA_REL_ "GenSigTimeoutTime" BU_SG_REL_ GW_DLBCU SG_ 1076 IAU_ProfileIDRVal 1500;
BA_REL_ "GenSigTimeoutTime" BU_SG_REL_ GW_DPSU SG_ 1076 IAU_ProfileIDRVal 1500;
BA_REL_ "GenSigTimeoutTime" BU_SG_REL_ RCM SG_ 1076 IAU_ProfileIDRVal 1500;
BA_REL_ "GenSigTimeoutTime" BU_SG_REL_ RWPC SG_ 1076 IAU_ProfileIDRVal 1500;
BA_REL_ "GenSigTimeoutTime" BU_SG_REL_ SGU SG_ 1076 IAU_ProfileIDRVal 1500;
BA_REL_ "GenSigTimeoutTime" BU_SG_REL_ WPC SG_ 1076 IAU_ProfileIDRVal 1500;
BA_REL_ "GenSigTimeoutTime" BU_SG_REL_ WPC2 SG_ 1076 IAU_ProfileIDRVal 1500;
BA_ "NetworkRequest" SG_ 1076 IAU_ProfileIDRVal 0;
BA_ "NetworkRequestHoldingTime" SG_ 1076 IAU_ProfileIDRVal 5000;
BA_ "Version" SG_ 1076 IAU_ProfileIDRVal "23.02.02";
BA_ "GenSigSendType" SG_ 1076 IAU_DigitalKeyProcessingSta 4;
BA_ "UserSigValidity" SG_ 1076 IAU_DigitalKeyProcessingSta 3;
BA_ "NetworkRequest" SG_ 1076 IAU_DigitalKeyProcessingSta 0;
BA_ "NetworkRequestHoldingTime" SG_ 1076 IAU_DigitalKeyProcessingSta 5000;
BA_ "Version" SG_ 1076 IAU_DigitalKeyProcessingSta "23.02.13";
BA_ "Description" SG_ 1076 IAU_DigitalKeyExit "Digital Key USM setting Exit Condition";
BA_ "GenSigSendType" SG_ 1076 IAU_DigitalKeyExit 4;
BA_ "UserSigValidity" SG_ 1076 IAU_DigitalKeyExit 3;
BA_ "NetworkRequest" SG_ 1076 IAU_DigitalKeyExit 0;
BA_ "NetworkRequestHoldingTime" SG_ 1076 IAU_DigitalKeyExit 5000;
BA_ "Version" SG_ 1076 IAU_DigitalKeyExit "23.07.03";
BA_ "GenSigSendType" SG_ 1076 IAU_DigitalKeyEnblRVal 4;
BA_ "UserSigValidity" SG_ 1076 IAU_DigitalKeyEnblRVal 0;
BA_ "NetworkRequest" SG_ 1076 IAU_DigitalKeyEnblRVal 0;
BA_ "NetworkRequestHoldingTime" SG_ 1076 IAU_DigitalKeyEnblRVal 5000;
BA_ "Version" SG_ 1076 IAU_DigitalKeyEnblRVal "20.05.02";
BA_ "GenSigSendType" SG_ 1076 IAU_OwnerPhnRegRVal 4;
BA_ "UserSigValidity" SG_ 1076 IAU_OwnerPhnRegRVal 0;
BA_ "NetworkRequest" SG_ 1076 IAU_OwnerPhnRegRVal 0;
BA_ "NetworkRequestHoldingTime" SG_ 1076 IAU_OwnerPhnRegRVal 5000;
BA_ "Version" SG_ 1076 IAU_OwnerPhnRegRVal "20.05.02";
BA_ "GenSigSendType" SG_ 1076 IAU_NFCCard1RegRVal 4;
BA_ "UserSigValidity" SG_ 1076 IAU_NFCCard1RegRVal 0;
BA_ "NetworkRequest" SG_ 1076 IAU_NFCCard1RegRVal 0;
BA_ "NetworkRequestHoldingTime" SG_ 1076 IAU_NFCCard1RegRVal 5000;
BA_ "Version" SG_ 1076 IAU_NFCCard1RegRVal "17.12.08";
BA_ "GenSigSendType" SG_ 1076 IAU_NFCCard2RegRVal 4;
BA_ "UserSigValidity" SG_ 1076 IAU_NFCCard2RegRVal 0;
BA_ "NetworkRequest" SG_ 1076 IAU_NFCCard2RegRVal 0;
BA_ "NetworkRequestHoldingTime" SG_ 1076 IAU_NFCCard2RegRVal 5000;
BA_ "Version" SG_ 1076 IAU_NFCCard2RegRVal "17.12.08";
BA_ "Description" SG_ 1076 IAU_DISPWrng "This siganl warning from IAU

- 0x9 (WPCNFC_PreStartAuth_Success) : CLU display when workaround or LPCD Start Auth succeeded (before SSB pressed).";
BA_ "GenSigSendType" SG_ 1076 IAU_DISPWrng 4;
BA_ "UserSigValidity" SG_ 1076 IAU_DISPWrng 0;
BA_ "NetworkRequest" SG_ 1076 IAU_DISPWrng 0;
BA_ "NetworkRequestHoldingTime" SG_ 1076 IAU_DISPWrng 5000;
BA_ "Version" SG_ 1076 IAU_DISPWrng "22.06.04";
BA_ "Description" SG_ 1076 IAU_DigitalKey2Opt "This signal describe Digital Key capability";
BA_ "GenSigSendType" SG_ 1076 IAU_DigitalKey2Opt 4;
BA_ "UserSigValidity" SG_ 1076 IAU_DigitalKey2Opt 0;
BA_REL_ "GenSigTimeoutTime" BU_SG_REL_ WPC SG_ 1076 IAU_DigitalKey2Opt 1500;
BA_REL_ "GenSigTimeoutTime" BU_SG_REL_ WPC2 SG_ 1076 IAU_DigitalKey2Opt 1500;
BA_ "NetworkRequest" SG_ 1076 IAU_DigitalKey2Opt 0;
BA_ "NetworkRequestHoldingTime" SG_ 1076 IAU_DigitalKey2Opt 5000;
BA_ "Version" SG_ 1076 IAU_DigitalKey2Opt "20.08.00";
BA_ "Description" SG_ 1076 IAUwFRULearnState "This signal indicates learning process stste between IAU and FRU";
BA_ "GenSigSendType" SG_ 1076 IAUwFRULearnState 4;
BA_ "UserSigValidity" SG_ 1076 IAUwFRULearnState 0;
BA_ "NetworkRequest" SG_ 1076 IAUwFRULearnState 0;
BA_ "NetworkRequestHoldingTime" SG_ 1076 IAUwFRULearnState 5000;
BA_ "Version" SG_ 1076 IAUwFRULearnState "20.04.05";
BA_ "Description" SG_ 1076 IAUwFPMLearnState "This signal indicates learning process stste between IAU and FPM";
BA_ "GenSigSendType" SG_ 1076 IAUwFPMLearnState 4;
BA_ "UserSigValidity" SG_ 1076 IAUwFPMLearnState 0;
BA_ "NetworkRequest" SG_ 1076 IAUwFPMLearnState 0;
BA_ "NetworkRequestHoldingTime" SG_ 1076 IAUwFPMLearnState 5000;
BA_ "Version" SG_ 1076 IAUwFPMLearnState "20.04.05";
BA_ "GenMsgSendType" BO_ 2281833729 0;
BA_ "GenMsgCycleTimeFast" BO_ 2281833729 0;
BA_ "GenMsgNrOfRepetition" BO_ 2281833729 0;
BA_ "VFrameFormat" BO_ 2281833729 1;
BA_ "Description" SG_ 2281833729 ICSC_Crc2Val "The data area for CRC calculation is based on the data length (DLC) of the message DB.

The CRC shall be calculated over the entire data block (excluding the CRC bytes) including the user data, alive counter and Data ID



- CRC Polynomial (0x1021) , Initial Value : 0xFFFF, XOR value : 0x0000, Data ID : Message ID + 0xF800 

- The initial value is for CRC calculation and the message should be sent with the calculated result value. 

- The mathematical expression to 16 bit CRC polynomial is given here. G(x) = x16 + x12 + x5 + 1



<For CRC calculation of CAN-FD Msg for HS CAN domain ECUs>



- HS-CAN Messages that routed from CAN-FD domain are using 29 bit Extended CAN ID and splitted into 8 Byte Messages.

(from 1 to 4 Msgs, depending on source CAN-FD Msg¡¯s DLC)

- For splitted CAN-FD Msgs¡¯ CRC calculation, HS CAN ECUs should use source CAN-FD Msg¡¯s original STD ID. 

- The original STD ID can be read from Ext ID¡¯s 4~6th Byte.

Eg. STD 0x6AA : EXT SPLT 0x1A8[6AA]01 / 0x1A8[6AA]02 / 0x1A8[6AA]03 / 0x1A8[6AA]04 

(2~4th splitited Msgs can be omitted depending on source CAN-FD Msg¡¯s DLC)

- Aslo, HS-CAN ECUs should use merged data block (from whole splitted Msg) for CRC calculation.";
BA_ "GenSigStartValue" SG_ 2281833729 ICSC_Crc2Val 65535;
BA_ "UserSigValidity" SG_ 2281833729 ICSC_Crc2Val 3;
BA_ "RoutingFactor" SG_ 2281833729 ICSC_Crc2Val 2;
BA_ "Version" SG_ 2281833729 ICSC_Crc2Val "21.09.03";
BA_ "Description" SG_ 2281833729 ICSC_AlvCnt2Val "For the first transmission request for a data element the counter shall be initialized with 0 and shall be incremented by 1 for every subsequent send request. 

When the counter reaches the maximum value(0xFF), then it shall restart with 0 for the next send request";
BA_ "UserSigValidity" SG_ 2281833729 ICSC_AlvCnt2Val 3;
BA_ "RoutingFactor" SG_ 2281833729 ICSC_AlvCnt2Val 2;
BA_ "Version" SG_ 2281833729 ICSC_AlvCnt2Val "21.09.03";
BA_ "Description" SG_ 2281833729 DMIC_DrvModSta "This signal is feedback state of driving mode for Cluster/AVN

This message is for DMIC(Driving Mode Integrated Control)";
BA_ "UserSigValidity" SG_ 2281833729 DMIC_DrvModSta 3;
BA_REL_ "GenSigTimeoutTime" BU_SG_REL_ ALBCU SG_ 2281833729 DMIC_DrvModSta 1500;
BA_REL_ "GenSigTimeoutTime" BU_SG_REL_ ASAU SG_ 2281833729 DMIC_DrvModSta 1500;
BA_REL_ "GenSigTimeoutTime" BU_SG_REL_ DSAU SG_ 2281833729 DMIC_DrvModSta 1500;
BA_REL_ "GenSigTimeoutTime" BU_SG_REL_ GW_APSU SG_ 2281833729 DMIC_DrvModSta 1500;
BA_REL_ "GenSigTimeoutTime" BU_SG_REL_ GW_DLBCU SG_ 2281833729 DMIC_DrvModSta 1500;
BA_ "RoutingFactor" SG_ 2281833729 DMIC_DrvModSta 2;
BA_ "Version" SG_ 2281833729 DMIC_DrvModSta "22.01.00";
BA_ "Description" SG_ 2281833729 DMIC_SmtShftModSta "This signal is a smart shift mode flag.";
BA_ "UserSigValidity" SG_ 2281833729 DMIC_SmtShftModSta 3;
BA_ "RoutingFactor" SG_ 2281833729 DMIC_SmtShftModSta 2;
BA_ "Version" SG_ 2281833729 DMIC_SmtShftModSta "21.10.03";
BA_ "Description" SG_ 2281833729 DMIC_4wdLocking "4wd Locking on/off signal. Bypass SWRC to VCU.";
BA_ "UserSigValidity" SG_ 2281833729 DMIC_4wdLocking 3;
BA_ "RoutingFactor" SG_ 2281833729 DMIC_4wdLocking 2;
BA_ "Version" SG_ 2281833729 DMIC_4wdLocking "22.07.06";
BA_ "Description" SG_ 2281833729 DMIC_EngModSta "This Signal is the request on mode transition for Controlling the Driving Mode.";
BA_ "UserSigValidity" SG_ 2281833729 DMIC_EngModSta 3;
BA_ "RoutingFactor" SG_ 2281833729 DMIC_EngModSta 2;
BA_ "Version" SG_ 2281833729 DMIC_EngModSta "21.10.03";
BA_ "Description" SG_ 2281833729 DMIC_IndEngModSta "This signal is for feedback about individual mode setting on AVN.";
BA_ "UserSigValidity" SG_ 2281833729 DMIC_IndEngModSta 3;
BA_ "RoutingFactor" SG_ 2281833729 DMIC_IndEngModSta 2;
BA_ "Version" SG_ 2281833729 DMIC_IndEngModSta "23.02.11";
BA_ "Description" SG_ 2281833729 DMIC_TmModSta "This Signal is the request on mode transition for Controlling the Driving Mode.";
BA_ "UserSigValidity" SG_ 2281833729 DMIC_TmModSta 3;
BA_ "RoutingFactor" SG_ 2281833729 DMIC_TmModSta 2;
BA_ "Version" SG_ 2281833729 DMIC_TmModSta "21.10.03";
BA_ "Description" SG_ 2281833729 DMIC_IndTmModSta "This signal is for feedback about individual mode setting on AVN.";
BA_ "UserSigValidity" SG_ 2281833729 DMIC_IndTmModSta 3;
BA_ "RoutingFactor" SG_ 2281833729 DMIC_IndTmModSta 2;
BA_ "Version" SG_ 2281833729 DMIC_IndTmModSta "21.10.03";
BA_ "Description" SG_ 2281833729 DMIC_EscModSta "This Signal is the request on mode transition for Controlling the Driving Mode.";
BA_ "UserSigValidity" SG_ 2281833729 DMIC_EscModSta 3;
BA_ "RoutingFactor" SG_ 2281833729 DMIC_EscModSta 2;
BA_ "Version" SG_ 2281833729 DMIC_EscModSta "21.10.03";
BA_ "Description" SG_ 2281833729 DMIC_IndEscModSta "This signal is for feedback about individual mode setting on AVN.";
BA_ "UserSigValidity" SG_ 2281833729 DMIC_IndEscModSta 3;
BA_ "RoutingFactor" SG_ 2281833729 DMIC_IndEscModSta 2;
BA_ "Version" SG_ 2281833729 DMIC_IndEscModSta "21.10.03";
BA_ "Description" SG_ 2281833729 DMIC_MdpsModSta "This Signal is the request on mode transition for Controlling the Driving Mode.";
BA_ "UserSigValidity" SG_ 2281833729 DMIC_MdpsModSta 3;
BA_ "RoutingFactor" SG_ 2281833729 DMIC_MdpsModSta 2;
BA_ "Version" SG_ 2281833729 DMIC_MdpsModSta "22.01.06";
BA_ "Description" SG_ 2281833729 DMIC_IndMdpsModSta "This signal is for feedback about individual mode setting on AVN.";
BA_ "UserSigValidity" SG_ 2281833729 DMIC_IndMdpsModSta 3;
BA_ "RoutingFactor" SG_ 2281833729 DMIC_IndMdpsModSta 2;
BA_ "Version" SG_ 2281833729 DMIC_IndMdpsModSta "22.01.06";
BA_ "GenMsgSendType" BO_ 2281833730 0;
BA_ "GenMsgCycleTimeFast" BO_ 2281833730 0;
BA_ "GenMsgNrOfRepetition" BO_ 2281833730 0;
BA_ "VFrameFormat" BO_ 2281833730 1;
BA_ "Description" SG_ 2281833730 DMIC_EcsModSta "This Signal is the request on mode transition for Controlling the Driving Mode.";
BA_ "UserSigValidity" SG_ 2281833730 DMIC_EcsModSta 3;
BA_ "RoutingFactor" SG_ 2281833730 DMIC_EcsModSta 2;
BA_ "Version" SG_ 2281833730 DMIC_EcsModSta "21.10.03";
BA_ "Description" SG_ 2281833730 DMIC_IndAwdModSta "This signal is for feedback about individual mode setting on AVN.";
BA_ "UserSigValidity" SG_ 2281833730 DMIC_IndAwdModSta 3;
BA_ "RoutingFactor" SG_ 2281833730 DMIC_IndAwdModSta 2;
BA_ "Version" SG_ 2281833730 DMIC_IndAwdModSta "21.10.03";
BA_ "Description" SG_ 2281833730 DMIC_RevModSta "This Signal is the request on mode transition for Controlling the Driving Mode.";
BA_ "UserSigValidity" SG_ 2281833730 DMIC_RevModSta 3;
BA_ "RoutingFactor" SG_ 2281833730 DMIC_RevModSta 2;
BA_ "Version" SG_ 2281833730 DMIC_RevModSta "21.10.03";
BA_ "Description" SG_ 2281833730 DMIC_IndRevModSta "This signal is for feedback about individual mode setting on AVN.";
BA_ "UserSigValidity" SG_ 2281833730 DMIC_IndRevModSta 3;
BA_ "RoutingFactor" SG_ 2281833730 DMIC_IndRevModSta 2;
BA_ "Version" SG_ 2281833730 DMIC_IndRevModSta "21.10.03";
BA_ "Description" SG_ 2281833730 DMIC_PrflModSta "This Signal is the request on mode transition for Controlling the Driving Mode.";
BA_ "UserSigValidity" SG_ 2281833730 DMIC_PrflModSta 3;
BA_ "RoutingFactor" SG_ 2281833730 DMIC_PrflModSta 2;
BA_ "Version" SG_ 2281833730 DMIC_PrflModSta "21.10.03";
BA_ "Description" SG_ 2281833730 DMIC_IndPrflModSta "This signal is for feedback about individual mode setting on AVN.";
BA_ "UserSigValidity" SG_ 2281833730 DMIC_IndPrflModSta 3;
BA_ "RoutingFactor" SG_ 2281833730 DMIC_IndPrflModSta 2;
BA_ "Version" SG_ 2281833730 DMIC_IndPrflModSta "21.10.03";
BA_ "Description" SG_ 2281833730 DMIC_ElsdModSta "This Signal is the request on mode transition for Controlling the Driving Mode.";
BA_ "UserSigValidity" SG_ 2281833730 DMIC_ElsdModSta 3;
BA_ "RoutingFactor" SG_ 2281833730 DMIC_ElsdModSta 2;
BA_ "Version" SG_ 2281833730 DMIC_ElsdModSta "21.10.03";
BA_ "Description" SG_ 2281833730 DMIC_IndElsdModSta "This signal is for feedback about individual mode setting on AVN.";
BA_ "UserSigValidity" SG_ 2281833730 DMIC_IndElsdModSta 3;
BA_ "RoutingFactor" SG_ 2281833730 DMIC_IndElsdModSta 2;
BA_ "Version" SG_ 2281833730 DMIC_IndElsdModSta "21.10.03";
BA_ "Description" SG_ 2281833730 DMIC_IndEcsModSta "This signal is for feedback about individual mode setting on AVN.";
BA_ "UserSigValidity" SG_ 2281833730 DMIC_IndEcsModSta 3;
BA_ "RoutingFactor" SG_ 2281833730 DMIC_IndEcsModSta 2;
BA_ "Version" SG_ 2281833730 DMIC_IndEcsModSta "21.10.03";
BA_ "Description" SG_ 2281833730 DMIC_EsndModSta "This Signal is the request on mode transition for Controlling the Driving Mode.";
BA_ "UserSigValidity" SG_ 2281833730 DMIC_EsndModSta 3;
BA_ "RoutingFactor" SG_ 2281833730 DMIC_EsndModSta 2;
BA_ "Version" SG_ 2281833730 DMIC_EsndModSta "21.10.03";
BA_ "Description" SG_ 2281833730 DMIC_IndEsndModSta "This signal is for feedback about individual mode setting on AVN.";
BA_ "UserSigValidity" SG_ 2281833730 DMIC_IndEsndModSta 3;
BA_ "RoutingFactor" SG_ 2281833730 DMIC_IndEsndModSta 2;
BA_ "Version" SG_ 2281833730 DMIC_IndEsndModSta "21.10.03";
BA_ "Description" SG_ 2281833730 DMIC_RwsModSta "This Signal is the request on mode transition for Controlling the Driving Mode.";
BA_ "UserSigValidity" SG_ 2281833730 DMIC_RwsModSta 3;
BA_ "RoutingFactor" SG_ 2281833730 DMIC_RwsModSta 2;
BA_ "Version" SG_ 2281833730 DMIC_RwsModSta "21.10.03";
BA_ "Description" SG_ 2281833730 DMIC_IndRwsModSta "This signal is for feedback about individual mode setting on AVN.";
BA_ "UserSigValidity" SG_ 2281833730 DMIC_IndRwsModSta 3;
BA_ "RoutingFactor" SG_ 2281833730 DMIC_IndRwsModSta 2;
BA_ "Version" SG_ 2281833730 DMIC_IndRwsModSta "21.10.03";
BA_ "Description" SG_ 2281833730 DMIC_DrvCtrAppSta "VPC control status of Drive/terrain mode

 - 0x0: OFF : CLU control Drive/terrain switch

 - 0x1: ON : VPC control Drive/terrain switch";
BA_ "UserSigValidity" SG_ 2281833730 DMIC_DrvCtrAppSta 3;
BA_ "RoutingFactor" SG_ 2281833730 DMIC_DrvCtrAppSta 2;
BA_ "Version" SG_ 2281833730 DMIC_DrvCtrAppSta "23.10.01";
BA_ "Description" SG_ 2281833730 DMIC_EscOffStaAppTyp "This signal is for the entity that determines the ESC OFF state.

  - Case 1: ESC determines the ESC status based on the ESC Off switch input.

  - Case 2: ESC determines the ESC status according to the DMIC_EscModSta signal transmitted by the VPC (ICSC).";
BA_ "UserSigValidity" SG_ 2281833730 DMIC_EscOffStaAppTyp 3;
BA_ "RoutingFactor" SG_ 2281833730 DMIC_EscOffStaAppTyp 2;
BA_ "Version" SG_ 2281833730 DMIC_EscOffStaAppTyp "23.10.05";
BA_ "Description" SG_ 2281833730 DMIC_AwdModSta "This Signal is the request on mode transition for Controlling the Driving Mode.";
BA_ "UserSigValidity" SG_ 2281833730 DMIC_AwdModSta 3;
BA_ "RoutingFactor" SG_ 2281833730 DMIC_AwdModSta 2;
BA_ "Version" SG_ 2281833730 DMIC_AwdModSta "21.10.03";
BA_ "GenMsgSendType" BO_ 2281833731 0;
BA_ "GenMsgCycleTimeFast" BO_ 2281833731 0;
BA_ "GenMsgNrOfRepetition" BO_ 2281833731 0;
BA_ "VFrameFormat" BO_ 2281833731 1;
BA_ "Description" SG_ 2281833731 DMIC_VcuModSta "This Signal is the request on mode transition for Controlling the Driving Mode.";
BA_ "UserSigValidity" SG_ 2281833731 DMIC_VcuModSta 3;
BA_ "RoutingFactor" SG_ 2281833731 DMIC_VcuModSta 2;
BA_ "Version" SG_ 2281833731 DMIC_VcuModSta "21.10.03";
BA_ "Description" SG_ 2281833731 DMIC_DrvModTyp "This signal indicates drive mode type.";
BA_ "UserSigValidity" SG_ 2281833731 DMIC_DrvModTyp 3;
BA_ "RoutingFactor" SG_ 2281833731 DMIC_DrvModTyp 2;
BA_ "Version" SG_ 2281833731 DMIC_DrvModTyp "19.11.05";
BA_ "Description" SG_ 2281833731 DMIC_EngFltSta "This signal indicates fault status of individual systems.";
BA_ "UserSigValidity" SG_ 2281833731 DMIC_EngFltSta 3;
BA_ "RoutingFactor" SG_ 2281833731 DMIC_EngFltSta 2;
BA_ "Version" SG_ 2281833731 DMIC_EngFltSta "21.10.03";
BA_ "Description" SG_ 2281833731 DMIC_TmFltSta "This signal indicates fault status of individual systems.";
BA_ "UserSigValidity" SG_ 2281833731 DMIC_TmFltSta 3;
BA_ "RoutingFactor" SG_ 2281833731 DMIC_TmFltSta 2;
BA_ "Version" SG_ 2281833731 DMIC_TmFltSta "21.10.03";
BA_ "Description" SG_ 2281833731 DMIC_EscFltSta "This signal indicates fault status of individual systems.";
BA_ "UserSigValidity" SG_ 2281833731 DMIC_EscFltSta 3;
BA_ "RoutingFactor" SG_ 2281833731 DMIC_EscFltSta 2;
BA_ "Version" SG_ 2281833731 DMIC_EscFltSta "21.10.03";
BA_ "Description" SG_ 2281833731 DMIC_MdpsFltSta "This signal indicates fault status of individual systems.";
BA_ "UserSigValidity" SG_ 2281833731 DMIC_MdpsFltSta 3;
BA_ "RoutingFactor" SG_ 2281833731 DMIC_MdpsFltSta 2;
BA_ "Version" SG_ 2281833731 DMIC_MdpsFltSta "21.10.03";
BA_ "Description" SG_ 2281833731 DMIC_EcsFltSta "This signal indicates fault status of individual systems.";
BA_ "UserSigValidity" SG_ 2281833731 DMIC_EcsFltSta 3;
BA_ "RoutingFactor" SG_ 2281833731 DMIC_EcsFltSta 2;
BA_ "Version" SG_ 2281833731 DMIC_EcsFltSta "21.10.03";
BA_ "Description" SG_ 2281833731 DMIC_AwdFltSta "This signal indicates fault status of individual systems.";
BA_ "UserSigValidity" SG_ 2281833731 DMIC_AwdFltSta 3;
BA_ "RoutingFactor" SG_ 2281833731 DMIC_AwdFltSta 2;
BA_ "Version" SG_ 2281833731 DMIC_AwdFltSta "21.10.03";
BA_ "Description" SG_ 2281833731 DMIC_RevFltSta "This signal indicates fault status of individual systems.";
BA_ "UserSigValidity" SG_ 2281833731 DMIC_RevFltSta 3;
BA_ "RoutingFactor" SG_ 2281833731 DMIC_RevFltSta 2;
BA_ "Version" SG_ 2281833731 DMIC_RevFltSta "21.10.03";
BA_ "Description" SG_ 2281833731 DMIC_PrflFltSta "This signal indicates fault status of individual systems.";
BA_ "UserSigValidity" SG_ 2281833731 DMIC_PrflFltSta 3;
BA_ "RoutingFactor" SG_ 2281833731 DMIC_PrflFltSta 2;
BA_ "Version" SG_ 2281833731 DMIC_PrflFltSta "21.10.03";
BA_ "Description" SG_ 2281833731 DMIC_ElsdFltSta "This signal indicates fault status of individual systems.";
BA_ "UserSigValidity" SG_ 2281833731 DMIC_ElsdFltSta 3;
BA_ "RoutingFactor" SG_ 2281833731 DMIC_ElsdFltSta 2;
BA_ "Version" SG_ 2281833731 DMIC_ElsdFltSta "21.10.03";
BA_ "Description" SG_ 2281833731 DMIC_EsndFltSta "This signal indicates fault status of individual systems.";
BA_ "UserSigValidity" SG_ 2281833731 DMIC_EsndFltSta 3;
BA_ "RoutingFactor" SG_ 2281833731 DMIC_EsndFltSta 2;
BA_ "Version" SG_ 2281833731 DMIC_EsndFltSta "21.10.03";
BA_ "Description" SG_ 2281833731 DMIC_RwsFltSta "This signal indicates fault status of individual systems.";
BA_ "UserSigValidity" SG_ 2281833731 DMIC_RwsFltSta 3;
BA_ "RoutingFactor" SG_ 2281833731 DMIC_RwsFltSta 2;
BA_ "Version" SG_ 2281833731 DMIC_RwsFltSta "21.10.03";
BA_ "Description" SG_ 2281833731 DMIC_IndWhlDrvSta "This signal is for feedback about tune-up mode(Wheel Drive type) setting on AVN.";
BA_ "UserSigValidity" SG_ 2281833731 DMIC_IndWhlDrvSta 3;
BA_ "RoutingFactor" SG_ 2281833731 DMIC_IndWhlDrvSta 2;
BA_ "Version" SG_ 2281833731 DMIC_IndWhlDrvSta "22.01.06";
BA_ "Description" SG_ 2281833731 DMIC_IndVcuModSta "This signal is for feedback about individual mode setting on AVN.";
BA_ "UserSigValidity" SG_ 2281833731 DMIC_IndVcuModSta 3;
BA_ "RoutingFactor" SG_ 2281833731 DMIC_IndVcuModSta 2;
BA_ "Version" SG_ 2281833731 DMIC_IndVcuModSta "21.10.03";
BA_ "Description" SG_ 2281833731 DMIC_VcuFltSta "This signal indicates fault status of individual systems.";
BA_ "UserSigValidity" SG_ 2281833731 DMIC_VcuFltSta 3;
BA_ "RoutingFactor" SG_ 2281833731 DMIC_VcuFltSta 2;
BA_ "Version" SG_ 2281833731 DMIC_VcuFltSta "21.10.03";
BA_ "Description" SG_ 2281833731 DMIC_IndMtrPwrSta "This signal is for feedback about tune-up mode(Motor Power) setting on AVN.";
BA_ "UserSigValidity" SG_ 2281833731 DMIC_IndMtrPwrSta 3;
BA_ "RoutingFactor" SG_ 2281833731 DMIC_IndMtrPwrSta 2;
BA_ "Version" SG_ 2281833731 DMIC_IndMtrPwrSta "22.01.06";
BA_ "Description" SG_ 2281833731 DMIC_IndAccSenSta "This signal is for feedback about tune-up mode(Acceleration sensitivity) setting on AVN.";
BA_ "UserSigValidity" SG_ 2281833731 DMIC_IndAccSenSta 3;
BA_ "RoutingFactor" SG_ 2281833731 DMIC_IndAccSenSta 2;
BA_ "Version" SG_ 2281833731 DMIC_IndAccSenSta "22.01.06";
BA_ "Description" SG_ 2281833731 DMIC_TerrainModSwSta "This signal occurs when terrain mode switch is selected either 'Snow' or 'Sand' or 'Mud' or 'Auto', 'Deep Snow', 'Rock'";
BA_ "UserSigValidity" SG_ 2281833731 DMIC_TerrainModSwSta 3;
BA_ "RoutingFactor" SG_ 2281833731 DMIC_TerrainModSwSta 2;
BA_ "Version" SG_ 2281833731 DMIC_TerrainModSwSta "23.10.01";
BA_ "Description" SG_ 2281833731 DMIC_TerrainMainSwSta "This signal represents the terrain mode main switch's state.

0x1:On-Road /0x2:Off-Road";
BA_ "UserSigValidity" SG_ 2281833731 DMIC_TerrainMainSwSta 3;
BA_ "RoutingFactor" SG_ 2281833731 DMIC_TerrainMainSwSta 2;
BA_ "Version" SG_ 2281833731 DMIC_TerrainMainSwSta "23.10.01";
BA_ "Description" SG_ 2281833731 DMIC_DrvModTypSta "This signal indicates whether drive mode type is old way or new way.

  - (old) Type using 2 signals : DMIC_DrvModTyp, DMIC_DrvMod2Typ

  - (new) Type using new signals : DMIC_ENG_AppliedSta, DMIC_MDPS_AppliedSta, DMIC_ECS_AppliedSta, etc";
BA_ "UserSigValidity" SG_ 2281833731 DMIC_DrvModTypSta 3;
BA_ "RoutingFactor" SG_ 2281833731 DMIC_DrvModTypSta 2;
BA_ "Version" SG_ 2281833731 DMIC_DrvModTypSta "23.04.03";
BA_ "Description" SG_ 2281833731 DMIC_DrvngModSwSta "This signal occurs when drive mode switch is selected either 'Normal' or 'Eco' or 'Sport' or 'Sport+' or 'Smart' or 'Custom' or 'N-mode'.";
BA_ "UserSigValidity" SG_ 2281833731 DMIC_DrvngModSwSta 3;
BA_ "RoutingFactor" SG_ 2281833731 DMIC_DrvngModSwSta 2;
BA_ "Version" SG_ 2281833731 DMIC_DrvngModSwSta "23.10.01";
BA_ "Description" SG_ 2281833731 DMIC_DrvMod2Typ "This signal indicates drive mode type.";
BA_ "UserSigValidity" SG_ 2281833731 DMIC_DrvMod2Typ 3;
BA_ "RoutingFactor" SG_ 2281833731 DMIC_DrvMod2Typ 2;
BA_ "Version" SG_ 2281833731 DMIC_DrvMod2Typ "20.04.04";
BA_ "Description" SG_ 2281833731 DMIC_DrvModFltSta "This signal is for Driving mode fault status. From this signal, AVN can deactivate any driving in mode selection menu.";
BA_ "UserSigValidity" SG_ 2281833731 DMIC_DrvModFltSta 3;
BA_ "RoutingFactor" SG_ 2281833731 DMIC_DrvModFltSta 2;
BA_ "Version" SG_ 2281833731 DMIC_DrvModFltSta "21.10.03";
BA_ "GenMsgSendType" BO_ 1059 0;
BA_ "Description" SG_ 1059 PSU_DiagSta "(Old)C_PSU_DiagState";
BA_ "GenSigSendType" SG_ 1059 PSU_DiagSta 4;
BA_ "UserSigValidity" SG_ 1059 PSU_DiagSta 0;
BA_ "NetworkRequest" SG_ 1059 PSU_DiagSta 0;
BA_ "NetworkRequestHoldingTime" SG_ 1059 PSU_DiagSta 5000;
BA_ "Version" SG_ 1059 PSU_DiagSta "21.07.06";
BA_ "Description" SG_ 1059 Ast_2ndAutoRlxEnable "µ¿½Â¼® ½ÃÆ® À§Ä¡¿¡ µû¸¥ 2¿­ ¸±·º¼Ç µ¿ÀÛ °¡´É¿©ºÎ ÆÇ´Ü ½ÅÈ£";
BA_ "GenSigSendType" SG_ 1059 Ast_2ndAutoRlxEnable 4;
BA_ "UserSigValidity" SG_ 1059 Ast_2ndAutoRlxEnable 0;
BA_REL_ "GenSigTimeoutTime" BU_SG_REL_ GW_RLPSU SG_ 1059 Ast_2ndAutoRlxEnable 1500;
BA_REL_ "GenSigTimeoutTime" BU_SG_REL_ GW_RRPSU SG_ 1059 Ast_2ndAutoRlxEnable 1500;
BA_ "NetworkRequest" SG_ 1059 Ast_2ndAutoRlxEnable 0;
BA_ "NetworkRequestHoldingTime" SG_ 1059 Ast_2ndAutoRlxEnable 5000;
BA_ "Version" SG_ 1059 Ast_2ndAutoRlxEnable "21.06.10";
BA_ "Description" SG_ 1059 Ast_AutoRlxSta "µ¿½Â¼® ½ÃÆ® ¿ÀÅä ¸±·º¼Ç µ¿ÀÛ »óÅÂ Á¤º¸";
BA_ "GenSigSendType" SG_ 1059 Ast_AutoRlxSta 4;
BA_ "UserSigValidity" SG_ 1059 Ast_AutoRlxSta 0;
BA_REL_ "GenSigTimeoutTime" BU_SG_REL_ GW_RLPSU SG_ 1059 Ast_AutoRlxSta 1500;
BA_REL_ "GenSigTimeoutTime" BU_SG_REL_ GW_RRPSU SG_ 1059 Ast_AutoRlxSta 1500;
BA_ "NetworkRequest" SG_ 1059 Ast_AutoRlxSta 0;
BA_ "NetworkRequestHoldingTime" SG_ 1059 Ast_AutoRlxSta 5000;
BA_ "Version" SG_ 1059 Ast_AutoRlxSta "21.07.06";
BA_ "Description" SG_ 1059 Ast_2ndAutoFldEnable "1¿­ µ¿½Â¼® À§Ä¡¿¡ µû¸¥ 2¿­ ½ÃÆ® Æúµù µ¿ÀÛ °¡´É ¿©ºÎ ÆÇ´Ü Á¶°Ç";
BA_ "GenSigSendType" SG_ 1059 Ast_2ndAutoFldEnable 4;
BA_ "UserSigValidity" SG_ 1059 Ast_2ndAutoFldEnable 0;
BA_REL_ "GenSigTimeoutTime" BU_SG_REL_ GW_RLPSU SG_ 1059 Ast_2ndAutoFldEnable 1500;
BA_REL_ "GenSigTimeoutTime" BU_SG_REL_ GW_RRPSU SG_ 1059 Ast_2ndAutoFldEnable 1500;
BA_ "NetworkRequest" SG_ 1059 Ast_2ndAutoFldEnable 0;
BA_ "NetworkRequestHoldingTime" SG_ 1059 Ast_2ndAutoFldEnable 5000;
BA_ "Version" SG_ 1059 Ast_2ndAutoFldEnable "22.05.02";
BA_ "Description" SG_ 1059 PSU_EsyAcsGetOnSta "Easy Access Get On Information";
BA_ "GenSigSendType" SG_ 1059 PSU_EsyAcsGetOnSta 4;
BA_ "UserSigValidity" SG_ 1059 PSU_EsyAcsGetOnSta 0;
BA_REL_ "GenSigTimeoutTime" BU_SG_REL_ SLB SG_ 1059 PSU_EsyAcsGetOnSta 1500;
BA_ "NetworkRequest" SG_ 1059 PSU_EsyAcsGetOnSta 0;
BA_ "NetworkRequestHoldingTime" SG_ 1059 PSU_EsyAcsGetOnSta 5000;
BA_ "Version" SG_ 1059 PSU_EsyAcsGetOnSta "21.07.06";
BA_ "Description" SG_ 1059 PSU_EsyAcsGetOffSta "Easy Access Get Off Information";
BA_ "GenSigSendType" SG_ 1059 PSU_EsyAcsGetOffSta 4;
BA_ "UserSigValidity" SG_ 1059 PSU_EsyAcsGetOffSta 0;
BA_REL_ "GenSigTimeoutTime" BU_SG_REL_ SLB SG_ 1059 PSU_EsyAcsGetOffSta 1500;
BA_ "NetworkRequest" SG_ 1059 PSU_EsyAcsGetOffSta 0;
BA_ "NetworkRequestHoldingTime" SG_ 1059 PSU_EsyAcsGetOffSta 5000;
BA_ "Version" SG_ 1059 PSU_EsyAcsGetOffSta "21.07.06";
BA_ "Description" SG_ 1059 PSU_EsyAcsStpSta "Easy Access Stop Information";
BA_ "GenSigSendType" SG_ 1059 PSU_EsyAcsStpSta 4;
BA_ "UserSigValidity" SG_ 1059 PSU_EsyAcsStpSta 0;
BA_REL_ "GenSigTimeoutTime" BU_SG_REL_ SLB SG_ 1059 PSU_EsyAcsStpSta 1500;
BA_ "NetworkRequest" SG_ 1059 PSU_EsyAcsStpSta 0;
BA_ "NetworkRequestHoldingTime" SG_ 1059 PSU_EsyAcsStpSta 5000;
BA_ "Version" SG_ 1059 PSU_EsyAcsStpSta "21.07.06";
BA_ "GenSigSendType" SG_ 1059 PSU_RVal 4;
BA_ "UserSigValidity" SG_ 1059 PSU_RVal 0;
BA_ "NetworkRequest" SG_ 1059 PSU_RVal 0;
BA_ "NetworkRequestHoldingTime" SG_ 1059 PSU_RVal 5000;
BA_ "Version" SG_ 1059 PSU_RVal "21.07.06";
BA_ "GenMsgSendType" BO_ 1086 0;
BA_ "Description" SG_ 1086 RL_CURTAIN_POSITION "2¿­ ÁÂÃø À©µµ¿ì ±Û¶ó½º Ä¿Æ° À§Ä¡ Á¤º¸";
BA_ "GenSigSendType" SG_ 1086 RL_CURTAIN_POSITION 4;
BA_ "UserSigValidity" SG_ 1086 RL_CURTAIN_POSITION 0;
BA_REL_ "GenSigTimeoutTime" BU_SG_REL_ ATS SG_ 1086 RL_CURTAIN_POSITION 1500;
BA_ "NetworkRequest" SG_ 1086 RL_CURTAIN_POSITION 0;
BA_ "NetworkRequestHoldingTime" SG_ 1086 RL_CURTAIN_POSITION 5000;
BA_ "Version" SG_ 1086 RL_CURTAIN_POSITION "18.03.07";
BA_ "Description" SG_ 1086 RDC_SWVerMinor1 "Indicate the RDC software version as follows:

- The software version is displayed in three digits.

- The Major and Minor digits are separated by '.'

- Signal values are transmitted to ASCII codes.



¡Ø Example

RDC_SWVerMajor1 : 0x41 (HEX) -> ASCII CODE : 'A' 

RDC_SWVerMinor1 : 0x30 (HEX) -> ASCII CODE : '0'

RDC_SWVerMinor2 : 0x33 (HEX) -> ASCII CODE : '3'

=> RDC S/W Ver is displayed 'A.03'";
BA_ "GenSigSendType" SG_ 1086 RDC_SWVerMinor1 4;
BA_ "UserSigValidity" SG_ 1086 RDC_SWVerMinor1 0;
BA_ "Version" SG_ 1086 RDC_SWVerMinor1 "18.10.06";
BA_ "Description" SG_ 1086 RDC_SWVerMinor2 "Indicate the RDC software version as follows:

- The software version is displayed in three digits.

- The Major and Minor digits are separated by '.'

- Signal values are transmitted to ASCII codes.



¡Ø Example

RDC_SWVerMajor1 : 0x41 (HEX) -> ASCII CODE : 'A' 

RDC_SWVerMinor1 : 0x30 (HEX) -> ASCII CODE : '0'

RDC_SWVerMinor2 : 0x33 (HEX) -> ASCII CODE : '3'

=> RDC S/W Ver is displayed 'A.03'";
BA_ "GenSigSendType" SG_ 1086 RDC_SWVerMinor2 4;
BA_ "UserSigValidity" SG_ 1086 RDC_SWVerMinor2 0;
BA_ "Version" SG_ 1086 RDC_SWVerMinor2 "18.10.06";
BA_ "Description" SG_ 1086 RR_CURTAIN_POSITION "2¿­ ¿ìÃø À©µµ¿ì ±Û¶ó½º Ä¿Æ° À§Ä¡ Á¤º¸";
BA_ "GenSigSendType" SG_ 1086 RR_CURTAIN_POSITION 4;
BA_ "UserSigValidity" SG_ 1086 RR_CURTAIN_POSITION 0;
BA_REL_ "GenSigTimeoutTime" BU_SG_REL_ ATS SG_ 1086 RR_CURTAIN_POSITION 1500;
BA_ "NetworkRequest" SG_ 1086 RR_CURTAIN_POSITION 0;
BA_ "NetworkRequestHoldingTime" SG_ 1086 RR_CURTAIN_POSITION 5000;
BA_ "Version" SG_ 1086 RR_CURTAIN_POSITION "18.03.07";
BA_ "Description" SG_ 1086 RDC_RLDNInitFlag "Rear Left Door Curtain Down Initialized Finish Flag";
BA_ "GenSigSendType" SG_ 1086 RDC_RLDNInitFlag 4;
BA_ "UserSigValidity" SG_ 1086 RDC_RLDNInitFlag 0;
BA_ "NetworkRequest" SG_ 1086 RDC_RLDNInitFlag 0;
BA_ "NetworkRequestHoldingTime" SG_ 1086 RDC_RLDNInitFlag 5000;
BA_ "Version" SG_ 1086 RDC_RLDNInitFlag "21.01.08";
BA_ "Description" SG_ 1086 RDC_RRDNInitFlag "Rear Right Door Curtain Down Initialized Finish Flag";
BA_ "GenSigSendType" SG_ 1086 RDC_RRDNInitFlag 4;
BA_ "UserSigValidity" SG_ 1086 RDC_RRDNInitFlag 0;
BA_ "NetworkRequest" SG_ 1086 RDC_RRDNInitFlag 0;
BA_ "NetworkRequestHoldingTime" SG_ 1086 RDC_RRDNInitFlag 5000;
BA_ "Version" SG_ 1086 RDC_RRDNInitFlag "21.01.08";
BA_ "Description" SG_ 1086 RDC_RLOpState "Rear Left Door Curtain Operating State Feedback";
BA_ "GenSigSendType" SG_ 1086 RDC_RLOpState 4;
BA_ "UserSigValidity" SG_ 1086 RDC_RLOpState 0;
BA_ "NetworkRequest" SG_ 1086 RDC_RLOpState 0;
BA_ "NetworkRequestHoldingTime" SG_ 1086 RDC_RLOpState 5000;
BA_ "Version" SG_ 1086 RDC_RLOpState "21.01.08";
BA_ "Description" SG_ 1086 RDC_RROpState "Rear Right Door Curtain Operating State Feedback";
BA_ "GenSigSendType" SG_ 1086 RDC_RROpState 4;
BA_ "UserSigValidity" SG_ 1086 RDC_RROpState 0;
BA_ "NetworkRequest" SG_ 1086 RDC_RROpState 0;
BA_ "NetworkRequestHoldingTime" SG_ 1086 RDC_RROpState 5000;
BA_ "Version" SG_ 1086 RDC_RROpState "21.01.08";
BA_ "Description" SG_ 1086 RDC_OptTyp "RDC OPTION SIGNAL";
BA_ "GenSigSendType" SG_ 1086 RDC_OptTyp 4;
BA_ "UserSigValidity" SG_ 1086 RDC_OptTyp 0;
BA_REL_ "GenSigTimeoutTime" BU_SG_REL_ ATS SG_ 1086 RDC_OptTyp 1500;
BA_ "NetworkRequest" SG_ 1086 RDC_OptTyp 0;
BA_ "NetworkRequestHoldingTime" SG_ 1086 RDC_OptTyp 5000;
BA_ "Version" SG_ 1086 RDC_OptTyp "20.01.01";
BA_ "Description" SG_ 1086 RDC_SWVerMajor1 "Indicate the RDC software version as follows:

- The software version is displayed in three digits.

- The Major and Minor digits are separated by '.'

- Signal values are transmitted to ASCII codes.



¡Ø Example

RDC_SWVerMajor1 : 0x41 (HEX) -> ASCII CODE : 'A' 

RDC_SWVerMinor1 : 0x30 (HEX) -> ASCII CODE : '0'

RDC_SWVerMinor2 : 0x33 (HEX) -> ASCII CODE : '3'

=> RDC S/W Ver is displayed 'A.03'";
BA_ "GenSigSendType" SG_ 1086 RDC_SWVerMajor1 4;
BA_ "UserSigValidity" SG_ 1086 RDC_SWVerMajor1 0;
BA_ "Version" SG_ 1086 RDC_SWVerMajor1 "21.07.00";
BA_ "GenMsgSendType" BO_ 1068 0;
BA_ "Description" SG_ 1068 RLPSU_ReclMtrPos "2¿­ LH ½ÃÆ® Recline ¸ðÅÍ À§Ä¡°ª ¼Û½Å

 - Seat Recline Position Information signal for 2nd LH seat";
BA_ "GenSigSendType" SG_ 1068 RLPSU_ReclMtrPos 4;
BA_ "UserSigValidity" SG_ 1068 RLPSU_ReclMtrPos 0;
BA_REL_ "GenSigTimeoutTime" BU_SG_REL_ PFSU SG_ 1068 RLPSU_ReclMtrPos 1500;
BA_ "NetworkRequest" SG_ 1068 RLPSU_ReclMtrPos 0;
BA_ "NetworkRequestHoldingTime" SG_ 1068 RLPSU_ReclMtrPos 5000;
BA_ "Version" SG_ 1068 RLPSU_ReclMtrPos "21.07.06";
BA_ "Description" SG_ 1068 RLPSU_RLSlidPos "2nd Left Seat Slide Position Information for button activatation / unactivation";
BA_ "GenSigSendType" SG_ 1068 RLPSU_RLSlidPos 4;
BA_ "UserSigValidity" SG_ 1068 RLPSU_RLSlidPos 0;
BA_REL_ "GenSigTimeoutTime" BU_SG_REL_ CGW_CCU SG_ 1068 RLPSU_RLSlidPos 1500;
BA_ "Version" SG_ 1068 RLPSU_RLSlidPos "21.07.06";
BA_ "Description" SG_ 1068 RLPSU_RLRclPos "2¿­ ÁÂÃø ½ÃÆ® ¹é ¸®Å¬¶óÀÌ´× À§Ä¡¿¡ µû¸¥ ¹öÆ° È°¼ºÈ­ / ºñÈ°¼ºÈ­";
BA_ "GenSigSendType" SG_ 1068 RLPSU_RLRclPos 4;
BA_ "UserSigValidity" SG_ 1068 RLPSU_RLRclPos 0;
BA_REL_ "GenSigTimeoutTime" BU_SG_REL_ CGW_CCU SG_ 1068 RLPSU_RLRclPos 1500;
BA_ "Version" SG_ 1068 RLPSU_RLRclPos "21.07.06";
BA_ "Description" SG_ 1068 RLPSU_RLTiltPos "2¿­ ÁÂÃø ½ÃÆ® Äí¼Ç Æ¿Æ® À§Ä¡¿¡ µû¸¥ ¹öÆ° È°¼ºÈ­ / ºñÈ°¼ºÈ­";
BA_ "GenSigSendType" SG_ 1068 RLPSU_RLTiltPos 4;
BA_ "UserSigValidity" SG_ 1068 RLPSU_RLTiltPos 0;
BA_REL_ "GenSigTimeoutTime" BU_SG_REL_ CGW_CCU SG_ 1068 RLPSU_RLTiltPos 1500;
BA_ "Version" SG_ 1068 RLPSU_RLTiltPos "21.07.06";
BA_ "Description" SG_ 1068 RLPSU_RLLegExtPos "2¿­ ÁÂÃø ½ÃÆ® ·¹±×·¹½ºÆ® ÀÍ½ºÅÙ¼Ç À§Ä¡¿¡ µû¸¥ ¹öÆ° È°¼ºÈ­ / ºñÈ°¼ºÈ­";
BA_ "GenSigSendType" SG_ 1068 RLPSU_RLLegExtPos 4;
BA_ "UserSigValidity" SG_ 1068 RLPSU_RLLegExtPos 0;
BA_REL_ "GenSigTimeoutTime" BU_SG_REL_ CGW_CCU SG_ 1068 RLPSU_RLLegExtPos 1500;
BA_ "Version" SG_ 1068 RLPSU_RLLegExtPos "21.07.06";
BA_ "Description" SG_ 1068 RLPSU_RLLegSupPos "2¿­ ÁÂÃø ½ÃÆ® ·¹±×¼­Æ÷Æ® À§Ä¡¿¡ µû¸¥ ¹öÆ° È°¼ºÈ­ / ºñÈ°¼ºÈ­";
BA_ "GenSigSendType" SG_ 1068 RLPSU_RLLegSupPos 4;
BA_ "UserSigValidity" SG_ 1068 RLPSU_RLLegSupPos 0;
BA_REL_ "GenSigTimeoutTime" BU_SG_REL_ CGW_CCU SG_ 1068 RLPSU_RLLegSupPos 1500;
BA_ "Version" SG_ 1068 RLPSU_RLLegSupPos "21.07.06";
BA_ "Description" SG_ 1068 RLPSU_RLHrestSlidPos "2nd Left Seat Head Rest Slide Position Information for button activatation / unactivation";
BA_ "GenSigSendType" SG_ 1068 RLPSU_RLHrestSlidPos 4;
BA_ "UserSigValidity" SG_ 1068 RLPSU_RLHrestSlidPos 0;
BA_REL_ "GenSigTimeoutTime" BU_SG_REL_ CGW_CCU SG_ 1068 RLPSU_RLHrestSlidPos 1500;
BA_ "Version" SG_ 1068 RLPSU_RLHrestSlidPos "21.07.06";
BA_ "Description" SG_ 1068 RLPSU_RLHrestHeightPos "2¿­ ÁÂÃø ½ÃÆ® Çìµå·¹½ºÆ® ÇÏÀÌÆ® À§Ä¡¿¡ µû¸¥ ¹öÆ° È°¼ºÈ­ / ºñÈ°¼ºÈ­";
BA_ "GenSigSendType" SG_ 1068 RLPSU_RLHrestHeightPos 4;
BA_ "UserSigValidity" SG_ 1068 RLPSU_RLHrestHeightPos 0;
BA_REL_ "GenSigTimeoutTime" BU_SG_REL_ CGW_CCU SG_ 1068 RLPSU_RLHrestHeightPos 1500;
BA_ "Version" SG_ 1068 RLPSU_RLHrestHeightPos "21.07.06";
BA_ "Description" SG_ 1068 RLPSU_Opt "PWR_HVU Option";
BA_ "GenSigSendType" SG_ 1068 RLPSU_Opt 4;
BA_ "UserSigValidity" SG_ 1068 RLPSU_Opt 0;
BA_REL_ "GenSigTimeoutTime" BU_SG_REL_ CGW_CCU SG_ 1068 RLPSU_Opt 1500;
BA_ "Version" SG_ 1068 RLPSU_Opt "19.03.05";
BA_ "Description" SG_ 1068 RLPSU_Opt_Captain "PWR_HVU Option_Captain";
BA_ "GenSigSendType" SG_ 1068 RLPSU_Opt_Captain 4;
BA_ "UserSigValidity" SG_ 1068 RLPSU_Opt_Captain 0;
BA_REL_ "GenSigTimeoutTime" BU_SG_REL_ CGW_CCU SG_ 1068 RLPSU_Opt_Captain 1500;
BA_ "Version" SG_ 1068 RLPSU_Opt_Captain "20.10.02";
BA_ "Description" SG_ 1068 RL_AutoRlxSta "ÈÄ¼® LH ½ÃÆ® ¿ÀÅä ¸±·º¼Ç µ¿ÀÛ »óÅÂ Á¤º¸";
BA_ "GenSigSendType" SG_ 1068 RL_AutoRlxSta 4;
BA_ "UserSigValidity" SG_ 1068 RL_AutoRlxSta 0;
BA_REL_ "GenSigTimeoutTime" BU_SG_REL_ GW_APSU SG_ 1068 RL_AutoRlxSta 1500;
BA_REL_ "GenSigTimeoutTime" BU_SG_REL_ GW_DPSU SG_ 1068 RL_AutoRlxSta 1500;
BA_REL_ "GenSigTimeoutTime" BU_SG_REL_ PFSU SG_ 1068 RL_AutoRlxSta 1500;
BA_ "NetworkRequest" SG_ 1068 RL_AutoRlxSta 0;
BA_ "NetworkRequestHoldingTime" SG_ 1068 RL_AutoRlxSta 5000;
BA_ "Version" SG_ 1068 RL_AutoRlxSta "21.07.06";
BA_ "Description" SG_ 1068 RL_FLStAutoRlxEnable "ÈÄ¼® LH ½ÃÆ® À§Ä¡¿¡ µû¸¥ Àü¼® LH ¿ÀÅä ¸±·º¼Ç µ¿ÀÛ ÆÇ´Ü";
BA_ "GenSigSendType" SG_ 1068 RL_FLStAutoRlxEnable 4;
BA_ "UserSigValidity" SG_ 1068 RL_FLStAutoRlxEnable 0;
BA_REL_ "GenSigTimeoutTime" BU_SG_REL_ GW_APSU SG_ 1068 RL_FLStAutoRlxEnable 1500;
BA_REL_ "GenSigTimeoutTime" BU_SG_REL_ GW_DPSU SG_ 1068 RL_FLStAutoRlxEnable 1500;
BA_ "NetworkRequest" SG_ 1068 RL_FLStAutoRlxEnable 0;
BA_ "NetworkRequestHoldingTime" SG_ 1068 RL_FLStAutoRlxEnable 5000;
BA_ "Version" SG_ 1068 RL_FLStAutoRlxEnable "21.06.10";
BA_ "Description" SG_ 1068 RLHVU_Opt_Captain "MNL_HVU Option_Captain";
BA_ "GenSigSendType" SG_ 1068 RLHVU_Opt_Captain 4;
BA_ "UserSigValidity" SG_ 1068 RLHVU_Opt_Captain 0;
BA_REL_ "GenSigTimeoutTime" BU_SG_REL_ CGW_CCU SG_ 1068 RLHVU_Opt_Captain 1500;
BA_ "Version" SG_ 1068 RLHVU_Opt_Captain "21.07.06";
BA_ "Description" SG_ 1068 RL_TLAutoFldEnable "2¿­ RLÃø ½ÃÆ® À§Ä¡ Á¤º¸¿¡ µû¸¥ 3¿­ TLÃø Æúµù/¾ðÆúµù µ¿ÀÛ °¡´É ¿©ºÎ ÆÇ´Ü Á¶°Ç";
BA_ "GenSigSendType" SG_ 1068 RL_TLAutoFldEnable 4;
BA_ "UserSigValidity" SG_ 1068 RL_TLAutoFldEnable 0;
BA_REL_ "GenSigTimeoutTime" BU_SG_REL_ PFSU SG_ 1068 RL_TLAutoFldEnable 1500;
BA_ "NetworkRequest" SG_ 1068 RL_TLAutoFldEnable 0;
BA_ "NetworkRequestHoldingTime" SG_ 1068 RL_TLAutoFldEnable 5000;
BA_ "Version" SG_ 1068 RL_TLAutoFldEnable "22.05.02";
BA_ "Description" SG_ 1068 RL_AutoFoldSta "2¿­ RLÃø Æúµù/¾ðÆúµù µ¿ÀÛ »óÅÂ¿¡ µû¸¥ 1¿­ ½ÃÆ® ¸±·º¼Ç µ¿ÀÛ °¡´É ¿©ºÎ ÆÇ´Ü Á¶°Ç";
BA_ "GenSigSendType" SG_ 1068 RL_AutoFoldSta 4;
BA_ "UserSigValidity" SG_ 1068 RL_AutoFoldSta 0;
BA_REL_ "GenSigTimeoutTime" BU_SG_REL_ GW_APSU SG_ 1068 RL_AutoFoldSta 1500;
BA_REL_ "GenSigTimeoutTime" BU_SG_REL_ GW_DPSU SG_ 1068 RL_AutoFoldSta 1500;
BA_ "NetworkRequest" SG_ 1068 RL_AutoFoldSta 0;
BA_ "NetworkRequestHoldingTime" SG_ 1068 RL_AutoFoldSta 5000;
BA_ "Version" SG_ 1068 RL_AutoFoldSta "22.05.02";
BA_ "Description" SG_ 1068 RL_AutoWalkInSta "2¿­ RLÃø ¿öÅ©ÀÎ µ¿ÀÛ »óÅÂ¿¡ µû¸¥ 1¿­ ½ÃÆ® ¸±·º¼Ç µ¿ÀÛ °¡´É ¿©ºÎ ÆÇ´Ü Á¶°Ç";
BA_ "GenSigSendType" SG_ 1068 RL_AutoWalkInSta 4;
BA_ "UserSigValidity" SG_ 1068 RL_AutoWalkInSta 0;
BA_REL_ "GenSigTimeoutTime" BU_SG_REL_ GW_APSU SG_ 1068 RL_AutoWalkInSta 1500;
BA_REL_ "GenSigTimeoutTime" BU_SG_REL_ GW_DPSU SG_ 1068 RL_AutoWalkInSta 1500;
BA_ "NetworkRequest" SG_ 1068 RL_AutoWalkInSta 0;
BA_ "NetworkRequestHoldingTime" SG_ 1068 RL_AutoWalkInSta 5000;
BA_ "Version" SG_ 1068 RL_AutoWalkInSta "22.05.02";
BA_ "Description" SG_ 1068 RLPSU_PwrSeatOpt "2¿­ ÁÂÃø ¸®Å¬¶óÀÌ³Ê ½ÃÆ® ¿É¼Ç Á¤º¸";
BA_ "GenSigSendType" SG_ 1068 RLPSU_PwrSeatOpt 4;
BA_ "UserSigValidity" SG_ 1068 RLPSU_PwrSeatOpt 0;
BA_REL_ "GenSigTimeoutTime" BU_SG_REL_ CGW_CCU SG_ 1068 RLPSU_PwrSeatOpt 1500;
BA_ "Version" SG_ 1068 RLPSU_PwrSeatOpt "19.08.05";
BA_ "Description" SG_ 1068 RLPSU_PwrSeatPos "2¿­ ÁÂÃø ½ÃÆ® ¹é À§Ä¡¿¡ µû¸¥ ¹öÆ° È°¼ºÈ­ / ºñÈ°¼ºÈ­";
BA_ "GenSigSendType" SG_ 1068 RLPSU_PwrSeatPos 4;
BA_ "UserSigValidity" SG_ 1068 RLPSU_PwrSeatPos 0;
BA_REL_ "GenSigTimeoutTime" BU_SG_REL_ CGW_CCU SG_ 1068 RLPSU_PwrSeatPos 1500;
BA_ "Version" SG_ 1068 RLPSU_PwrSeatPos "21.07.06";
BA_ "GenMsgSendType" BO_ 1080 0;
BA_ "Description" SG_ 1080 RL_SHVU_SeatOptSta "ÈÄ¼® LH ½ÃÆ®¿¡ Àû¿ëµÈ È÷ÅÍ/ÅëÇ³ ¿É¼Ç »ç¾ç";
BA_ "GenSigSendType" SG_ 1080 RL_SHVU_SeatOptSta 4;
BA_ "UserSigValidity" SG_ 1080 RL_SHVU_SeatOptSta 7;
BA_REL_ "GenSigTimeoutTime" BU_SG_REL_ ATS SG_ 1080 RL_SHVU_SeatOptSta 1500;
BA_REL_ "GenSigTimeoutTime" BU_SG_REL_ CGW_CCU SG_ 1080 RL_SHVU_SeatOptSta 1500;
BA_ "NetworkRequest" SG_ 1080 RL_SHVU_SeatOptSta 0;
BA_ "NetworkRequestHoldingTime" SG_ 1080 RL_SHVU_SeatOptSta 5000;
BA_ "Version" SG_ 1080 RL_SHVU_SeatOptSta "22.05.04";
BA_ "Description" SG_ 1080 RL_SHVU_SeatHtOperSta "ÈÄ¼® LH ½ÃÆ® ÇöÀç ÀÛµ¿ ÁßÀÎ È÷ÅÍ/ÅëÇ³ ´Ü¼ö »óÅÂ";
BA_ "GenSigSendType" SG_ 1080 RL_SHVU_SeatHtOperSta 4;
BA_ "UserSigValidity" SG_ 1080 RL_SHVU_SeatHtOperSta 7;
BA_REL_ "GenSigTimeoutTime" BU_SG_REL_ ATS SG_ 1080 RL_SHVU_SeatHtOperSta 1500;
BA_REL_ "GenSigTimeoutTime" BU_SG_REL_ CGW_CCU SG_ 1080 RL_SHVU_SeatHtOperSta 1500;
BA_REL_ "GenSigTimeoutTime" BU_SG_REL_ FCS SG_ 1080 RL_SHVU_SeatHtOperSta 1500;
BA_ "NetworkRequest" SG_ 1080 RL_SHVU_SeatHtOperSta 0;
BA_ "NetworkRequestHoldingTime" SG_ 1080 RL_SHVU_SeatHtOperSta 5000;
BA_ "Version" SG_ 1080 RL_SHVU_SeatHtOperSta "22.05.04";
BA_ "Description" SG_ 1080 RL_SHVU_HtSwHiIndSta_RHD "RL ½ÃÆ® ¿­¼± ½ºÀ§Ä¡ High Indicator Á¤º¸ (RHD)

-2nd LH Seat heater high Information";
BA_ "GenSigSendType" SG_ 1080 RL_SHVU_HtSwHiIndSta_RHD 4;
BA_ "UserSigValidity" SG_ 1080 RL_SHVU_HtSwHiIndSta_RHD 7;
BA_REL_ "GenSigTimeoutTime" BU_SG_REL_ ATS SG_ 1080 RL_SHVU_HtSwHiIndSta_RHD 1500;
BA_REL_ "GenSigTimeoutTime" BU_SG_REL_ CGW_CCU SG_ 1080 RL_SHVU_HtSwHiIndSta_RHD 1500;
BA_ "NetworkRequest" SG_ 1080 RL_SHVU_HtSwHiIndSta_RHD 0;
BA_ "NetworkRequestHoldingTime" SG_ 1080 RL_SHVU_HtSwHiIndSta_RHD 5000;
BA_ "Version" SG_ 1080 RL_SHVU_HtSwHiIndSta_RHD "22.05.04";
BA_ "Description" SG_ 1080 RL_SHVU_HtSwMidIndSta_RHD "RL ½ÃÆ® ¿­¼± ½ºÀ§Ä¡ Mid Indicator Á¤º¸ (RHD)

-2nd LH Seat heater mid Information";
BA_ "GenSigSendType" SG_ 1080 RL_SHVU_HtSwMidIndSta_RHD 4;
BA_ "UserSigValidity" SG_ 1080 RL_SHVU_HtSwMidIndSta_RHD 7;
BA_REL_ "GenSigTimeoutTime" BU_SG_REL_ ATS SG_ 1080 RL_SHVU_HtSwMidIndSta_RHD 1500;
BA_REL_ "GenSigTimeoutTime" BU_SG_REL_ CGW_CCU SG_ 1080 RL_SHVU_HtSwMidIndSta_RHD 1500;
BA_ "NetworkRequest" SG_ 1080 RL_SHVU_HtSwMidIndSta_RHD 0;
BA_ "NetworkRequestHoldingTime" SG_ 1080 RL_SHVU_HtSwMidIndSta_RHD 5000;
BA_ "Version" SG_ 1080 RL_SHVU_HtSwMidIndSta_RHD "22.05.04";
BA_ "Description" SG_ 1080 RL_SHVU_HtSwLowIndSta_RHD "RL ½ÃÆ® ¿­¼± ½ºÀ§Ä¡ Low Indicator Á¤º¸ (RHD)

-2nd LH Seat heater low Information";
BA_ "GenSigSendType" SG_ 1080 RL_SHVU_HtSwLowIndSta_RHD 4;
BA_ "UserSigValidity" SG_ 1080 RL_SHVU_HtSwLowIndSta_RHD 7;
BA_REL_ "GenSigTimeoutTime" BU_SG_REL_ ATS SG_ 1080 RL_SHVU_HtSwLowIndSta_RHD 1500;
BA_REL_ "GenSigTimeoutTime" BU_SG_REL_ CGW_CCU SG_ 1080 RL_SHVU_HtSwLowIndSta_RHD 1500;
BA_ "NetworkRequest" SG_ 1080 RL_SHVU_HtSwLowIndSta_RHD 0;
BA_ "NetworkRequestHoldingTime" SG_ 1080 RL_SHVU_HtSwLowIndSta_RHD 5000;
BA_ "Version" SG_ 1080 RL_SHVU_HtSwLowIndSta_RHD "22.05.04";
BA_ "Description" SG_ 1080 RL_SHVU_VntSwHiIndSta_RHD "RL ½ÃÆ® ÅëÇ³ ½ºÀ§Ä¡ High Indicator Á¤º¸ (RHD)

-2nd LH Seat vent high Information";
BA_ "GenSigSendType" SG_ 1080 RL_SHVU_VntSwHiIndSta_RHD 4;
BA_ "UserSigValidity" SG_ 1080 RL_SHVU_VntSwHiIndSta_RHD 7;
BA_REL_ "GenSigTimeoutTime" BU_SG_REL_ ATS SG_ 1080 RL_SHVU_VntSwHiIndSta_RHD 1500;
BA_REL_ "GenSigTimeoutTime" BU_SG_REL_ CGW_CCU SG_ 1080 RL_SHVU_VntSwHiIndSta_RHD 1500;
BA_ "NetworkRequest" SG_ 1080 RL_SHVU_VntSwHiIndSta_RHD 0;
BA_ "NetworkRequestHoldingTime" SG_ 1080 RL_SHVU_VntSwHiIndSta_RHD 5000;
BA_ "Version" SG_ 1080 RL_SHVU_VntSwHiIndSta_RHD "22.05.04";
BA_ "Description" SG_ 1080 RL_SHVU_VntSwMidIndSta_RHD "RL ½ÃÆ® ÅëÇ³ ½ºÀ§Ä¡ Mid Indicator Á¤º¸ (RHD)

-2nd LH Seat vent mid Information";
BA_ "GenSigSendType" SG_ 1080 RL_SHVU_VntSwMidIndSta_RHD 4;
BA_ "UserSigValidity" SG_ 1080 RL_SHVU_VntSwMidIndSta_RHD 7;
BA_REL_ "GenSigTimeoutTime" BU_SG_REL_ ATS SG_ 1080 RL_SHVU_VntSwMidIndSta_RHD 1500;
BA_REL_ "GenSigTimeoutTime" BU_SG_REL_ CGW_CCU SG_ 1080 RL_SHVU_VntSwMidIndSta_RHD 1500;
BA_ "NetworkRequest" SG_ 1080 RL_SHVU_VntSwMidIndSta_RHD 0;
BA_ "NetworkRequestHoldingTime" SG_ 1080 RL_SHVU_VntSwMidIndSta_RHD 5000;
BA_ "Version" SG_ 1080 RL_SHVU_VntSwMidIndSta_RHD "22.05.04";
BA_ "Description" SG_ 1080 RL_SHVU_VntSwLowIndSta_RHD "RL ½ÃÆ® ÅëÇ³ ½ºÀ§Ä¡ Low Indicator Á¤º¸ (RHD)

-2nd LH Seat vent low Information";
BA_ "GenSigSendType" SG_ 1080 RL_SHVU_VntSwLowIndSta_RHD 4;
BA_ "UserSigValidity" SG_ 1080 RL_SHVU_VntSwLowIndSta_RHD 7;
BA_REL_ "GenSigTimeoutTime" BU_SG_REL_ ATS SG_ 1080 RL_SHVU_VntSwLowIndSta_RHD 1500;
BA_REL_ "GenSigTimeoutTime" BU_SG_REL_ CGW_CCU SG_ 1080 RL_SHVU_VntSwLowIndSta_RHD 1500;
BA_ "NetworkRequest" SG_ 1080 RL_SHVU_VntSwLowIndSta_RHD 0;
BA_ "NetworkRequestHoldingTime" SG_ 1080 RL_SHVU_VntSwLowIndSta_RHD 5000;
BA_ "Version" SG_ 1080 RL_SHVU_VntSwLowIndSta_RHD "22.05.04";
BA_ "Description" SG_ 1080 RL_SHVU_HtBlcUsmSta_RHD "RL Seat Heater Balance Status(RHD)";
BA_ "GenSigSendType" SG_ 1080 RL_SHVU_HtBlcUsmSta_RHD 4;
BA_ "UserSigValidity" SG_ 1080 RL_SHVU_HtBlcUsmSta_RHD 7;
BA_REL_ "GenSigTimeoutTime" BU_SG_REL_ ATS SG_ 1080 RL_SHVU_HtBlcUsmSta_RHD 1500;
BA_REL_ "GenSigTimeoutTime" BU_SG_REL_ CGW_CCU SG_ 1080 RL_SHVU_HtBlcUsmSta_RHD 1500;
BA_ "NetworkRequest" SG_ 1080 RL_SHVU_HtBlcUsmSta_RHD 0;
BA_ "NetworkRequestHoldingTime" SG_ 1080 RL_SHVU_HtBlcUsmSta_RHD 5000;
BA_ "Version" SG_ 1080 RL_SHVU_HtBlcUsmSta_RHD "22.05.04";
BA_ "GenMsgSendType" BO_ 1070 0;
BA_ "Description" SG_ 1070 RL_SHVU_HtSwHiIndSta "RL ½ÃÆ® ¿­¼± ½ºÀ§Ä¡ High Indicator Á¤º¸

-2nd LH Seat heater high Information";
BA_ "GenSigSendType" SG_ 1070 RL_SHVU_HtSwHiIndSta 4;
BA_ "UserSigValidity" SG_ 1070 RL_SHVU_HtSwHiIndSta 7;
BA_REL_ "GenSigTimeoutTime" BU_SG_REL_ ARS SG_ 1070 RL_SHVU_HtSwHiIndSta 1500;
BA_REL_ "GenSigTimeoutTime" BU_SG_REL_ ATS SG_ 1070 RL_SHVU_HtSwHiIndSta 1500;
BA_REL_ "GenSigTimeoutTime" BU_SG_REL_ CGW_CCU SG_ 1070 RL_SHVU_HtSwHiIndSta 1500;
BA_ "NetworkRequest" SG_ 1070 RL_SHVU_HtSwHiIndSta 0;
BA_ "NetworkRequestHoldingTime" SG_ 1070 RL_SHVU_HtSwHiIndSta 5000;
BA_ "Version" SG_ 1070 RL_SHVU_HtSwHiIndSta "22.05.04";
BA_ "Description" SG_ 1070 RL_SHVU_HtSwMidIndSta "RL ½ÃÆ® ¿­¼± ½ºÀ§Ä¡ Mid Indicator Á¤º¸

-2nd LH Seat heater mid Information";
BA_ "GenSigSendType" SG_ 1070 RL_SHVU_HtSwMidIndSta 4;
BA_ "UserSigValidity" SG_ 1070 RL_SHVU_HtSwMidIndSta 7;
BA_REL_ "GenSigTimeoutTime" BU_SG_REL_ ARS SG_ 1070 RL_SHVU_HtSwMidIndSta 1500;
BA_REL_ "GenSigTimeoutTime" BU_SG_REL_ ATS SG_ 1070 RL_SHVU_HtSwMidIndSta 1500;
BA_REL_ "GenSigTimeoutTime" BU_SG_REL_ CGW_CCU SG_ 1070 RL_SHVU_HtSwMidIndSta 1500;
BA_ "NetworkRequest" SG_ 1070 RL_SHVU_HtSwMidIndSta 0;
BA_ "NetworkRequestHoldingTime" SG_ 1070 RL_SHVU_HtSwMidIndSta 5000;
BA_ "Version" SG_ 1070 RL_SHVU_HtSwMidIndSta "22.05.04";
BA_ "Description" SG_ 1070 RL_SHVU_HtSwLowIndSta "RL ½ÃÆ® ¿­¼± ½ºÀ§Ä¡ Low Indicator Á¤º¸

-2nd LH Seat heater low Information";
BA_ "GenSigSendType" SG_ 1070 RL_SHVU_HtSwLowIndSta 4;
BA_ "UserSigValidity" SG_ 1070 RL_SHVU_HtSwLowIndSta 7;
BA_REL_ "GenSigTimeoutTime" BU_SG_REL_ ARS SG_ 1070 RL_SHVU_HtSwLowIndSta 1500;
BA_REL_ "GenSigTimeoutTime" BU_SG_REL_ ATS SG_ 1070 RL_SHVU_HtSwLowIndSta 1500;
BA_REL_ "GenSigTimeoutTime" BU_SG_REL_ CGW_CCU SG_ 1070 RL_SHVU_HtSwLowIndSta 1500;
BA_ "NetworkRequest" SG_ 1070 RL_SHVU_HtSwLowIndSta 0;
BA_ "NetworkRequestHoldingTime" SG_ 1070 RL_SHVU_HtSwLowIndSta 5000;
BA_ "Version" SG_ 1070 RL_SHVU_HtSwLowIndSta "22.05.04";
BA_ "Description" SG_ 1070 RL_SHVU_VntSwHiIndSta "RL ½ÃÆ® ÅëÇ³ ½ºÀ§Ä¡ High Indicator Á¤º¸

-2nd LH Seat vent high Information";
BA_ "GenSigSendType" SG_ 1070 RL_SHVU_VntSwHiIndSta 4;
BA_ "UserSigValidity" SG_ 1070 RL_SHVU_VntSwHiIndSta 7;
BA_REL_ "GenSigTimeoutTime" BU_SG_REL_ ARS SG_ 1070 RL_SHVU_VntSwHiIndSta 1500;
BA_REL_ "GenSigTimeoutTime" BU_SG_REL_ ATS SG_ 1070 RL_SHVU_VntSwHiIndSta 1500;
BA_REL_ "GenSigTimeoutTime" BU_SG_REL_ CGW_CCU SG_ 1070 RL_SHVU_VntSwHiIndSta 1500;
BA_ "NetworkRequest" SG_ 1070 RL_SHVU_VntSwHiIndSta 0;
BA_ "NetworkRequestHoldingTime" SG_ 1070 RL_SHVU_VntSwHiIndSta 5000;
BA_ "Version" SG_ 1070 RL_SHVU_VntSwHiIndSta "22.05.04";
BA_ "Description" SG_ 1070 RL_SHVU_VntSwMidIndSta "RL ½ÃÆ® ÅëÇ³ ½ºÀ§Ä¡ Mid Indicator Á¤º¸

-2nd LH Seat vent mid Information";
BA_ "GenSigSendType" SG_ 1070 RL_SHVU_VntSwMidIndSta 4;
BA_ "UserSigValidity" SG_ 1070 RL_SHVU_VntSwMidIndSta 7;
BA_REL_ "GenSigTimeoutTime" BU_SG_REL_ ARS SG_ 1070 RL_SHVU_VntSwMidIndSta 1500;
BA_REL_ "GenSigTimeoutTime" BU_SG_REL_ ATS SG_ 1070 RL_SHVU_VntSwMidIndSta 1500;
BA_REL_ "GenSigTimeoutTime" BU_SG_REL_ CGW_CCU SG_ 1070 RL_SHVU_VntSwMidIndSta 1500;
BA_ "NetworkRequest" SG_ 1070 RL_SHVU_VntSwMidIndSta 0;
BA_ "NetworkRequestHoldingTime" SG_ 1070 RL_SHVU_VntSwMidIndSta 5000;
BA_ "Version" SG_ 1070 RL_SHVU_VntSwMidIndSta "22.05.04";
BA_ "Description" SG_ 1070 RL_SHVU_VntSwLowIndSta "RL ½ÃÆ® ÅëÇ³ ½ºÀ§Ä¡ Low Indicator Á¤º¸

-2nd LH Seat vent low Information";
BA_ "GenSigSendType" SG_ 1070 RL_SHVU_VntSwLowIndSta 4;
BA_ "UserSigValidity" SG_ 1070 RL_SHVU_VntSwLowIndSta 7;
BA_REL_ "GenSigTimeoutTime" BU_SG_REL_ ARS SG_ 1070 RL_SHVU_VntSwLowIndSta 1500;
BA_REL_ "GenSigTimeoutTime" BU_SG_REL_ ATS SG_ 1070 RL_SHVU_VntSwLowIndSta 1500;
BA_REL_ "GenSigTimeoutTime" BU_SG_REL_ CGW_CCU SG_ 1070 RL_SHVU_VntSwLowIndSta 1500;
BA_ "NetworkRequest" SG_ 1070 RL_SHVU_VntSwLowIndSta 0;
BA_ "NetworkRequestHoldingTime" SG_ 1070 RL_SHVU_VntSwLowIndSta 5000;
BA_ "Version" SG_ 1070 RL_SHVU_VntSwLowIndSta "22.05.04";
BA_ "Description" SG_ 1070 RL_SHVU_HtBlcUsmSta "RL Seat Heater Balance Status";
BA_ "GenSigSendType" SG_ 1070 RL_SHVU_HtBlcUsmSta 4;
BA_ "UserSigValidity" SG_ 1070 RL_SHVU_HtBlcUsmSta 7;
BA_REL_ "GenSigTimeoutTime" BU_SG_REL_ ATS SG_ 1070 RL_SHVU_HtBlcUsmSta 1500;
BA_REL_ "GenSigTimeoutTime" BU_SG_REL_ CGW_CCU SG_ 1070 RL_SHVU_HtBlcUsmSta 1500;
BA_ "NetworkRequest" SG_ 1070 RL_SHVU_HtBlcUsmSta 0;
BA_ "NetworkRequestHoldingTime" SG_ 1070 RL_SHVU_HtBlcUsmSta 5000;
BA_ "Version" SG_ 1070 RL_SHVU_HtBlcUsmSta "22.05.04";
BA_ "GenMsgSendType" BO_ 1069 0;
BA_ "Description" SG_ 1069 RRPSU_ReclMtrPos "2¿­ RH ½ÃÆ® Recline ¸ðÅÍ À§Ä¡°ª ¼Û½Å

 - Seat Recline Position Information signal for 2nd RH seat";
BA_ "GenSigSendType" SG_ 1069 RRPSU_ReclMtrPos 4;
BA_ "UserSigValidity" SG_ 1069 RRPSU_ReclMtrPos 0;
BA_REL_ "GenSigTimeoutTime" BU_SG_REL_ PFSU SG_ 1069 RRPSU_ReclMtrPos 1500;
BA_ "NetworkRequest" SG_ 1069 RRPSU_ReclMtrPos 0;
BA_ "NetworkRequestHoldingTime" SG_ 1069 RRPSU_ReclMtrPos 5000;
BA_ "Version" SG_ 1069 RRPSU_ReclMtrPos "21.07.06";
BA_ "Description" SG_ 1069 RRPSU_PwrSeatOpt "2¿­ ¿ìÃø ¸®Å¬¶óÀÌ³Ê ½ÃÆ® ¿É¼Ç Á¤º¸";
BA_ "GenSigSendType" SG_ 1069 RRPSU_PwrSeatOpt 4;
BA_ "UserSigValidity" SG_ 1069 RRPSU_PwrSeatOpt 0;
BA_REL_ "GenSigTimeoutTime" BU_SG_REL_ CGW_CCU SG_ 1069 RRPSU_PwrSeatOpt 1500;
BA_ "Version" SG_ 1069 RRPSU_PwrSeatOpt "19.08.05";
BA_ "Description" SG_ 1069 RRPSU_PwrSeatPos "2¿­ ¿ìÃø ½ÃÆ® ¹é À§Ä¡¿¡ µû¸¥ ¹öÆ° È°¼ºÈ­ / ºñÈ°¼ºÈ­";
BA_ "GenSigSendType" SG_ 1069 RRPSU_PwrSeatPos 4;
BA_ "UserSigValidity" SG_ 1069 RRPSU_PwrSeatPos 0;
BA_REL_ "GenSigTimeoutTime" BU_SG_REL_ CGW_CCU SG_ 1069 RRPSU_PwrSeatPos 1500;
BA_ "Version" SG_ 1069 RRPSU_PwrSeatPos "21.07.06";
BA_ "Description" SG_ 1069 RRPSU_RRSlidPos "2¿­ ¿ìÃø ½ÃÆ® ½½¶óÀÌµå ¸ðÅÍ À§Ä¡¿¡ µû¸¥ ¹öÆ° È°¼ºÈ­ / ºñÈ°¼ºÈ­";
BA_ "GenSigSendType" SG_ 1069 RRPSU_RRSlidPos 4;
BA_ "UserSigValidity" SG_ 1069 RRPSU_RRSlidPos 0;
BA_REL_ "GenSigTimeoutTime" BU_SG_REL_ CGW_CCU SG_ 1069 RRPSU_RRSlidPos 1500;
BA_ "Version" SG_ 1069 RRPSU_RRSlidPos "21.07.06";
BA_ "Description" SG_ 1069 RRPSU_RRRclPos "2¿­ ¿ìÃø ½ÃÆ® ¸®Å¬¶óÀÌ³Ê ¸ðÅÍ À§Ä¡¿¡ µû¸¥ ¹öÆ° È°¼ºÈ­ / ºñÈ°¼ºÈ­";
BA_ "GenSigSendType" SG_ 1069 RRPSU_RRRclPos 4;
BA_ "UserSigValidity" SG_ 1069 RRPSU_RRRclPos 0;
BA_REL_ "GenSigTimeoutTime" BU_SG_REL_ CGW_CCU SG_ 1069 RRPSU_RRRclPos 1500;
BA_ "Version" SG_ 1069 RRPSU_RRRclPos "21.07.06";
BA_ "Description" SG_ 1069 RRPSU_RRTiltPos "2¿­ ¿ìÃø ½ÃÆ® Äí¼Ç Æ¿Æ® ¸ðÅÍ À§Ä¡¿¡ µû¸¥ ¹öÆ° È°¼ºÈ­ / ºñÈ°¼ºÈ­";
BA_ "GenSigSendType" SG_ 1069 RRPSU_RRTiltPos 4;
BA_ "UserSigValidity" SG_ 1069 RRPSU_RRTiltPos 0;
BA_REL_ "GenSigTimeoutTime" BU_SG_REL_ CGW_CCU SG_ 1069 RRPSU_RRTiltPos 1500;
BA_ "Version" SG_ 1069 RRPSU_RRTiltPos "21.07.06";
BA_ "Description" SG_ 1069 RRPSU_RRLegExtPos "2¿­ ¿ìÃø ½ÃÆ® ·¹±× ÀÍ½ºÅÙ¼Ç (ÀüÈÄ¹æ) ¸ðÅÍ À§Ä¡¿¡ µû¸¥ ¹öÆ° È°¼ºÈ­ / ºñÈ°¼ºÈ­";
BA_ "GenSigSendType" SG_ 1069 RRPSU_RRLegExtPos 4;
BA_ "UserSigValidity" SG_ 1069 RRPSU_RRLegExtPos 0;
BA_REL_ "GenSigTimeoutTime" BU_SG_REL_ CGW_CCU SG_ 1069 RRPSU_RRLegExtPos 1500;
BA_ "Version" SG_ 1069 RRPSU_RRLegExtPos "21.07.06";
BA_ "Description" SG_ 1069 RRPSU_RRLegSupPos "2¿­ ¿ìÃø ½ÃÆ® ·¹±×ÀÍ½ºÅÙ¼Ç (»óÇÏ¹æ) ¸ðÅÍ À§Ä¡¿¡ µû¸¥ ¹öÆ° È°¼ºÈ­ / ºñÈ°¼ºÈ­";
BA_ "GenSigSendType" SG_ 1069 RRPSU_RRLegSupPos 4;
BA_ "UserSigValidity" SG_ 1069 RRPSU_RRLegSupPos 0;
BA_REL_ "GenSigTimeoutTime" BU_SG_REL_ CGW_CCU SG_ 1069 RRPSU_RRLegSupPos 1500;
BA_ "Version" SG_ 1069 RRPSU_RRLegSupPos "21.07.06";
BA_ "Description" SG_ 1069 RRPSU_RRStEsyAcsUSMSta "Rear RH Seat EasyAccess USM Setting";
BA_ "GenSigSendType" SG_ 1069 RRPSU_RRStEsyAcsUSMSta 4;
BA_ "UserSigValidity" SG_ 1069 RRPSU_RRStEsyAcsUSMSta 0;
BA_REL_ "GenSigTimeoutTime" BU_SG_REL_ CGW_CCU SG_ 1069 RRPSU_RRStEsyAcsUSMSta 1500;
BA_ "Version" SG_ 1069 RRPSU_RRStEsyAcsUSMSta "21.07.06";
BA_ "Description" SG_ 1069 RRPSU_RRHrestSlidPos "2¿­ ¿ìÃø ½ÃÆ® Çìµå·¹½ºÆ® ½½¶óÀÌµå À§Ä¡¿¡ µû¸¥ ¹öÆ° È°¼ºÈ­ / ºñÈ°¼ºÈ­";
BA_ "GenSigSendType" SG_ 1069 RRPSU_RRHrestSlidPos 4;
BA_ "UserSigValidity" SG_ 1069 RRPSU_RRHrestSlidPos 0;
BA_REL_ "GenSigTimeoutTime" BU_SG_REL_ CGW_CCU SG_ 1069 RRPSU_RRHrestSlidPos 1500;
BA_ "Version" SG_ 1069 RRPSU_RRHrestSlidPos "21.07.06";
BA_ "Description" SG_ 1069 RRPSU_RRHrestHeightPos "2¿­ ¿ìÃø ½ÃÆ® Çìµå·¹½ºÆ® ÇÏÀÌÆ® ¸ðÅÍ À§Ä¡¿¡ µû¸¥ ¹öÆ° È°¼ºÈ­ / ºñÈ°¼ºÈ­";
BA_ "GenSigSendType" SG_ 1069 RRPSU_RRHrestHeightPos 4;
BA_ "UserSigValidity" SG_ 1069 RRPSU_RRHrestHeightPos 0;
BA_REL_ "GenSigTimeoutTime" BU_SG_REL_ CGW_CCU SG_ 1069 RRPSU_RRHrestHeightPos 1500;
BA_ "Version" SG_ 1069 RRPSU_RRHrestHeightPos "21.07.06";
BA_ "Description" SG_ 1069 RRPSU_Opt_Captain "PWR_HVU Option_Captain";
BA_ "GenSigSendType" SG_ 1069 RRPSU_Opt_Captain 4;
BA_ "UserSigValidity" SG_ 1069 RRPSU_Opt_Captain 0;
BA_REL_ "GenSigTimeoutTime" BU_SG_REL_ CGW_CCU SG_ 1069 RRPSU_Opt_Captain 1500;
BA_ "Version" SG_ 1069 RRPSU_Opt_Captain "20.10.02";
BA_ "Description" SG_ 1069 RR_AutoRlxSta "ÈÄ¼® RH ½ÃÆ® ¿ÀÅä ¸±·º¼Ç µ¿ÀÛ »óÅÂ Á¤º¸";
BA_ "GenSigSendType" SG_ 1069 RR_AutoRlxSta 4;
BA_ "UserSigValidity" SG_ 1069 RR_AutoRlxSta 0;
BA_REL_ "GenSigTimeoutTime" BU_SG_REL_ GW_APSU SG_ 1069 RR_AutoRlxSta 1500;
BA_REL_ "GenSigTimeoutTime" BU_SG_REL_ GW_DPSU SG_ 1069 RR_AutoRlxSta 1500;
BA_REL_ "GenSigTimeoutTime" BU_SG_REL_ PFSU SG_ 1069 RR_AutoRlxSta 1500;
BA_ "NetworkRequest" SG_ 1069 RR_AutoRlxSta 0;
BA_ "NetworkRequestHoldingTime" SG_ 1069 RR_AutoRlxSta 5000;
BA_ "Version" SG_ 1069 RR_AutoRlxSta "21.07.06";
BA_ "Description" SG_ 1069 RR_FRStAutoRlxEnable "ÈÄ¼® RH ½ÃÆ® À§Ä¡¿¡ µû¸¥ Àü¼® RH ¿ÀÅä ¸±·º¼Ç µ¿ÀÛ ÆÇ´Ü ½ÅÈ£";
BA_ "GenSigSendType" SG_ 1069 RR_FRStAutoRlxEnable 4;
BA_ "UserSigValidity" SG_ 1069 RR_FRStAutoRlxEnable 0;
BA_REL_ "GenSigTimeoutTime" BU_SG_REL_ GW_APSU SG_ 1069 RR_FRStAutoRlxEnable 1500;
BA_REL_ "GenSigTimeoutTime" BU_SG_REL_ GW_DPSU SG_ 1069 RR_FRStAutoRlxEnable 1500;
BA_ "NetworkRequest" SG_ 1069 RR_FRStAutoRlxEnable 0;
BA_ "NetworkRequestHoldingTime" SG_ 1069 RR_FRStAutoRlxEnable 5000;
BA_ "Version" SG_ 1069 RR_FRStAutoRlxEnable "21.06.10";
BA_ "Description" SG_ 1069 RRHVU_Opt_Captain "MNL_HVU Option_Captain";
BA_ "GenSigSendType" SG_ 1069 RRHVU_Opt_Captain 4;
BA_ "UserSigValidity" SG_ 1069 RRHVU_Opt_Captain 0;
BA_REL_ "GenSigTimeoutTime" BU_SG_REL_ CGW_CCU SG_ 1069 RRHVU_Opt_Captain 1500;
BA_ "Version" SG_ 1069 RRHVU_Opt_Captain "21.07.06";
BA_ "Description" SG_ 1069 RR_AutoFoldSta "This signal is used to check the second row folding operation status when the passenger seat is relaxed.";
BA_ "GenSigSendType" SG_ 1069 RR_AutoFoldSta 4;
BA_ "UserSigValidity" SG_ 1069 RR_AutoFoldSta 0;
BA_REL_ "GenSigTimeoutTime" BU_SG_REL_ GW_APSU SG_ 1069 RR_AutoFoldSta 1500;
BA_REL_ "GenSigTimeoutTime" BU_SG_REL_ GW_DPSU SG_ 1069 RR_AutoFoldSta 1500;
BA_ "NetworkRequest" SG_ 1069 RR_AutoFoldSta 0;
BA_ "NetworkRequestHoldingTime" SG_ 1069 RR_AutoFoldSta 5000;
BA_ "Version" SG_ 1069 RR_AutoFoldSta "22.05.02";
BA_ "Description" SG_ 1069 RR_AutoWalkInSta "This signal is used to check the second row WalkIn operation status when the passenger seat is relaxed.";
BA_ "GenSigSendType" SG_ 1069 RR_AutoWalkInSta 4;
BA_ "UserSigValidity" SG_ 1069 RR_AutoWalkInSta 0;
BA_REL_ "GenSigTimeoutTime" BU_SG_REL_ GW_APSU SG_ 1069 RR_AutoWalkInSta 1500;
BA_REL_ "GenSigTimeoutTime" BU_SG_REL_ GW_DPSU SG_ 1069 RR_AutoWalkInSta 1500;
BA_ "NetworkRequest" SG_ 1069 RR_AutoWalkInSta 0;
BA_ "NetworkRequestHoldingTime" SG_ 1069 RR_AutoWalkInSta 5000;
BA_ "Version" SG_ 1069 RR_AutoWalkInSta "22.05.02";
BA_ "Description" SG_ 1069 RR_TRAutoFldEnable "2¿­ RRÃø ½ÃÆ® À§Ä¡ Á¤º¸¿¡ µû¸¥ 3¿­ TRÃø Æúµù/¾ðÆúµù µ¿ÀÛ °¡´É ¿©ºÎ ÆÇ´Ü Á¶°Ç";
BA_ "GenSigSendType" SG_ 1069 RR_TRAutoFldEnable 4;
BA_ "UserSigValidity" SG_ 1069 RR_TRAutoFldEnable 0;
BA_REL_ "GenSigTimeoutTime" BU_SG_REL_ PFSU SG_ 1069 RR_TRAutoFldEnable 1500;
BA_ "NetworkRequest" SG_ 1069 RR_TRAutoFldEnable 0;
BA_ "NetworkRequestHoldingTime" SG_ 1069 RR_TRAutoFldEnable 5000;
BA_ "Version" SG_ 1069 RR_TRAutoFldEnable "22.05.02";
BA_ "Description" SG_ 1069 RRPSU_RLStEsyAcsUSMSta "Rear LH Seat EasyAccess USM Setting";
BA_ "GenSigSendType" SG_ 1069 RRPSU_RLStEsyAcsUSMSta 4;
BA_ "UserSigValidity" SG_ 1069 RRPSU_RLStEsyAcsUSMSta 0;
BA_REL_ "GenSigTimeoutTime" BU_SG_REL_ CGW_CCU SG_ 1069 RRPSU_RLStEsyAcsUSMSta 1500;
BA_ "Version" SG_ 1069 RRPSU_RLStEsyAcsUSMSta "21.07.06";
BA_ "Description" SG_ 1069 RRPSU_Opt "PWR_HVU Option";
BA_ "GenSigSendType" SG_ 1069 RRPSU_Opt 4;
BA_ "UserSigValidity" SG_ 1069 RRPSU_Opt 0;
BA_REL_ "GenSigTimeoutTime" BU_SG_REL_ CGW_CCU SG_ 1069 RRPSU_Opt 1500;
BA_ "Version" SG_ 1069 RRPSU_Opt "19.03.05";
BA_ "GenMsgSendType" BO_ 1071 0;
BA_ "Description" SG_ 1071 RR_SHVU_HtSwHiIndSta "RR ½ÃÆ® ¿­¼± ½ºÀ§Ä¡ High Indicator Á¤º¸

-2nd RH Seat heater high Information";
BA_ "GenSigSendType" SG_ 1071 RR_SHVU_HtSwHiIndSta 4;
BA_ "UserSigValidity" SG_ 1071 RR_SHVU_HtSwHiIndSta 7;
BA_REL_ "GenSigTimeoutTime" BU_SG_REL_ ARS SG_ 1071 RR_SHVU_HtSwHiIndSta 1500;
BA_REL_ "GenSigTimeoutTime" BU_SG_REL_ ATS SG_ 1071 RR_SHVU_HtSwHiIndSta 1500;
BA_REL_ "GenSigTimeoutTime" BU_SG_REL_ CGW_CCU SG_ 1071 RR_SHVU_HtSwHiIndSta 1500;
BA_ "NetworkRequest" SG_ 1071 RR_SHVU_HtSwHiIndSta 0;
BA_ "NetworkRequestHoldingTime" SG_ 1071 RR_SHVU_HtSwHiIndSta 5000;
BA_ "Version" SG_ 1071 RR_SHVU_HtSwHiIndSta "22.05.04";
BA_ "Description" SG_ 1071 RR_SHVU_HtSwMidIndSta "RL ½ÃÆ® ¿­¼± ½ºÀ§Ä¡ Mid Indicator Á¤º¸

-2nd LH Seat heater mid Information";
BA_ "GenSigSendType" SG_ 1071 RR_SHVU_HtSwMidIndSta 4;
BA_ "UserSigValidity" SG_ 1071 RR_SHVU_HtSwMidIndSta 7;
BA_REL_ "GenSigTimeoutTime" BU_SG_REL_ ARS SG_ 1071 RR_SHVU_HtSwMidIndSta 1500;
BA_REL_ "GenSigTimeoutTime" BU_SG_REL_ ATS SG_ 1071 RR_SHVU_HtSwMidIndSta 1500;
BA_REL_ "GenSigTimeoutTime" BU_SG_REL_ CGW_CCU SG_ 1071 RR_SHVU_HtSwMidIndSta 1500;
BA_ "NetworkRequest" SG_ 1071 RR_SHVU_HtSwMidIndSta 0;
BA_ "NetworkRequestHoldingTime" SG_ 1071 RR_SHVU_HtSwMidIndSta 5000;
BA_ "Version" SG_ 1071 RR_SHVU_HtSwMidIndSta "22.05.04";
BA_ "Description" SG_ 1071 RR_SHVU_HtSwLowIndSta "RR ½ÃÆ® ¿­¼± ½ºÀ§Ä¡ Low Indicator Á¤º¸

-2nd RH Seat heater low Information";
BA_ "GenSigSendType" SG_ 1071 RR_SHVU_HtSwLowIndSta 4;
BA_ "UserSigValidity" SG_ 1071 RR_SHVU_HtSwLowIndSta 7;
BA_REL_ "GenSigTimeoutTime" BU_SG_REL_ ARS SG_ 1071 RR_SHVU_HtSwLowIndSta 1500;
BA_REL_ "GenSigTimeoutTime" BU_SG_REL_ ATS SG_ 1071 RR_SHVU_HtSwLowIndSta 1500;
BA_REL_ "GenSigTimeoutTime" BU_SG_REL_ CGW_CCU SG_ 1071 RR_SHVU_HtSwLowIndSta 1500;
BA_ "NetworkRequest" SG_ 1071 RR_SHVU_HtSwLowIndSta 0;
BA_ "NetworkRequestHoldingTime" SG_ 1071 RR_SHVU_HtSwLowIndSta 5000;
BA_ "Version" SG_ 1071 RR_SHVU_HtSwLowIndSta "22.05.04";
BA_ "Description" SG_ 1071 RR_SHVU_VntSwHiIndSta "RR ½ÃÆ® ÅëÇ³ ½ºÀ§Ä¡ High Indicator Á¤º¸

-2nd RH Seat vent high Information";
BA_ "GenSigSendType" SG_ 1071 RR_SHVU_VntSwHiIndSta 4;
BA_ "UserSigValidity" SG_ 1071 RR_SHVU_VntSwHiIndSta 7;
BA_REL_ "GenSigTimeoutTime" BU_SG_REL_ ARS SG_ 1071 RR_SHVU_VntSwHiIndSta 1500;
BA_REL_ "GenSigTimeoutTime" BU_SG_REL_ ATS SG_ 1071 RR_SHVU_VntSwHiIndSta 1500;
BA_REL_ "GenSigTimeoutTime" BU_SG_REL_ CGW_CCU SG_ 1071 RR_SHVU_VntSwHiIndSta 1500;
BA_ "NetworkRequest" SG_ 1071 RR_SHVU_VntSwHiIndSta 0;
BA_ "NetworkRequestHoldingTime" SG_ 1071 RR_SHVU_VntSwHiIndSta 5000;
BA_ "Version" SG_ 1071 RR_SHVU_VntSwHiIndSta "22.05.04";
BA_ "Description" SG_ 1071 RR_SHVU_VntSwMidIndSta "RR ½ÃÆ® ÅëÇ³ ½ºÀ§Ä¡ Mid Indicator Á¤º¸

-2nd RH Seat vent mid Information";
BA_ "GenSigSendType" SG_ 1071 RR_SHVU_VntSwMidIndSta 4;
BA_ "UserSigValidity" SG_ 1071 RR_SHVU_VntSwMidIndSta 7;
BA_REL_ "GenSigTimeoutTime" BU_SG_REL_ ARS SG_ 1071 RR_SHVU_VntSwMidIndSta 1500;
BA_REL_ "GenSigTimeoutTime" BU_SG_REL_ ATS SG_ 1071 RR_SHVU_VntSwMidIndSta 1500;
BA_REL_ "GenSigTimeoutTime" BU_SG_REL_ CGW_CCU SG_ 1071 RR_SHVU_VntSwMidIndSta 1500;
BA_ "NetworkRequest" SG_ 1071 RR_SHVU_VntSwMidIndSta 0;
BA_ "NetworkRequestHoldingTime" SG_ 1071 RR_SHVU_VntSwMidIndSta 5000;
BA_ "Version" SG_ 1071 RR_SHVU_VntSwMidIndSta "22.05.04";
BA_ "Description" SG_ 1071 RR_SHVU_VntSwLowIndSta "RR ½ÃÆ® ÅëÇ³ ½ºÀ§Ä¡ Low Indicator Á¤º¸

-2nd RH Seat vent low Information";
BA_ "GenSigSendType" SG_ 1071 RR_SHVU_VntSwLowIndSta 4;
BA_ "UserSigValidity" SG_ 1071 RR_SHVU_VntSwLowIndSta 7;
BA_REL_ "GenSigTimeoutTime" BU_SG_REL_ ARS SG_ 1071 RR_SHVU_VntSwLowIndSta 1500;
BA_REL_ "GenSigTimeoutTime" BU_SG_REL_ ATS SG_ 1071 RR_SHVU_VntSwLowIndSta 1500;
BA_REL_ "GenSigTimeoutTime" BU_SG_REL_ CGW_CCU SG_ 1071 RR_SHVU_VntSwLowIndSta 1500;
BA_ "NetworkRequest" SG_ 1071 RR_SHVU_VntSwLowIndSta 0;
BA_ "NetworkRequestHoldingTime" SG_ 1071 RR_SHVU_VntSwLowIndSta 5000;
BA_ "Version" SG_ 1071 RR_SHVU_VntSwLowIndSta "22.05.04";
BA_ "Description" SG_ 1071 RR_SHVU_HtBlcUsmSta "RR Seat Heater Balance Status";
BA_ "GenSigSendType" SG_ 1071 RR_SHVU_HtBlcUsmSta 4;
BA_ "UserSigValidity" SG_ 1071 RR_SHVU_HtBlcUsmSta 7;
BA_REL_ "GenSigTimeoutTime" BU_SG_REL_ ATS SG_ 1071 RR_SHVU_HtBlcUsmSta 1500;
BA_REL_ "GenSigTimeoutTime" BU_SG_REL_ CGW_CCU SG_ 1071 RR_SHVU_HtBlcUsmSta 1500;
BA_ "NetworkRequest" SG_ 1071 RR_SHVU_HtBlcUsmSta 0;
BA_ "NetworkRequestHoldingTime" SG_ 1071 RR_SHVU_HtBlcUsmSta 5000;
BA_ "Version" SG_ 1071 RR_SHVU_HtBlcUsmSta "22.05.04";
BA_ "GenMsgSendType" BO_ 1073 0;
BA_ "Description" SG_ 1073 USM_ValCmdSta "USM request value of RWPC";
BA_ "GenSigSendType" SG_ 1073 USM_ValCmdSta 4;
BA_ "UserSigValidity" SG_ 1073 USM_ValCmdSta 0;
BA_REL_ "GenSigTimeoutTime" BU_SG_REL_ ATS SG_ 1073 USM_ValCmdSta 1500;
BA_REL_ "GenSigTimeoutTime" BU_SG_REL_ CGW_CCU SG_ 1073 USM_ValCmdSta 1500;
BA_ "NetworkRequest" SG_ 1073 USM_ValCmdSta 0;
BA_ "NetworkRequestHoldingTime" SG_ 1073 USM_ValCmdSta 5000;
BA_ "Version" SG_ 1073 USM_ValCmdSta "17.11.00";
BA_ "Description" SG_ 1073 RWPC_SWVerMinor1 "Indicate the RWPC software version as follows:

- The software version is displayed in three digits.

- The Major and Minor digits are separated by '.'

- Signal values are transmitted to ASCII codes.



¡Ø Example

RWPC_SWVerMajor1 : 0x41 (HEX) -> ASCII CODE : 'A' 

RWPC_SWVerMinor1 : 0x30 (HEX) -> ASCII CODE : '0'

RWPC_SWVerMinor2 : 0x33 (HEX) -> ASCII CODE : '3'

=> RWPC S/W Ver is displayed 'A.03'";
BA_ "GenSigSendType" SG_ 1073 RWPC_SWVerMinor1 4;
BA_ "UserSigValidity" SG_ 1073 RWPC_SWVerMinor1 0;
BA_REL_ "GenSigTimeoutTime" BU_SG_REL_ CGW_CCU SG_ 1073 RWPC_SWVerMinor1 1500;
BA_ "Version" SG_ 1073 RWPC_SWVerMinor1 "18.10.06";
BA_ "Description" SG_ 1073 WPC_PhnLftWrngRWPCSta "Warning by RWPC for User (Phone left in vehicle)";
BA_ "GenSigSendType" SG_ 1073 WPC_PhnLftWrngRWPCSta 4;
BA_ "UserSigValidity" SG_ 1073 WPC_PhnLftWrngRWPCSta 0;
BA_REL_ "GenSigTimeoutTime" BU_SG_REL_ ATS SG_ 1073 WPC_PhnLftWrngRWPCSta 1500;
BA_REL_ "GenSigTimeoutTime" BU_SG_REL_ CGW_CCU SG_ 1073 WPC_PhnLftWrngRWPCSta 1500;
BA_ "NetworkRequest" SG_ 1073 WPC_PhnLftWrngRWPCSta 0;
BA_ "NetworkRequestHoldingTime" SG_ 1073 WPC_PhnLftWrngRWPCSta 5000;
BA_ "Version" SG_ 1073 WPC_PhnLftWrngRWPCSta "24.01.00";
BA_ "Description" SG_ 1073 RWPC_SWVerMinor2 "Indicate the RWPC software version as follows:

- The software version is displayed in three digits.

- The Major and Minor digits are separated by '.'

- Signal values are transmitted to ASCII codes.



¡Ø Example

RWPC_SWVerMajor1 : 0x41 (HEX) -> ASCII CODE : 'A' 

RWPC_SWVerMinor1 : 0x30 (HEX) -> ASCII CODE : '0'

RWPC_SWVerMinor2 : 0x33 (HEX) -> ASCII CODE : '3'

=> RWPC S/W Ver is displayed 'A.03'";
BA_ "GenSigSendType" SG_ 1073 RWPC_SWVerMinor2 4;
BA_ "UserSigValidity" SG_ 1073 RWPC_SWVerMinor2 0;
BA_REL_ "GenSigTimeoutTime" BU_SG_REL_ CGW_CCU SG_ 1073 RWPC_SWVerMinor2 1500;
BA_ "Version" SG_ 1073 RWPC_SWVerMinor2 "18.10.06";
BA_ "Description" SG_ 1073 RWPC_IndSyncVal "WPC IND ANIVATION SYNC SIGNAL";
BA_ "GenSigSendType" SG_ 1073 RWPC_IndSyncVal 4;
BA_ "TimeoutValue" SG_ 1073 RWPC_IndSyncVal "0x0";
BA_ "UserSigValidity" SG_ 1073 RWPC_IndSyncVal 3;
BA_REL_ "GenSigTimeoutTime" BU_SG_REL_ WPC SG_ 1073 RWPC_IndSyncVal 1500;
BA_REL_ "GenSigTimeoutTime" BU_SG_REL_ WPC2 SG_ 1073 RWPC_IndSyncVal 1500;
BA_ "Version" SG_ 1073 RWPC_IndSyncVal "22.04.01";
BA_ "Description" SG_ 1073 USM_ValCmdStaforATS "USM request value of RWPC for ATS";
BA_ "GenSigSendType" SG_ 1073 USM_ValCmdStaforATS 4;
BA_ "UserSigValidity" SG_ 1073 USM_ValCmdStaforATS 0;
BA_REL_ "GenSigTimeoutTime" BU_SG_REL_ ATS SG_ 1073 USM_ValCmdStaforATS 1500;
BA_ "NetworkRequest" SG_ 1073 USM_ValCmdStaforATS 0;
BA_ "NetworkRequestHoldingTime" SG_ 1073 USM_ValCmdStaforATS 5000;
BA_ "Version" SG_ 1073 USM_ValCmdStaforATS "20.07.05";
BA_ "Description" SG_ 1073 RWPC_SWVerMajor1 "Indicate the RWPC software version as follows:

- The software version is displayed in three digits.

- The Major and Minor digits are separated by '.'

- Signal values are transmitted to ASCII codes.



¡Ø Example

RWPC_SWVerMajor1 : 0x41 (HEX) -> ASCII CODE : 'A' 

RWPC_SWVerMinor1 : 0x30 (HEX) -> ASCII CODE : '0'

RWPC_SWVerMinor2 : 0x33 (HEX) -> ASCII CODE : '3'

=> RWPC S/W Ver is displayed 'A.03'";
BA_ "GenSigSendType" SG_ 1073 RWPC_SWVerMajor1 4;
BA_ "UserSigValidity" SG_ 1073 RWPC_SWVerMajor1 0;
BA_REL_ "GenSigTimeoutTime" BU_SG_REL_ CGW_CCU SG_ 1073 RWPC_SWVerMajor1 1500;
BA_ "Version" SG_ 1073 RWPC_SWVerMajor1 "21.07.00";
BA_ "GenMsgSendType" BO_ 1067 0;
BA_ "Description" SG_ 1067 SCM_SWVerMajor1 "Indicate the SCM software version as follows:

- The software version is displayed in three digits.

- The Major and Minor digits are separated by '.'

- Signal values are transmitted to ASCII codes.



¡Ø Example

SCM_SWVerMajor1 : 0x41 (HEX) -> ASCII CODE : 'A' 

SCM_SWVerMinor1 : 0x30 (HEX) -> ASCII CODE : '0'

SCM_SWVerMinor2 : 0x33 (HEX) -> ASCII CODE : '3'

=> SCM S/W Ver is displayed 'A.03'";
BA_ "GenSigSendType" SG_ 1067 SCM_SWVerMajor1 4;
BA_ "UserSigValidity" SG_ 1067 SCM_SWVerMajor1 0;
BA_REL_ "GenSigTimeoutTime" BU_SG_REL_ CGW_CCU SG_ 1067 SCM_SWVerMajor1 1500;
BA_ "Version" SG_ 1067 SCM_SWVerMajor1 "20.12.04";
BA_ "Description" SG_ 1067 SCM_SWVerMinor1 "Indicate the SCM software version as follows:

- The software version is displayed in three digits.

- The Major and Minor digits are separated by '.'

- Signal values are transmitted to ASCII codes.



¡Ø Example

SCM_SWVerMajor1 : 0x41 (HEX) -> ASCII CODE : 'A' 

SCM_SWVerMinor1 : 0x30 (HEX) -> ASCII CODE : '0'

SCM_SWVerMinor2 : 0x33 (HEX) -> ASCII CODE : '3'

=> SCM S/W Ver is displayed 'A.03'";
BA_ "GenSigSendType" SG_ 1067 SCM_SWVerMinor1 4;
BA_ "UserSigValidity" SG_ 1067 SCM_SWVerMinor1 0;
BA_REL_ "GenSigTimeoutTime" BU_SG_REL_ CGW_CCU SG_ 1067 SCM_SWVerMinor1 1500;
BA_ "Version" SG_ 1067 SCM_SWVerMinor1 "18.10.06";
BA_ "Description" SG_ 1067 SCM_SWVerMinor2 "Indicate the SCM software version as follows:

- The software version is displayed in three digits.

- The Major and Minor digits are separated by '.'

- Signal values are transmitted to ASCII codes.



¡Ø Example

SCM_SWVerMajor1 : 0x41 (HEX) -> ASCII CODE : 'A' 

SCM_SWVerMinor1 : 0x30 (HEX) -> ASCII CODE : '0'

SCM_SWVerMinor2 : 0x33 (HEX) -> ASCII CODE : '3'

=> SCM S/W Ver is displayed 'A.03'";
BA_ "GenSigSendType" SG_ 1067 SCM_SWVerMinor2 4;
BA_ "UserSigValidity" SG_ 1067 SCM_SWVerMinor2 0;
BA_REL_ "GenSigTimeoutTime" BU_SG_REL_ CGW_CCU SG_ 1067 SCM_SWVerMinor2 1500;
BA_ "Version" SG_ 1067 SCM_SWVerMinor2 "18.10.06";
VAL_ 1064 APSU_DiagSta 0 "Stop Diag" 1 "Start Diag" 2 "RESERVED" 3 "Error Indicator" ;
VAL_ 1064 APSU_AstAllLmtSta 0 "Default" 1 "Not Set" 2 "All Set" 3 "Invalid" ;
VAL_ 1064 APSU_EsyAcsGetOnSta 0 "off" 1 "on" 2 "RESERVED" 3 "Error Indicator" ;
VAL_ 1064 APSU_EsyAcsGetOffSta 0 "off" 1 "on" 2 "RESERVED" 3 "Error Indicator" ;
VAL_ 1064 APSU_EsyAcsStpSta 0 "off" 1 "on" 2 "RESERVED" 3 "Error Indicator" ;
VAL_ 1064 APSU_RVal 0 "Default Value" 1 "Off(Disable)" 2 "Enable" 3 "RESERVED" 4 "RESERVED" 5 "RESERVED" 6 "RESERVED" 7 "Invalid" ;
VAL_ 1058 BCM_Crc10Val 0 "0x0x0~0xFF:CRCValue" 255 "0x0x0~0xFF:CRCValue" ;
VAL_ 1058 BCM_AlvCnt10Val 0 "AlvCntValue" 1 "AlvCntValue" 2 "AlvCntValue" 3 "AlvCntValue" 4 "AlvCntValue" 5 "AlvCntValue" 6 "AlvCntValue" 7 "AlvCntValue" 8 "AlvCntValue" 9 "AlvCntValue" 10 "AlvCntValue" 11 "AlvCntValue" 12 "AlvCntValue" 13 "AlvCntValue" 14 "AlvCntValue" 15 "AlvCntValue" ;
VAL_ 1058 Wiper_PrkngPosSta 0 "else" 1 "Parking Position" 2 "Not Used" 3 "Error Indicator" ;
VAL_ 1058 Wiper_RainSnsrOptionTyp 0 "Non Rain Sensor Option" 1 "Rain Sensor Option" 2 "Not Used" 3 "Error Indicator" ;
VAL_ 1058 Wiper_RainSnsrSta 0 "OFF" 1 "Rain Detected" 2 "Low" 3 "High" 4 "Fault 1" 5 "Reserved" 6 "Reserved" 7 "Reserved" 8 "Reserved" 9 "Reserved" 10 "Reserved" 11 "Reserved" 12 "Reserved" 13 "Reserved" 14 "Not Used" 15 "Error Indicator" ;
VAL_ 1058 Wiper_HtWshNzzlCmd 0 "Off" 1 "On" 2 "Not Used" 3 "Error Indicator" ;
VAL_ 1058 BCM_GearPosPSta 0 "Off" 1 "P" 2 "Not Used" 3 "Error Indicator" ;
VAL_ 1058 BCM_SunRoofOpnSta 0 "Close" 1 "Open" 2 "Not Used" 3 "Error Indicator" ;
VAL_ 1058 SunRoof_RrBlindErrSta 0 "No error" 1 "Thermal Protection Active" 2 "Initialized Status" 3 "Undefined ECU Error" 4 "Switch Error" 5 "Voltage error" 6 "Complex Error" 7 "Invalid" ;
VAL_ 1058 Wiper_AutoWashModeSta 0 "Auto Wash Mode Off" 1 "Auto Wash Mode On" 2 "Not Used" 3 "Error Indicator" ;
VAL_ 1058 Wiper_RainSnsrPartNum 0 "T6000,NI000" 1 "EV000,DV000" 2 "CU000,XA000" 3 "CV000" 4 "KL000" 5 "DO000" 6 "CU500" 7 "RESERVED" 8 "RESERVED" 9 "RESERVED" 10 "RESERVED" 11 "RESERVED" 12 "RESERVED" 13 "RESERVED" 14 "RESERVED" 15 "L1000,N9000" ;
VAL_ 2357404929 BMS_Crc6Val 0 "0x0x0~0xFFFF:CRCValue" 65535 "0x0x0~0xFFFF:CRCValue" ;
VAL_ 2357404929 BMS_AlvCnt6Val 0 "0x0x0~0xFF:AlvCntValue" 255 "0x0x0~0xFF:AlvCntValue" ;
VAL_ 2357404929 CHRG_StndChrgConnSta_120V 0 "Not Connected" 1 "Connected" 2 "Not used" 3 "Error indicator" ;
VAL_ 2357404929 CHRG_StndChrgSta 0 "None" 1 "Standard Charging" 2 "Not used" 3 "Error indicator" ;
VAL_ 2357404929 CHRG_ChrgCycStrtSta 0 "Charging Cycle Start Disable" 1 "Charging Cycle Start Enable" 2 "Not used" 3 "Error indicator" ;
VAL_ 2357404929 CHRG_FulChrgSta 0 "None" 1 "Fully Charged" 2 "Not used" 3 "Error indicator" ;
VAL_ 2357404929 CHRG_ChrgSta 0 "None" 1 "Charging" 2 "Not used" 3 "Error indicator" ;
VAL_ 2357404929 CHRG_SpplmntChrgSta 0 "Not operating" 1 "operation" 2 "complete" 3 "fail" ;
VAL_ 2357404929 CHRG_LdcInhbtReq 0 "Noraml" 1 "LDC Inhibit" 2 "Not used" 3 "Error indicator" ;
VAL_ 2357404929 CHRG_NorChgFnshSta 0 "normal" 1 "abnormal finish by OBC" 2 "abnormal finish by BMS" 3 "abnormal finish by others" ;
VAL_ 2357404929 CHRG_ChrgFnshSta 0 "Normal" 1 "Charge finished" 2 "Not used" 3 "Error indicator" ;
VAL_ 2357404929 CHRG_Ig3RlyOffReq 0 "Not Request" 1 "Request" 2 "Not used" 3 "Error indicator" ;
VAL_ 2357404929 CHRG_PShftChgSta 0 "Normal" 1 "P Shift For Charging" 2 "Not used" 3 "Error indicator" ;
VAL_ 2357404929 CHRG_PilotFlSta 0 "Normal" 1 "Notify Pilotline Fail" 2 "Not used" 3 "Error indicator" ;
VAL_ 2357404930 CHRG_ObcRlyOnSta 0 "Off" 1 "On" 2 "Not used" 3 "Error indicator" ;
VAL_ 2357404930 CHRG_NrmlOpSta 0 "Normal(repetitive change), Abnormal(fixed)" 1 "Normal(repetitive change), Abnormal(fixed)" ;
VAL_ 2357404930 CHRG_ChgLamp_1EA 0 "no connection" 1 "charging" 2 "charge completion" 3 "charging fail" 4 "reservation mode" ;
VAL_ 2357404932 CHRG_ChrgLmp_3EA 0 "Normal" 1 "Main Rly On Status On" 2 "SOC 0~35%" 3 "SOC 35~65%" 4 "SOC 65%~" 5 "Chargnig Complete" 6 "Charging Fail" 7 "Reservation Charging,OBC standby mode" ;
VAL_ 1079 CTM_TrailerAct 0 "Not Connected" 1 "Connected" 2 "Reserved" 3 "Invaild" ;
VAL_ 1079 CTM_ExtTailLmpLftOpnSta 0 "Normal" 1 "Open Status" 2 "Not Used" 3 "Error Indicator" ;
VAL_ 1079 CTM_ExtTailLmpRtOpnSta 0 "Normal" 1 "Open Status" 2 "Not Used" 3 "Error Indicator" ;
VAL_ 1079 CTM_Exra_EbrakSta 0 "Off" 1 "On" 2 "Not Used" 3 "Error Indicator" ;
VAL_ 1079 CTM_TrlAngl_200ms 65535 "Error Indicator" ;
VAL_ 1079 CTM_RearfogAct 0 "Off" 1 "On" 2 "Reserved" 3 "Invaild" ;
VAL_ 1079 CTM_StpLmpOpnSta 0 "Normal" 1 "Open Status" 2 "Not Used" 3 "Error Indicator" ;
VAL_ 1079 CTM_TrnSigLmpLftOpnSta 0 "Normal" 1 "Open Status" 2 "Not Used" 3 "Error Indicator" ;
VAL_ 1079 CTM_TrnSigLmpRtOpnSta 0 "Normal" 1 "Open Status" 2 "Not Used" 3 "Error Indicator" ;
VAL_ 1085 DLBCU_ActiveDis 0 "Default" 1 "Off" 2 "Mode1" 3 "Mode2" 4 "Mode3" 5 "RESERVED" 6 "RESERVED" 7 "Invalid" ;
VAL_ 1085 DLBCU_CellOpt 0 "Default" 1 "3Cell" 2 "5Cell" 3 "7Cell" 4 "RESERVED" 5 "RESERVED" 6 "RESERVED" 7 "Invalid" ;
VAL_ 1085 DLBCU_BodySpprtSta 0 "Default" 1 "Off" 2 "On" 3 "Invalid" ;
VAL_ 1085 DLBCU_BodySpprtDis 0 "Default" 1 "Off" 2 "On" 3 "Invalid" ;
VAL_ 1085 DLBCU_MoodTrpyRValueSet 0 "Default" 1 "Off" 2 "On" 3 "Invalid" ;
VAL_ 1085 DLBCU_MoodTrpyCareSta 0 "Default" 1 "Off" 2 "On" 3 "Invalid" ;
VAL_ 1085 DLBCU_SmartCtrl_Set_Rvalue 0 "Init" 1 "Off" 2 "10min" 3 "20min" 4 "30min" 5 "40min" 6 "50min" 7 "60min" 8 "RESERVED" 9 "RESERVED" 10 "RESERVED" 11 "RESERVED" 12 "RESERVED" 13 "RESERVED" 14 "RESERVED" 15 "Invalid" ;
VAL_ 1085 DLBCU_DrvModUSMSta 0 "Default" 1 "Off" 2 "On" 3 "Invalid" ;
VAL_ 1085 DLBCU_MoodTrpyComfSta 0 "Default" 1 "Off" 2 "On" 3 "Invalid" ;
VAL_ 1085 DLBCU_ActiveStrSta 0 "Default" 1 "Normal" 2 "Intensity" 3 "Invalid" ;
VAL_ 1085 DLBCU_ActiveTimeSta 0 "Default" 1 "10min" 2 "15min" 3 "20min" 4 "RESERVED" 5 "RESERVED" 6 "RESERVED" 7 "Invalid" ;
VAL_ 2189468929 ECS_Crc4Val 0 "0x0x0~0xFFFF:CRCValue" 65535 "0x0x0~0xFFFF:CRCValue" ;
VAL_ 2189468929 ECS_AlvCnt4Val 0 "0x0x0~0xFF:AlvCntValue" 255 "0x0x0~0xFF:AlvCntValue" ;
VAL_ 2189468930 ECSIVSS_EcuLongAccelSnsrVal 0 "0x0x0000~0x0FFD:-20.48~20.45 (m/s©÷)" 4093 "0x0x0000~0x0FFD:-20.48~20.45 (m/s©÷)" 4094 "Not used" 4095 "Invalid" ;
VAL_ 2189468930 ECSIVSS_EcuLatAccelSnsrVal 0 "0x0x0000~0x0FFD:-20.48~20.45 (m/s©÷)" 4093 "0x0x0000~0x0FFD:-20.48~20.45 (m/s©÷)" 4094 "Not used" 4095 "Invalid" ;
VAL_ 2189468930 ECSIVSS_EcuVertAccelSnsrVal 0 "0x0x0000~0x0FFD:-20.48~20.45 (m/s©÷)" 4093 "0x0x0000~0x0FFD:-20.48~20.45 (m/s©÷)" 4094 "Not used" 4095 "Invalid" ;
VAL_ 2189468930 ECSIVSS_RdIndxVal 0 "Normal" 1 "Small Rough" 2 "Small Wave" 4 "Bump" 8 "Big Rough" 10 "Long Wave" 14 "Not used" 15 "Invalid" ;
VAL_ 2189468931 ECSIVSS_EcuRollGyroSnsrVal 0 "0x0x0000~0x0FFD:-204.8~204.5 (deg/s)" 4093 "0x0x0000~0x0FFD:-204.8~204.5 (deg/s)" 4094 "Not used" 4095 "Invalid" ;
VAL_ 2189468931 ECSIVSS_EcuPitchGyroSnsrVal 0 "0x0x0000~0x0FFD:-204.8~204.5 (deg/s)" 4093 "0x0x0000~0x0FFD:-204.8~204.5 (deg/s)" 4094 "Not used" 4095 "Invalid" ;
VAL_ 2189468931 ECSIVSS_EcuYawGyroSnsrVal 0 "0x0x0000~0x0FFD:-204.8~204.5 (deg/s)" 4093 "0x0x0000~0x0FFD:-204.8~204.5 (deg/s)" 4094 "Not used" 4095 "Invalid" ;
VAL_ 2189468931 ECSEMCU_PrvMode 0 "0" 1 "1" 2 "2" 3 "3" 4 "RESERVED" 5 "RESERVED" 6 "RESERVED" 7 "RESERVED" 8 "RESERVED" 9 "RESERVED" 10 "RESERVED" 11 "RESERVED" 12 "RESERVED" 13 "RESERVED" 14 "RESERVED" 15 "Invalid" ;
VAL_ 2189468931 ECSEMCU_PrvECSflag 0 "0" 1 "1" 2 "2" 3 "3" 4 "4" 5 "5" 6 "RESERVED" 7 "RESERVED" 8 "RESERVED" 9 "RESERVED" 10 "RESERVED" 11 "RESERVED" 12 "RESERVED" 13 "RESERVED" 14 "RESERVED" 15 "Invalid" ;
VAL_ 2164278529 HTCU_TrgtGearSta 0 "If N or P are detected(No frictional conncetion)" 1 "1st speed" 2 "2nd speed" 3 "3rd speed" 4 "4th speed" 5 "5th speed" 6 "6th speed" 7 "Reverse" 15 "--" ;
VAL_ 2164278529 HTCU_RdySta 0 "Not ready" 1 "Ready" 2 "Not used" 3 "Error Indicator" ;
VAL_ 2164278529 HTCU_GearChgSta 0 "Inactive" 1 "Active" 2 "Not used" 3 "Error Indicator" ;
VAL_ 2164278529 HTCU_FltSta 0 "No fault" 1 "TCU Diagnostic failure" 2 "Not used" 3 "TCU Diagnostic failure & Limphome activated" 4 "OPU/EOP Diagnostic failure" 5 "TCU & OPU/EOP Diagnostic failure" 6 "Not used" 7 "TCU/OPU Diagnostic failure & Limphome activated" ;
VAL_ 2164278529 HTCU_GearSlctrDis 0 "P" 1 "L" 2 "2" 3 "3" 4 "DS Mode" 5 "D" 6 "N" 7 "R" 8 "Sports mode / Manual Shift" 9 "Not display at Cluster" 10 "Sub-Rom Communication" 11 "Sub-Rom Communication Error" 12 "Paddle shift (D-Position)" 13 "Not used" 14 "Intermediate Position" 15 "Fault" ;
VAL_ 2164278529 HTCU_PddlShftUpDn 0 "Not Request" 1 "Paddle Plus" 2 "Paddle Minus" 3 "RESERVED" ;
VAL_ 2164278529 HTCU_FanCtrlReq 0 "Not Request" 1 "Request" 2 "Not Used" 3 "Error Indicator" ;
VAL_ 2164278530 HTCU_TrgtShftClsCCanSta 0 "NO SHIFT" 1 "PON UP" 2 "POF UP" 3 "PON DN@HIGH SPEED(Not Used)" 4 "PON DN@LOW SPEED" 5 "POF DN" 6 "NSTP TO 5/4/3/2" 7 "NSTP TO 1" 8 "LOW_VSP SFT12" 9 "N-D 12" 10 "N-D 3456" 11 "N-D5(NOT USED)" 12 "N-R" 13 "N-N" 14 "PON DN WOT SHIFT (NOT USED)" 15 "PON DN SEMI SHIFT" 16 "D-N/R-N" 17 "RESERVED" 18 "RESERVED" 19 "RESERVED" 20 "FAILSAFE 2-3-4 SHIFT" 21 "RESERVED" 22 "RESERVED" 23 "RESERVED" 24 "RESERVED" 25 "RESERVED" 26 "RESERVED" 27 "RESERVED" 28 "RESERVED" 29 "RESERVED" 30 "RESERVED" 31 "RESERVED" ;
VAL_ 2164278530 HTCU_CtrlablSta 0 "Not ready" 1 "TCU Controllable" 2 "Not Used" 3 "Error Indicator" ;
VAL_ 2164278530 HTCU_PrgrmSta 0 "PR_NML" 1 "PR_MED" 2 "PR_SPTY" 3 "PR_LD1" 4 "PR_LD2" 5 "PR_LD3" 6 "PR_DLD" 7 "PR_LD1_H" 8 "PR_LD2_H" 9 "PR_LD3_H" 10 "PR_PRT" 11 "PR_WRM_UP" 12 "PR_BLUE" 13 "PR_ECO_ATC" 14 "PR_LD_ATC" 15 "PR_LD_ATC_H" 16 "PR_HWY" 17 "PR_SOL_L" 18 "PR_SOL_M" 19 "PR_SOL_H" 20 "PR_REGEN" 21 "PR_TF_LO" 22 "PR_TCS" 23 "PR_LD_TCS" 24 "PR_DS" 25 "PR_EV_BLUE" 26 "PR_EV_NML" 27 "PR_EV_SOC_H" 28 "PR_EV_SOC_L" 29 "PR_EV_HWY" 30 "PR_SOS" 31 "PR_ECO_ATC_EV" 32 "PR_LD_ATC_EV" 33 "PR_LD_ATC_HI_EV" 34 "PR_LD2_ATC" 35 "PR_LD3_ATC" 36 "PR_LD2_ATC_H" 37 "PR_LD3_ATC_H" 38 "PR_EC_PRT" ;
VAL_ 2164278530 HTCU_FsCltchLmphmActvSta 0 "Inactive" 1 "Active" 2 "Not used" 3 "Error Indicator" ;
VAL_ 2164278531 HTCU_RapidKDReq 0 "Inactive" 1 "Active" 2 "Not used" 3 "Error Indicator" ;
VAL_ 2164278531 HTCU_CurrGearSta 0 "If N or P are detected(No frictional conncetion)" 1 "1st speed" 2 "2nd speed" 3 "3rd speed" 4 "4th speed" 5 "5th speed" 6 "6th speed" 7 "Reverse" 8 "--" 15 "--" ;
VAL_ 2164278531 HTCU_GearShftUpDisGSI 0 "Gear Shiftup Display Off" 1 "Gear Shiftup Display On" 2 "Not used" 3 "Error Indicator" ;
VAL_ 2164278531 HTCU_GearShftDnDisGSI 0 "Gear Shiftdown Display Off" 1 "Gear Shiftdown Display On" 2 "Not used" 3 "Error Indicator" ;
VAL_ 2164278531 HTCU_TrgtGearStaGSI 0 "--" 1 "1st speed" 2 "2nd speed" 3 "3rd speed" 4 "4th speed" 5 "5th speed" 6 "6th speed" 7 "--" 8 "--" 9 "--" ;
VAL_ 2164278531 HTCU_SolBSta 0 "OFF" 1 "ON" 2 "Not used" 3 "Error Indicator" ;
VAL_ 1221 HU_ChgInCurrModSet 0 "Default" 1 "Maximum" 2 "Decreasing" 3 "Minimum" 4 "Reserved" 5 "Reserved" 6 "Reserved" 7 "Invalid" ;
VAL_ 1221 SWRC_Sensitivity_SET 0 "Medium(default)" 1 "Low" 2 "High" 3 "Invalid" ;
VAL_ 1221 HU_EV_WinterMode 0 "Winter mode Off" 1 "Winter mode On" 2 "Reserved" 3 "Invalid" ;
VAL_ 1221 HU_TgSoc_ScChg_Set 0 "0x0x0~0xC8:PHY = HEX * 0.5" 200 "0x0x0~0xC8:PHY = HEX * 0.5" 201 "Reserved" 202 "Reserved" 203 "Reserved" 204 "Reserved" 205 "Reserved" 206 "Reserved" 207 "Reserved" 208 "Reserved" 209 "Reserved" 210 "Reserved" 211 "Reserved" 212 "Reserved" 213 "Reserved" 214 "Reserved" 215 "Reserved" 216 "Reserved" 217 "Reserved" 218 "Reserved" 219 "Reserved" 220 "Reserved" 221 "Reserved" 222 "Reserved" 223 "Reserved" 224 "Reserved" 225 "Reserved" 226 "Reserved" 227 "Reserved" 228 "Reserved" 229 "Reserved" 230 "Reserved" 231 "Reserved" 232 "Reserved" 233 "Reserved" 234 "Reserved" 235 "Reserved" 236 "Reserved" 237 "Reserved" 238 "Reserved" 239 "Reserved" 240 "Reserved" 241 "Reserved" 242 "Reserved" 243 "Reserved" 244 "Reserved" 245 "Reserved" 246 "Reserved" 247 "Reserved" 248 "Reserved" 249 "Reserved" 250 "Reserved" 251 "Reserved" 252 "Reserved" 253 "Reserved" 254 "Reserved" 255 "Invalid" ;
VAL_ 1221 HU_TgSoc_QcChg_Set 0 "0x0x0~0xC8:PHY = HEX * 0.5" 200 "0x0x0~0xC8:PHY = HEX * 0.5" 201 "Reserved" 202 "Reserved" 203 "Reserved" 204 "Reserved" 205 "Reserved" 206 "Reserved" 207 "Reserved" 208 "Reserved" 209 "Reserved" 210 "Reserved" 211 "Reserved" 212 "Reserved" 213 "Reserved" 214 "Reserved" 215 "Reserved" 216 "Reserved" 217 "Reserved" 218 "Reserved" 219 "Reserved" 220 "Reserved" 221 "Reserved" 222 "Reserved" 223 "Reserved" 224 "Reserved" 225 "Reserved" 226 "Reserved" 227 "Reserved" 228 "Reserved" 229 "Reserved" 230 "Reserved" 231 "Reserved" 232 "Reserved" 233 "Reserved" 234 "Reserved" 235 "Reserved" 236 "Reserved" 237 "Reserved" 238 "Reserved" 239 "Reserved" 240 "Reserved" 241 "Reserved" 242 "Reserved" 243 "Reserved" 244 "Reserved" 245 "Reserved" 246 "Reserved" 247 "Reserved" 248 "Reserved" 249 "Reserved" 250 "Reserved" 251 "Reserved" 252 "Reserved" 253 "Reserved" 254 "Reserved" 255 "Invalid" ;
VAL_ 1221 HU_UserApproval 0 "Initial Value" 1 "Approve" 2 "Reject" 3 "Start Trigger" 4 "Unrecognized Reject" 5 "RESERVED" 6 "RESERVED" 7 "RESERVED" 8 "RESERVED" 9 "RESERVED" 10 "RESERVED" 11 "RESERVED" 12 "RESERVED" 13 "RESERVED" 14 "Implement Check" 15 "Invalid" ;
VAL_ 1221 HU_OtaInfomationReq 0 "Initial" 1 "Vehicle S/W Version" 2 "What's New (Text Only)" 3 "Download progress" 4 "Update progress" 5 "Reserved" 6 "Reserved" 7 "Reserved" 8 "Reserved" 9 "Reserved" 10 "Reserved" 11 "Reserved" 12 "Reserved" 13 "Reserved" 14 "Reserved" 15 "Invalid" ;
VAL_ 1076 IAU_ProfileIDRVal 0 "Default" 1 "Guest" 2 "Profile1" 3 "Profile2" 4 "Profile3" 5 "Profile4" 6 "Profile5" 7 "Profile6" 8 "Profile7" 9 "Profile8" 10 "Profile9" 11 "RESERVED" 12 "RESERVED" 13 "RESERVED" 14 "RESERVED" 15 "INVALID" ;
VAL_ 1076 IAU_DigitalKeyProcessingSta 0 "None" 1 "DeviceOnWPC" 2 "DeviceRegistering" 3 "PhoneRegistered" 4 "All Phone Key Deleted" 5 "NFCCard1Registered" 6 "Server Registering" 7 "NFCCard1Deleted" 8 "BLE Searching" 9 "Owner Phone key Deleted" 10 "Valet Off Searching" 11 "Server Registering Fail" 12 "All Digital Keys in group Deleted" 15 "Invalid" ;
VAL_ 1076 IAU_DigitalKeyExit 0 "Normal" 1 "Check System" 2 "NFC Not Detected" 3 "Fob Not Detected" 4 "Canceled by User (Timeout)" 5 "Device not Available" 6 "ProcessFail" 7 "Check Card Save" 8 "Certificate Update" 9 "Valet Off Fail" 10 "CardNotAvailable" 11 "DigitalKeyDisabled" 12 "Retry After Parking" 13 "Check Password" 14 "P position fail (not P)" 15 "Invalid" ;
VAL_ 1076 IAU_DigitalKeyEnblRVal 0 "Default" 1 "Disable" 2 "Enable" 3 "Invalid" ;
VAL_ 1076 IAU_OwnerPhnRegRVal 0 "Default" 1 "Disable" 2 "Enable" 3 "Invalid" ;
VAL_ 1076 IAU_NFCCard1RegRVal 0 "Default" 1 "Disable" 2 "Enable" 3 "Invalid" ;
VAL_ 1076 IAU_NFCCard2RegRVal 0 "Default" 1 "Disable" 2 "Enable" 3 "Invalid" ;
VAL_ 1076 IAU_DISPWrng 0 "None" 1 "Auth_Fail2 (DigitalKey)" 2 "ReAuth_Warning" 3 "IAU Error" 4 "DigitalKey Saved" 5 "Auth_Fail2 (FP)" 6 "Auth_Fail2 (DigitalKey or FP)" 7 "BiometricKey Saved" 8 "DigitalKey and BiometricKey Saved" 9 "WPCNFC_PreStartAuth_Success" 10 "Reserved" 11 "Reserved" 12 "Reserved" 13 "Reserved" 14 "ReAuth_forRSPA" 15 "Invalid" ;
VAL_ 1076 IAU_DigitalKey2Opt 0 "Default (Not applied)" 1 "Digital Key Light (NFC)" 2 "Digital Key Medium (NFC/BLE)" 3 "Digital Key Full (NFC/BLE/UWB)" 4 "Reserved" 5 "Reserved" 6 "Reserved" 7 "invalid" ;
VAL_ 1076 IAUwFRULearnState 0 "Default (Normal)" 1 "Learning" 2 "Neutralizing" 3 "Invalid" ;
VAL_ 1076 IAUwFPMLearnState 0 "Default(Normal)" 1 "Learning" 2 "Neutralizing" 3 "Invalid" ;
VAL_ 2281833729 ICSC_Crc2Val 0 "0x0x0~0xFFFF:CRCValue" 65535 "0x0x0~0xFFFF:CRCValue" ;
VAL_ 2281833729 ICSC_AlvCnt2Val 0 "0x0x0~0xFF:AlvCntValue" 255 "0x0x0~0xFF:AlvCntValue" ;
VAL_ 2281833729 DMIC_DrvModSta 0 "Individual" 1 "Snow" 2 "Comfort(Normal)" 3 "Comfort+(Comfort)" 4 "ECO" 5 "Sport" 6 "Sport+" 7 "Smart" 8 "VIP" 9 "Baby" 10 "N(or GT)" 11 "RESERVED" 12 "RESERVED" 13 "RESERVED" 14 "RESERVED" 15 "Error Indicator" ;
VAL_ 2281833729 DMIC_SmtShftModSta 0 "OFF" 1 "ON" 2 "RESERVED" 3 "Error Indicator" ;
VAL_ 2281833729 DMIC_4wdLocking 0 "OFF" 1 "ON" 2 "INVALID" 3 "RESERVED" ;
VAL_ 2281833729 DMIC_EngModSta 0 "0FF" 1 "ON" 2 "Comfort(Normal)" 3 "Comfort+(Comfort)" 4 "ECO" 5 "Sport" 6 "Sport+" 7 "Smart" 8 "VIP" 9 "Baby" 10 "Snow" 11 "Retro" 12 "RESERVED" 13 "RESERVED" 14 "RESERVED" 15 "Error Indicator" ;
VAL_ 2281833729 DMIC_IndEngModSta 0 "0FF" 1 "ON" 2 "Comfort(Normal)" 3 "Comfort+(Comfort)" 4 "ECO" 5 "Sport" 6 "Sport+" 7 "Smart" 8 "VIP" 9 "Baby" 10 "Snow" 11 "RESERVED" 12 "RESERVED" 13 "RESERVED" 14 "RESERVED" 15 "Error Indicator" ;
VAL_ 2281833729 DMIC_TmModSta 0 "0FF" 1 "ON" 2 "Comfort(Normal)" 3 "Comfort+(Comfort)" 4 "ECO" 5 "Sport" 6 "Sport+" 7 "Smart" 8 "VIP" 9 "Baby" 10 "Snow" 11 "Retro" 12 "RESERVED" 13 "RESERVED" 14 "RESERVED" 15 "Error Indicator" ;
VAL_ 2281833729 DMIC_IndTmModSta 0 "0FF" 1 "ON" 2 "Comfort(Normal)" 3 "Comfort+(Comfort)" 4 "ECO" 5 "Sport" 6 "Sport+" 7 "Smart" 8 "VIP" 9 "RESERVED" 10 "RESERVED" 11 "RESERVED" 12 "RESERVED" 13 "RESERVED" 14 "RESERVED" 15 "Error Indicator" ;
VAL_ 2281833729 DMIC_EscModSta 0 "0FF" 1 "ON" 2 "Comfort(Normal)" 3 "Comfort+(Comfort)" 4 "ECO" 5 "Sport" 6 "Sport+" 7 "Smart" 8 "VIP" 9 "Baby" 10 "Snow" 11 "Retro" 12 "RESERVED" 13 "RESERVED" 15 "Error Indicator" ;
VAL_ 2281833729 DMIC_IndEscModSta 0 "0FF" 1 "ON" 2 "Comfort(Normal)" 3 "Comfort+(Comfort)" 4 "ECO" 5 "Sport" 6 "Sport+" 7 "Smart" 8 "RESERVED" 9 "RESERVED" 10 "RESERVED" 11 "RESERVED" 12 "RESERVED" 13 "RESERVED" 14 "RESERVED" 15 "Error Indicator" ;
VAL_ 2281833729 DMIC_MdpsModSta 0 "0FF" 1 "ON" 2 "Comfort(Normal)" 3 "Comfort+(Comfort)" 4 "ECO" 5 "Sport" 6 "Sport+" 7 "Smart" 8 "VIP" 9 "Baby" 10 "Snow" 11 "Retro" 12 "RESERVED" 13 "RESERVED" 14 "RESERVED" 15 "Error Indicator" ;
VAL_ 2281833729 DMIC_IndMdpsModSta 0 "0FF" 1 "ON" 2 "Comfort(Normal)" 3 "Comfort+(Comfort)" 4 "ECO" 5 "Sport" 6 "Sport+" 7 "Smart" 8 "VIP" 9 "RESERVED" 10 "RESERVED" 11 "RESERVED" 12 "RESERVED" 13 "RESERVED" 14 "RESERVED" 15 "Error Indicator" ;
VAL_ 2281833730 DMIC_EcsModSta 0 "0FF" 1 "ON" 2 "Comfort(Normal)" 3 "Comfort+(Comfort)" 4 "ECO" 5 "Sport" 6 "Sport+" 7 "Smart" 8 "VIP" 9 "Baby" 10 "Snow" 11 "Retro" 12 "RESERVED" 13 "RESERVED" 14 "RESERVED" 15 "Error Indicator" ;
VAL_ 2281833730 DMIC_IndAwdModSta 0 "0FF" 1 "ON" 2 "Comfort(Normal)" 3 "Comfort+(Comfort)" 4 "ECO" 5 "Sport" 6 "Sport+" 7 "Smart" 8 "RESERVED" 9 "RESERVED" 10 "RESERVED" 11 "RESERVED" 12 "RESERVED" 13 "RESERVED" 14 "RESERVED" 15 "Error Indicator" ;
VAL_ 2281833730 DMIC_RevModSta 0 "0FF" 1 "ON" 2 "Comfort(Normal)" 3 "Comfort+(Comfort)" 4 "ECO" 5 "Sport" 6 "Sport+" 7 "Smart" 8 "VIP" 9 "Baby" 10 "Snow" 11 "Retro" 12 "RESERVED" 13 "RESERVED" 14 "RESERVED" 15 "Error Indicator" ;
VAL_ 2281833730 DMIC_IndRevModSta 0 "0FF" 1 "ON" 2 "Comfort(Normal)" 3 "Comfort+(Comfort)" 4 "ECO" 5 "Sport" 6 "Sport+" 7 "Smart" 8 "RESERVED" 9 "RESERVED" 10 "RESERVED" 11 "RESERVED" 12 "RESERVED" 13 "RESERVED" 14 "RESERVED" 15 "Error Indicator" ;
VAL_ 2281833730 DMIC_PrflModSta 0 "ON-OFF" 1 "ON-ON" 2 "OFF-OFF" 3 "OFF-ON" 4 "RESERVED" 5 "RESERVED" 6 "RESERVED" 7 "RESERVED" 8 "RESERVED" 9 "RESERVED" 10 "RESERVED" 11 "RESERVED" 12 "RESERVED" 13 "RESERVED" 14 "RESERVED" 15 "Error Indicator" ;
VAL_ 2281833730 DMIC_IndPrflModSta 0 "OFF" 1 "ON" 2 "RESERVED" 3 "RESERVED" 4 "RESERVED" 5 "RESERVED" 6 "RESERVED" 7 "RESERVED" 8 "RESERVED" 9 "RESERVED" 10 "RESERVED" 11 "RESERVED" 12 "RESERVED" 13 "RESERVED" 14 "RESERVED" 15 "Error Indicator" ;
VAL_ 2281833730 DMIC_ElsdModSta 0 "0FF" 1 "ON" 2 "Comfort(Normal)" 3 "Comfort+(Comfort)" 4 "ECO" 5 "Sport" 6 "Sport+" 7 "Smart" 8 "VIP" 9 "Baby" 10 "Snow" 11 "Retro" 12 "RESERVED" 13 "RESERVED" 14 "RESERVED" 15 "Error Indicator" ;
VAL_ 2281833730 DMIC_IndElsdModSta 0 "0FF" 1 "ON" 2 "Comfort(Normal)" 3 "Comfort+(Comfort)" 4 "ECO" 5 "Sport" 6 "Sport+" 7 "Smart" 8 "RESERVED" 9 "RESERVED" 10 "RESERVED" 11 "RESERVED" 12 "RESERVED" 13 "RESERVED" 14 "RESERVED" 15 "Error Indicator" ;
VAL_ 2281833730 DMIC_IndEcsModSta 0 "0FF" 1 "ON" 2 "Comfort(Normal)" 3 "Comfort+(Comfort)" 4 "ECO" 5 "Sport" 6 "Sport+" 7 "Smart" 8 "VIP" 9 "RESERVED" 10 "RESERVED" 11 "RESERVED" 12 "RESERVED" 13 "RESERVED" 14 "RESERVED" 15 "Error Indicator" ;
VAL_ 2281833730 DMIC_EsndModSta 0 "0FF" 1 "ON" 2 "Comfort(Normal)" 3 "Comfort+(Comfort)" 4 "ECO" 5 "Sport" 6 "Sport+" 7 "Smart" 8 "VIP" 9 "Baby" 10 "Snow" 11 "Retro" 12 "RESERVED" 13 "RESERVED" 14 "RESERVED" 15 "Error Indicator" ;
VAL_ 2281833730 DMIC_IndEsndModSta 0 "0FF" 1 "ON" 2 "Comfort(Normal)" 3 "Comfort+(Comfort)" 4 "ECO" 5 "Sport" 6 "Sport+" 7 "Smart" 8 "RESERVED" 9 "RESERVED" 10 "RESERVED" 11 "RESERVED" 12 "RESERVED" 13 "RESERVED" 14 "RESERVED" 15 "Error Indicator" ;
VAL_ 2281833730 DMIC_RwsModSta 0 "0FF" 1 "ON" 2 "Comfort(Normal)" 3 "Comfort+(Comfort)" 4 "ECO" 5 "Sport" 6 "Sport+" 7 "Smart" 8 "VIP" 9 "Baby" 10 "Snow" 11 "Retro" 12 "RESERVED" 13 "RESERVED" 14 "RESERVED" 15 "Error Indicator" ;
VAL_ 2281833730 DMIC_IndRwsModSta 0 "0FF" 1 "ON" 2 "Comfort(Normal)" 3 "Comfort+(Comfort)" 4 "ECO" 5 "Sport" 6 "Sport+" 7 "Smart" 8 "RESERVED" 9 "RESERVED" 10 "RESERVED" 11 "RESERVED" 12 "RESERVED" 13 "RESERVED" 14 "RESERVED" 15 "Error Indicator" ;
VAL_ 2281833730 DMIC_DrvCtrAppSta 0 "OFF" 1 "ON" 2 "RESERVED" 3 "RESERVED" ;
VAL_ 2281833730 DMIC_EscOffStaAppTyp 0 "Default" 1 "Case1" 2 "Case2" 3 "RESERVED" ;
VAL_ 2281833730 DMIC_AwdModSta 0 "0FF" 1 "ON" 2 "Comfort(Normal)" 3 "Comfort+(Comfort)" 4 "ECO" 5 "Sport" 6 "Sport+" 7 "Smart" 8 "VIP" 9 "Baby" 10 "Snow" 11 "Retro" 12 "RESERVED" 13 "RESERVED" 14 "RESERVED" 15 "Error Indicator" ;
VAL_ 2281833731 DMIC_VcuModSta 0 "0FF" 1 "ON" 2 "Comfort(Normal)" 3 "Comfort+(Comfort)" 4 "ECO" 5 "Sport" 6 "Sport+" 7 "Smart" 8 "VIP" 9 "Baby" 10 "Snow" 11 "Retro" 12 "RESERVED" 13 "RESERVED" 14 "RESERVED" 15 "Error Indicator" ;
VAL_ 2281833731 DMIC_DrvModTyp 0 "Default" 1 "Drive Mode Case1" 2 "Drive Mode Case2" 3 "Drive Mode Case3" 4 "Drive Mode Case4" 5 "Drive Mode Case5" 6 "Drive Mode Case6" 7 "Drive Mode Case7" 8 "Drive Mode Case8" 9 "Drive Mode Case9" 10 "Drive Mode Case10" 11 "Drive Mode Case11" 12 "Drive Mode Case12" 13 "Drive Mode Case13" 14 "Drive Mode Case14" 15 "Invalid" ;
VAL_ 2281833731 DMIC_EngFltSta 0 "Not defective" 1 "Defective" 2 "RESERVED" 3 "Error Indicator" ;
VAL_ 2281833731 DMIC_TmFltSta 0 "Not defective" 1 "Defective" 2 "RESERVED" 3 "Error Indicator" ;
VAL_ 2281833731 DMIC_EscFltSta 0 "Not defective" 1 "Defective" 2 "RESERVED" 3 "Error Indicator" ;
VAL_ 2281833731 DMIC_MdpsFltSta 0 "Not defective" 1 "Defective" 2 "RESERVED" 3 "Error Indicator" ;
VAL_ 2281833731 DMIC_EcsFltSta 0 "Not defective" 1 "Defective" 2 "RESERVED" 3 "Error Indicator" ;
VAL_ 2281833731 DMIC_AwdFltSta 0 "Not defective" 1 "Defective" 2 "RESERVED" 3 "Error Indicator" ;
VAL_ 2281833731 DMIC_RevFltSta 0 "Not defective" 1 "Defective" 2 "RESERVED" 3 "Error Indicator" ;
VAL_ 2281833731 DMIC_PrflFltSta 0 "Not defective" 1 "Defective" 2 "RESERVED" 3 "Error Indicator" ;
VAL_ 2281833731 DMIC_ElsdFltSta 0 "Not defective" 1 "Defective" 2 "RESERVED" 3 "Error Indicator" ;
VAL_ 2281833731 DMIC_EsndFltSta 0 "Not defective" 1 "Defective" 2 "RESERVED" 3 "Error Indicator" ;
VAL_ 2281833731 DMIC_RwsFltSta 0 "Not defective" 1 "Defective" 2 "RESERVED" 3 "Error Indicator" ;
VAL_ 2281833731 DMIC_IndWhlDrvSta 0 "RESERVED" 1 "AUTO AWD" 2 "2WD" 3 "AWD" ;
VAL_ 2281833731 DMIC_IndVcuModSta 0 "0FF" 1 "ON" 2 "Comfort(Normal)" 3 "Comfort+(Comfort)" 4 "ECO" 5 "Sport" 6 "Sport+" 7 "Smart" 8 "VIP" 9 "RESERVED" 10 "RESERVED" 11 "RESERVED" 12 "RESERVED" 13 "RESERVED" 14 "RESERVED" 15 "Error Indicator" ;
VAL_ 2281833731 DMIC_VcuFltSta 0 "Not defective" 1 "Defective" 2 "RESERVED" 3 "Error Indicator" ;
VAL_ 2281833731 DMIC_IndMtrPwrSta 0 "RESERVED" 1 "Minimum" 2 "Moderate" 3 "Maximum" 4 "RESERVED" 5 "RESERVED" 6 "RESERVED" 7 "RESERVED" ;
VAL_ 2281833731 DMIC_IndAccSenSta 0 "RESERVED" 1 "Low" 2 "Moderate" 3 "High" 4 "RESERVED" 5 "RESERVED" 6 "RESERVED" 7 "RESERVED" ;
VAL_ 2281833731 DMIC_TerrainModSwSta 0 "Default" 1 "Snow" 2 "Sand" 3 "Mud" 4 "Auto" 5 "Deep Snow" 6 "Rock" 7 "RESERVED" ;
VAL_ 2281833731 DMIC_TerrainMainSwSta 0 "Default" 1 "On-Road" 2 "Off-Road" 3 "RESERVED" ;
VAL_ 2281833731 DMIC_DrvModTypSta 0 "Old DriveModeType" 1 "New DriveModeType" 2 "RESERVED" 3 "RESERVED" ;
VAL_ 2281833731 DMIC_DrvngModSwSta 0 "Off" 1 "Normal" 2 "Eco" 3 "Sport" 4 "Sport+" 5 "Smart" 6 "Custom(Custom#1_N)" 7 "N-mode(or GT mode)" 8 "Snow" 9 "Custom#2_N" 10 "Chauffeur" 11 "RESERVED" 12 "RESERVED" 13 "RESERVED" 14 "RESERVED" 15 "Invalid" ;
VAL_ 2281833731 DMIC_DrvMod2Typ 0 "Default" 1 "Drive Mode Case1" 2 "Drive Mode Case2" 3 "Drive Mode Case3" 4 "Drive Mode Case4" 5 "Drive Mode Case5" 6 "Drive Mode Case6" 7 "Drive Mode Case7" 8 "Drive Mode Case8" 9 "Drive Mode Case9" 10 "Drive Mode Case10" 11 "Drive Mode Case11" 12 "Drive Mode Case12" 13 "Drive Mode Case13" 14 "Drive Mode Case14" 15 "Invalid" ;
VAL_ 2281833731 DMIC_DrvModFltSta 0 "All mode available" 1 "Sport mode unavailable" 2 "ECO mode and Sport mode unavailable" 3 "Comfort(Normal) mode only available (The other modes unavailable)" 4 "RESERVED" 5 "RESERVED" 6 "RESERVED" 7 "RESERVED" 8 "RESERVED" 9 "RESERVED" 10 "RESERVED" 11 "RESERVED" 12 "RESERVED" 13 "RESERVED" 14 "RESERVED" 15 "Error Indicator" ;
VAL_ 1059 PSU_DiagSta 0 "Stop Diag" 1 "Start Diag" 2 "RESERVED" 3 "Error Indicator" ;
VAL_ 1059 Ast_2ndAutoRlxEnable 0 "Default" 1 "Enable" 2 "Disable" 3 "Invalid" ;
VAL_ 1059 Ast_AutoRlxSta 0 "Default" 1 "Auto Relaxion Moving" 2 "RESERVED" 3 "Invalid" ;
VAL_ 1059 Ast_2ndAutoFldEnable 0 "Default" 1 "Enable" 2 "Disable" 3 "Invalid" ;
VAL_ 1059 PSU_EsyAcsGetOnSta 0 "off" 1 "on" 2 "RESERVED" 3 "Error Indicator" ;
VAL_ 1059 PSU_EsyAcsGetOffSta 0 "off" 1 "on" 2 "RESERVED" 3 "Error Indicator" ;
VAL_ 1059 PSU_EsyAcsStpSta 0 "off" 1 "on" 2 "RESERVED" 3 "Error Indicator" ;
VAL_ 1059 PSU_RVal 0 "Default Value" 1 "Off(Disable)" 2 "Enable" 3 "RESERVED" 4 "RESERVED" 5 "RESERVED" 6 "RESERVED" 7 "Invalid" ;
VAL_ 1086 RL_CURTAIN_POSITION 0 "Bottom" 1 "Middle" 2 "Top" 3 "Unknown(Curtain not Initialized)" ;
VAL_ 1086 RDC_SWVerMinor1 0 "0x0x0~0x7F:ASCII Code Value (HEX)" 127 "0x0x0~0x7F:ASCII Code Value (HEX)" ;
VAL_ 1086 RDC_SWVerMinor2 0 "0x0x0~0x7F:ASCII Code Value (HEX)" 127 "0x0x0~0x7F:ASCII Code Value (HEX)" ;
VAL_ 1086 RR_CURTAIN_POSITION 0 "Bottom" 1 "Middle" 2 "Top" 3 "Unknown(Curtain not Initialized)" ;
VAL_ 1086 RDC_RLDNInitFlag 0 "Off" 1 "On" 2 "Not Used" 3 "Error Indicator" ;
VAL_ 1086 RDC_RRDNInitFlag 0 "Off" 1 "On" 2 "Not Used" 3 "Error Indicator" ;
VAL_ 1086 RDC_RLOpState 0 "Off" 1 "On" 2 "Not Used" 3 "Error Indicator" ;
VAL_ 1086 RDC_RROpState 0 "Off" 1 "On" 2 "Not Used" 3 "Error Indicator" ;
VAL_ 1086 RDC_OptTyp 0 "Default" 1 "RDC Option" 2 "Not Used" 3 "Error Indicator" ;
VAL_ 1086 RDC_SWVerMajor1 0 "0x0x0~0x7F:ASCII Code Value (HEX)" 127 "0x0x0~0x7F:ASCII Code Value (HEX)" ;
VAL_ 1068 RLPSU_ReclMtrPos 0 "Default" 1 "Zone1" 2 "Zone2" 3 "Zone3" 4 "Zone4" 5 "PE" 6 "RESERVED" 7 "Invalid" ;
VAL_ 1068 RLPSU_RLSlidPos 0 "Default" 1 "Front Ended Position" 2 "Operating Enable" 3 "Rear Ended Position" 4 "RESERVED" 5 "RESERVED" 6 "RESERVED" 7 "Invalid" ;
VAL_ 1068 RLPSU_RLRclPos 0 "Default" 1 "Front Ended Position" 2 "Operating Enable" 3 "Rear Ended Position" 4 "RESERVED" 5 "RESERVED" 6 "RESERVED" 7 "Invalid" ;
VAL_ 1068 RLPSU_RLTiltPos 0 "Default" 1 "Upper Ended Position" 2 "Operating Enable" 3 "Lower Ended Position" 4 "RESERVED" 5 "RESERVED" 6 "RESERVED" 7 "Invalid" ;
VAL_ 1068 RLPSU_RLLegExtPos 0 "Default" 1 "Front Ended Position" 2 "Operating Enable" 3 "Rear Ended Position" 4 "RESERVED" 5 "RESERVED" 6 "RESERVED" 7 "Invalid" ;
VAL_ 1068 RLPSU_RLLegSupPos 0 "Default" 1 "Upper Ended Position" 2 "Operating Enable" 3 "Lower Ended Position" 4 "RESERVED" 5 "RESERVED" 6 "RESERVED" 7 "Invalid" ;
VAL_ 1068 RLPSU_RLHrestSlidPos 0 "Default" 1 "Front Ended Position" 2 "Operating Enable" 3 "RearEndedPosition" 4 "RESERVED" 5 "RESERVED" 6 "RESERVED" 7 "Invalid" ;
VAL_ 1068 RLPSU_RLHrestHeightPos 0 "Default" 1 "Upper Ended Position" 2 "Operating Enable" 3 "Lower  Ended Position" 4 "RESERVED" 5 "RESERVED" 6 "RESERVED" 7 "Invalid" ;
VAL_ 1068 RLPSU_Opt 0 "Default" 1 "PWR&HVU(5P Slide)" 2 "PWR&HVU(7P Walkin)" 3 "Invalid" ;
VAL_ 1068 RLPSU_Opt_Captain 0 "Default" 1 "PWR&HVU(4P Slide)" 2 "PWR&HVU(6P Walkin)" 3 "Invalid" ;
VAL_ 1068 RL_AutoRlxSta 0 "Default" 1 "Auto Relaxion Moving" 2 "RESERVED" 3 "Invalid" ;
VAL_ 1068 RL_FLStAutoRlxEnable 0 "Default" 1 "Enable" 2 "Disable" 3 "Invalid" ;
VAL_ 1068 RLHVU_Opt_Captain 0 "Default" 1 "MNL&HU(4P Slide)" 2 "MNL&HU(6P Walkin)" 3 "MNL&HVU(4P Slide)" 4 "MNL&HVU(6P Walkin)" 5 "RESERVED" 6 "RESERVED" 7 "Invalid" ;
VAL_ 1068 RL_TLAutoFldEnable 0 "Default" 1 "Enable" 2 "Disable" 3 "Invalid" ;
VAL_ 1068 RL_AutoFoldSta 0 "Default" 1 "Auto Fold" 2 "UnFold Moving" 3 "Invalid" ;
VAL_ 1068 RL_AutoWalkInSta 0 "Default" 1 "Auto WalkIn" 2 "Return Moving" 3 "Invalid" ;
VAL_ 1068 RLPSU_PwrSeatOpt 0 "Default" 1 "5P" 2 "5P + SHVU" 3 "7P" 4 "7P + SHVU" 5 "9P" 6 "9P + SHVU" 7 "Invalid" ;
VAL_ 1068 RLPSU_PwrSeatPos 0 "Default" 1 "Front Ended Position" 2 "Moving Forward" 3 "Moving Backward" 4 "Rear Ended Position" 5 "RESERVED" 6 "RESERVED" 7 "Invalid" ;
VAL_ 1080 RL_SHVU_SeatOptSta 0 "Init" 1 "Heater only 2step" 2 "Heater only 3step" 3 "Vent only 2step" 4 "Vent only 3step" 5 "Heater and Vent 2step" 6 "Heater and Vent 3step" 7 "Invalid" ;
VAL_ 1080 RL_SHVU_SeatHtOperSta 0 "Init" 1 "RESERVED" 2 "Heater & Vent OFF" 3 "Vent Low" 4 "Vent Mid" 5 "Vent High" 6 "Heater Low" 7 "Heater Mid" 8 "Heater High" 9 "RESERVED" 10 "RESERVED" 11 "RESERVED" 12 "RESERVED" 13 "RESERVED" 14 "RESERVED" 15 "Invalid" ;
VAL_ 1080 RL_SHVU_HtSwHiIndSta_RHD 0 "OFF" 1 "ON" 2 "RESERVED" 3 "Error Indicator" ;
VAL_ 1080 RL_SHVU_HtSwMidIndSta_RHD 0 "OFF" 1 "ON" 2 "RESERVED" 3 "Error Indicator" ;
VAL_ 1080 RL_SHVU_HtSwLowIndSta_RHD 0 "OFF" 1 "ON" 2 "RESERVED" 3 "Error Indicator" ;
VAL_ 1080 RL_SHVU_VntSwHiIndSta_RHD 0 "OFF" 1 "ON" 2 "RESERVED" 3 "Error Indicator" ;
VAL_ 1080 RL_SHVU_VntSwMidIndSta_RHD 0 "OFF" 1 "ON" 2 "RESERVED" 3 "Error Indicator" ;
VAL_ 1080 RL_SHVU_VntSwLowIndSta_RHD 0 "OFF" 1 "ON" 2 "RESERVED" 3 "Error Indicator" ;
VAL_ 1080 RL_SHVU_HtBlcUsmSta_RHD 0 "Default" 1 "Normal" 2 "Back 1" 3 "Back 2" 4 "Back 3" 5 "Cush 1" 6 "Cush 2" 7 "Cush 3" 8 "RESERVED" 9 "RESERVED" 10 "RESERVED" 11 "RESERVED" 12 "RESERVED" 13 "RESERVED" 14 "RESERVED" 15 "Invaild" ;
VAL_ 1070 RL_SHVU_HtSwHiIndSta 0 "OFF" 1 "ON" 2 "RESERVED" 3 "Error Indicator" ;
VAL_ 1070 RL_SHVU_HtSwMidIndSta 0 "OFF" 1 "ON" 2 "RESERVED" 3 "Error Indicator" ;
VAL_ 1070 RL_SHVU_HtSwLowIndSta 0 "OFF" 1 "ON" 2 "RESERVED" 3 "Error Indicator" ;
VAL_ 1070 RL_SHVU_VntSwHiIndSta 0 "OFF" 1 "ON" 2 "RESERVED" 3 "Error Indicator" ;
VAL_ 1070 RL_SHVU_VntSwMidIndSta 0 "OFF" 1 "ON" 2 "RESERVED" 3 "Error Indicator" ;
VAL_ 1070 RL_SHVU_VntSwLowIndSta 0 "OFF" 1 "ON" 2 "RESERVED" 3 "Error Indicator" ;
VAL_ 1070 RL_SHVU_HtBlcUsmSta 0 "Default" 1 "Normal" 2 "Back 1" 3 "Back 2" 4 "Back 3" 5 "Cush 1" 6 "Cush 2" 7 "Cush 3" 8 "RESERVED" 9 "RESERVED" 10 "RESERVED" 11 "RESERVED" 12 "RESERVED" 13 "RESERVED" 14 "RESERVED" 15 "Invalid" ;
VAL_ 1069 RRPSU_ReclMtrPos 0 "Default" 1 "Zone1" 2 "Zone2" 3 "Zone3" 4 "Zone4" 5 "PE" 6 "RESERVED" 7 "Invalid" ;
VAL_ 1069 RRPSU_PwrSeatOpt 0 "Default" 1 "5P" 2 "5P + SHVU" 3 "7P" 4 "7P + SHVU" 5 "9P" 6 "9P + SHVU" 7 "Invalid" ;
VAL_ 1069 RRPSU_PwrSeatPos 0 "Default" 1 "Front Ended Position" 2 "Moving Forward" 3 "Moving Backward" 4 "Rear Ended Position" 5 "RESERVED" 6 "RESERVED" 7 "Invalid" ;
VAL_ 1069 RRPSU_RRSlidPos 0 "Default" 1 "Front Ended Position" 2 "Operating Enable" 3 "Rear Ended Position" 4 "RESERVED" 5 "RESERVED" 6 "RESERVED" 7 "Invalid" ;
VAL_ 1069 RRPSU_RRRclPos 0 "Default" 1 "Front Ended Position" 2 "Operating Enable" 3 "Rear Ended Position" 4 "RESERVED" 5 "RESERVED" 6 "RESERVED" 7 "Invalid" ;
VAL_ 1069 RRPSU_RRTiltPos 0 "Default" 1 "Upper Ended Position" 2 "Operating Enable" 3 "Lower Ended Position" 4 "RESERVED" 5 "RESERVED" 6 "RESERVED" 7 "Invalid" ;
VAL_ 1069 RRPSU_RRLegExtPos 0 "Default" 1 "Front Ended Position" 2 "Operating Enable" 3 "Rear Ended Position" 4 "RESERVED" 5 "RESERVED" 6 "RESERVED" 7 "Invalid" ;
VAL_ 1069 RRPSU_RRLegSupPos 0 "Default" 1 "Upper Ended Position" 2 "Operating Enable" 3 "Lower Ended Position" 4 "RESERVED" 5 "RESERVED" 6 "RESERVED" 7 "Invalid" ;
VAL_ 1069 RRPSU_RRStEsyAcsUSMSta 0 "Default" 1 "Off(Disable)" 2 "On(Enable)" 3 "RESERVED" 4 "RESERVED" 5 "RESERVED" 6 "RESERVED" 7 "Invalid" ;
VAL_ 1069 RRPSU_RRHrestSlidPos 0 "Default" 1 "Front Ended Position" 2 "Operating Enable" 3 "Rear Ended Position" 4 "RESERVED" 5 "RESERVED" 6 "RESERVED" 7 "Invalid" ;
VAL_ 1069 RRPSU_RRHrestHeightPos 0 "Default" 1 "Up Ended Position" 2 "Operating Enable" 3 "Down Ended Position" 4 "RESERVED" 5 "RESERVED" 6 "RESERVED" 7 "Invalid" ;
VAL_ 1069 RRPSU_Opt_Captain 0 "Default" 1 "PWR&HVU(4P Slide)" 2 "PWR&HVU(6P Walkin)" 3 "Invalid" ;
VAL_ 1069 RR_AutoRlxSta 0 "Default" 1 "Auto Relaxtion Moving" 2 "RESERVED" 3 "Invalid" ;
VAL_ 1069 RR_FRStAutoRlxEnable 0 "Default" 1 "Enable" 2 "Disable" 3 "Invalid" ;
VAL_ 1069 RRHVU_Opt_Captain 0 "Default" 1 "MNL&HU(4P Slide)" 2 "MNL&HU(6P Walkin)" 3 "MNL&HVU(4P Slide)" 4 "MNL&HVU(6P Walkin)" 5 "RESERVED" 6 "RESERVED" 7 "Invalid" ;
VAL_ 1069 RR_AutoFoldSta 0 "Default" 1 "Auto Fold" 2 "UnFold Moving" 3 "Invalid" ;
VAL_ 1069 RR_AutoWalkInSta 0 "Default" 1 "Auto WalkIn" 2 "Return Moving" 3 "Invalid" ;
VAL_ 1069 RR_TRAutoFldEnable 0 "Default" 1 "Enable" 2 "Disable" 3 "Invalid" ;
VAL_ 1069 RRPSU_RLStEsyAcsUSMSta 0 "Default" 1 "Off(Disable)" 2 "On(Enable)" 3 "RESERVED" 4 "RESERVED" 5 "RESERVED" 6 "RESERVED" 7 "Invalid" ;
VAL_ 1069 RRPSU_Opt 0 "Default" 1 "PWR&HVU(5P Slide)" 2 "PWR&HVU(7P Walkin)" 3 "Invalid" ;
VAL_ 1071 RR_SHVU_HtSwHiIndSta 0 "OFF" 1 "ON" 2 "RESERVED" 3 "Error indicator" ;
VAL_ 1071 RR_SHVU_HtSwMidIndSta 0 "OFF" 1 "ON" 2 "RESERVED" 3 "Error Indicator" ;
VAL_ 1071 RR_SHVU_HtSwLowIndSta 0 "OFF" 1 "ON" 2 "RESERVED" 3 "Error Indicator" ;
VAL_ 1071 RR_SHVU_VntSwHiIndSta 0 "OFF" 1 "ON" 2 "RESERVED" 3 "Error Indictor" ;
VAL_ 1071 RR_SHVU_VntSwMidIndSta 0 "OFF" 1 "ON" 2 "RESERVED" 3 "Error Indicator" ;
VAL_ 1071 RR_SHVU_VntSwLowIndSta 0 "OFF" 1 "ON" 2 "RESERVED" 3 "Error Indicator" ;
VAL_ 1071 RR_SHVU_HtBlcUsmSta 0 "Default" 1 "Normal" 2 "Back 1" 3 "Back 2" 4 "Back 3" 5 "Cush 1" 6 "Cush 2" 7 "Cush 3" 8 "RESERVED" 9 "RESERVED" 10 "RESERVED" 11 "RESERVED" 12 "RESERVED" 13 "RESERVED" 14 "RESERVED" 15 "Invalid" ;
VAL_ 1073 USM_ValCmdSta 0 "Default" 1 "Off(Disable)" 2 "On(Enable)" 3 "Invalid" ;
VAL_ 1073 RWPC_SWVerMinor1 0 "0x0x0~0x7F:ASCII Code Value (HEX)" 127 "0x0x0~0x7F:ASCII Code Value (HEX)" ;
VAL_ 1073 WPC_PhnLftWrngRWPCSta 0 "Off" 1 "Cellphone on the pad" 2 "Charging" 3 "Charging complete" 4 "Cellphone reminder" 5 "Error" 6 "NFC Card detected" 7 "Invalid" ;
VAL_ 1073 RWPC_SWVerMinor2 0 "0x0x0~0x7F:ASCII Code Value (HEX)" 127 "0x0x0~0x7F:ASCII Code Value (HEX)" ;
VAL_ 1073 RWPC_IndSyncVal 0 "default" 1 "off" 2 "1st sync" 3 "2nd sync" 4 "3rd sync" 5 "error off" 6 "error on" 7 "reserved" ;
VAL_ 1073 USM_ValCmdStaforATS 0 "Default" 1 "Off(Disable)" 2 "On(Enable)" 3 "Invalid" ;
VAL_ 1073 RWPC_SWVerMajor1 0 "0x0x0~0x7F:ASCII Code Value (HEX)" 127 "0x0x0~0x7F:ASCII Code Value (HEX)" ;
VAL_ 1067 SCM_SWVerMajor1 0 "0x0x0~0x7F:ASCII Code Value (HEX)" 127 "0x0x0~0x7F:ASCII Code Value (HEX)" ;
VAL_ 1067 SCM_SWVerMinor1 0 "0x0x0~0x7F:ASCII Code Value (HEX)" 127 "0x0x0~0x7F:ASCII Code Value (HEX)" ;
VAL_ 1067 SCM_SWVerMinor2 0 "0x0x0~0x7F:ASCII Code Value (HEX)" 127 "0x0x0~0x7F:ASCII Code Value (HEX)" ;
